VERSION "10.9.1"

NS_ :

BS_:

BU_: ADAS_Info AMP CPD DUMMY_DEBUG DUMMY_ECU EASC HUD MHU XGW_Info

BO_ 389 VCU_FS_C: 8 XGW_Info
 SG_ VCU_FS_C_1 : 0|1@0+ (1,0) [0|1] ""  MHU
 SG_ VCU_FS_C_2 : 1|1@0+ (1,0) [0|1] ""  MHU
 SG_ VCU_FS_C_3 : 2|1@0+ (1,0) [0|1] ""  MHU
 SG_ VCU_FS_C_4 : 3|1@0+ (1,0) [0|1] ""  MHU
 SG_ VCU_FS_C_5 : 4|1@0+ (1,0) [0|1] ""  MHU
 SG_ VCU_FS_C_6 : 5|1@0+ (1,0) [0|1] ""  MHU
 SG_ VCU_FS_C_7 : 6|1@0+ (1,0) [0|1] ""  MHU
 SG_ VCU_FS_C_8 : 7|1@0+ (1,0) [0|1] ""  MHU
 SG_ VCU_FS_C_9 : 8|1@0+ (1,0) [0|1] ""  MHU
 SG_ VCU_FS_C_10 : 9|1@0+ (1,0) [0|1] ""  MHU
 SG_ VCU_FS_C_11 : 10|1@0+ (1,0) [0|1] ""  MHU
 SG_ VCU_FS_C_12 : 11|1@0+ (1,0) [0|1] ""  MHU
 SG_ VCU_FS_C_13 : 12|1@0+ (1,0) [0|1] ""  MHU
 SG_ VCU_FS_C_14 : 13|1@0+ (1,0) [0|1] ""  MHU
 SG_ VCU_FS_C_15 : 14|1@0+ (1,0) [0|1] ""  MHU
 SG_ VCU_FS_C_16 : 15|1@0+ (1,0) [0|1] ""  MHU
 SG_ VCU_FS_C_17 : 16|1@0+ (1,0) [0|1] ""  MHU
 SG_ VCU_FS_C_18 : 17|1@0+ (1,0) [0|1] ""  MHU
 SG_ VCU_FS_C_19 : 18|1@0+ (1,0) [0|1] ""  MHU
 SG_ VCU_FS_C_20 : 19|1@0+ (1,0) [0|1] ""  MHU
 SG_ VCU_FS_C_21 : 20|1@0+ (1,0) [0|1] ""  MHU
 SG_ VCU_FS_C_22 : 21|1@0+ (1,0) [0|1] ""  MHU
 SG_ VCU_FS_C_23 : 22|1@0+ (1,0) [0|1] ""  MHU
 SG_ VCU_FS_C_24 : 23|1@0+ (1,0) [0|1] ""  MHU
 SG_ VCU_FS_C_25 : 24|1@0+ (1,0) [0|1] ""  MHU
 SG_ VCU_FS_C_26 : 25|1@0+ (1,0) [0|1] ""  MHU
 SG_ VCU_FS_C_27 : 26|1@0+ (1,0) [0|1] ""  MHU
 SG_ VCU_FS_C_28 : 27|1@0+ (1,0) [0|1] ""  MHU
 SG_ VCU_FS_C_29 : 28|1@0+ (1,0) [0|1] ""  MHU
 SG_ VCU_FS_C_30 : 29|1@0+ (1,0) [0|1] ""  MHU
 SG_ VCU_FS_C_31 : 30|1@0+ (1,0) [0|1] ""  MHU
 SG_ VCU_FS_C_32 : 31|1@0+ (1,0) [0|1] ""  MHU
 SG_ VCU_FS_C_33 : 32|1@0+ (1,0) [0|1] ""  MHU
 SG_ VCU_FS_C_34 : 33|1@0+ (1,0) [0|1] ""  MHU
 SG_ VCU_FS_C_35 : 34|1@0+ (1,0) [0|1] ""  MHU
 SG_ VCU_FS_C_36 : 35|1@0+ (1,0) [0|1] ""  MHU
 SG_ VCU_FS_C_37 : 36|1@0+ (1,0) [0|1] ""  MHU
 SG_ VCU_FS_C_38 : 37|1@0+ (1,0) [0|1] ""  MHU
 SG_ VCU_FS_C_39 : 38|1@0+ (1,0) [0|1] ""  MHU
 SG_ VCU_FS_C_40 : 39|1@0+ (1,0) [0|1] ""  MHU
 SG_ VCU_FS_C_41 : 40|1@0+ (1,0) [0|1] ""  MHU
 SG_ VCU_FS_C_42 : 41|1@0+ (1,0) [0|1] ""  MHU
 SG_ VCU_FS_C_43 : 42|1@0+ (1,0) [0|1] ""  MHU
 SG_ VCU_FS_C_44 : 43|1@0+ (1,0) [0|1] ""  MHU
 SG_ VCU_FS_C_45 : 44|1@0+ (1,0) [0|1] ""  MHU
 SG_ VCU_FS_C_46 : 45|1@0+ (1,0) [0|1] ""  MHU
 SG_ VCU_FS_C_47 : 46|1@0+ (1,0) [0|1] ""  MHU
 SG_ VCU_FS_C_48 : 47|1@0+ (1,0) [0|1] ""  MHU
 SG_ VCU_FS_C_49 : 48|1@0+ (1,0) [0|1] ""  MHU
 SG_ VCU_FS_C_50 : 49|1@0+ (1,0) [0|1] ""  MHU
 SG_ VCU_FS_C_51 : 50|1@0+ (1,0) [0|1] ""  MHU
 SG_ VCU_FS_C_52 : 51|1@0+ (1,0) [0|1] ""  MHU
 SG_ VCU_FS_C_53 : 52|1@0+ (1,0) [0|1] ""  MHU
 SG_ VCU_FS_C_54 : 53|1@0+ (1,0) [0|1] ""  MHU
 SG_ VCU_FS_C_55 : 54|1@0+ (1,0) [0|1] ""  MHU
 SG_ VCU_FS_C_56 : 55|1@0+ (1,0) [0|1] ""  MHU
 SG_ VCU_FS_C_57 : 56|1@0+ (1,0) [0|1] ""  MHU
 SG_ VCU_FS_C_58 : 57|1@0+ (1,0) [0|1] ""  MHU
 SG_ VCU_FS_C_59 : 58|1@0+ (1,0) [0|1] ""  MHU
 SG_ VCU_FS_C_60 : 59|1@0+ (1,0) [0|1] ""  MHU
 SG_ VCU_FS_C_61 : 60|1@0+ (1,0) [0|1] ""  MHU
 SG_ VCU_FS_C_62 : 61|1@0+ (1,0) [0|1] ""  MHU
 SG_ VCU_FS_C_63 : 62|1@0+ (1,0) [0|1] ""  MHU
 SG_ VCU_FS_C_64 : 63|1@0+ (1,0) [0|1] ""  MHU

BO_ 409 VCU_Sts1: 8 XGW_Info
  SG_ CHSKM_VCU_Sts1 : 7|8@0+ (1,0) [0|255] "" MHU
  SG_ ALV_VCU_Sts1 : 11|4@0+ (1,0) [0|14] "" MHU
  SG_ VCU_BMS_HVOnOff_REQ : 19|2@0+ (1,0) [0|1] "" MHU

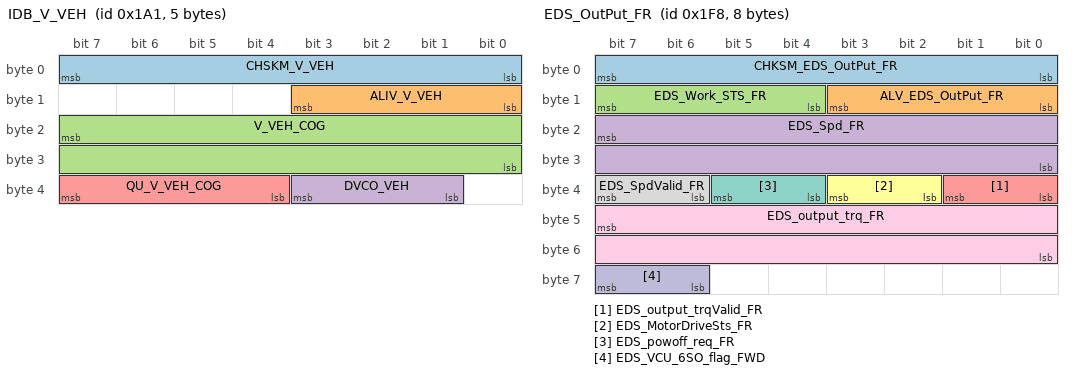
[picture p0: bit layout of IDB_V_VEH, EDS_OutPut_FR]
BO_ 417 IDB_V_VEH: 5 XGW_Info
  SG_ CHSKM_V_VEH : 7|8@0+ (1,0) [0|255] "" MHU
  SG_ ALIV_V_VEH : 11|4@0+ (1,0) [0|14] "" MHU
  SG_ V_VEH_COG : 23|16@0+ (0.015625,0) [0|350] "km/h" MHU
  SG_ DVCO_VEH : 35|3@0+ (1,0) [0|7] "" MHU
  SG_ QU_V_VEH_COG : 39|4@0+ (1,0) [0|15] "" MHU

BO_ 504 EDS_OutPut_FR: 8 XGW_Info
  SG_ CHKSM_EDS_OutPut_FR : 7|8@0+ (1,0) [0|255] "" ADAS_Info,AMP,CPD,EASC,HUD,MHU
  SG_ ALV_EDS_OutPut_FR : 11|4@0+ (1,0) [0|14] "" ADAS_Info,AMP,CPD,EASC,HUD,MHU
  SG_ EDS_Work_STS_FR : 15|4@0+ (1,0) [0|15] "-" ADAS_Info,AMP,CPD,EASC,HUD,MHU
  SG_ EDS_Spd_FR : 23|16@0+ (1,-20000) [-20000|20000] "rpm" ADAS_Info,AMP,CPD,EASC,HUD,MHU
  SG_ EDS_output_trqValid_FR : 33|2@0+ (1,0) [0|1] "" ADAS_Info,AMP,CPD,EASC,HUD,MHU
  SG_ EDS_MotorDriveSts_FR : 35|2@0+ (1,0) [0|3] "" ADAS_Info,AMP,CPD,EASC,HUD,MHU
  SG_ EDS_powoff_req_FR : 37|2@0+ (1,0) [0|1] "" ADAS_Info,AMP,CPD,EASC,HUD,MHU
  SG_ EDS_SpdValid_FR : 39|2@0+ (1,0) [0|1] "" ADAS_Info,AMP,CPD,EASC,HUD,MHU
  SG_ EDS_output_trq_FR : 47|16@0+ (1,-2000) [-2000|2000] "Nm" ADAS_Info,AMP,CPD,EASC,HUD,MHU
  SG_ EDS_VCU_6SO_flag_FWD : 63|2@0+ (1,0) [0|1] "" ADAS_Info,AMP,CPD,EASC,HUD,MHU

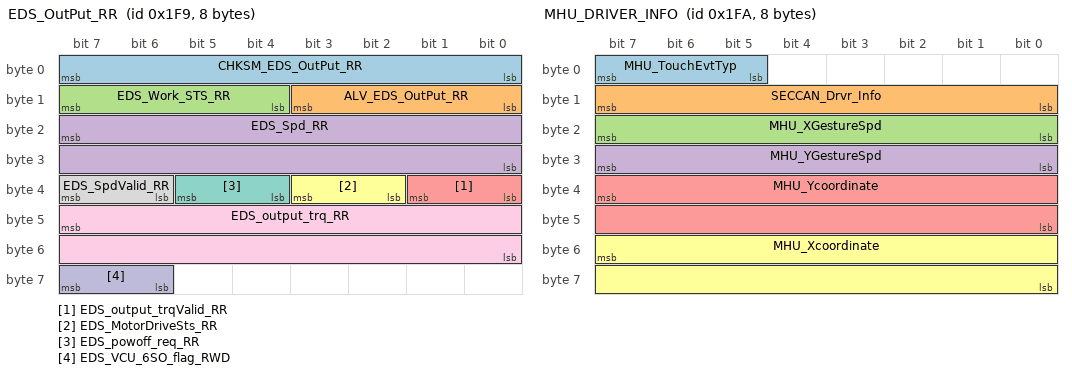
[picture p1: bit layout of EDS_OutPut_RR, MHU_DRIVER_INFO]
BO_ 505 EDS_OutPut_RR: 8 XGW_Info
  SG_ CHKSM_EDS_OutPut_RR : 7|8@0+ (1,0) [0|255] "" ADAS_Info,AMP,CPD,EASC,HUD,MHU
  SG_ ALV_EDS_OutPut_RR : 11|4@0+ (1,0) [0|14] "" ADAS_Info,AMP,CPD,EASC,HUD,MHU
  SG_ EDS_Work_STS_RR : 15|4@0+ (1,0) [0|15] "-" ADAS_Info,AMP,CPD,EASC,HUD,MHU
  SG_ EDS_Spd_RR : 23|16@0+ (1,-20000) [-20000|20000] "rpm" ADAS_Info,AMP,CPD,EASC,HUD,MHU
  SG_ EDS_output_trqValid_RR : 33|2@0+ (1,0) [0|1] "" ADAS_Info,AMP,CPD,EASC,HUD,MHU
  SG_ EDS_MotorDriveSts_RR : 35|2@0+ (1,0) [0|3] "" ADAS_Info,AMP,CPD,EASC,HUD,MHU
  SG_ EDS_powoff_req_RR : 37|2@0+ (1,0) [0|1] "" ADAS_Info,AMP,CPD,EASC,HUD,MHU
  SG_ EDS_SpdValid_RR : 39|2@0+ (1,0) [0|1] "" ADAS_Info,AMP,CPD,EASC,HUD,MHU
  SG_ EDS_output_trq_RR : 47|16@0+ (1,-2000) [-2000|2000] "Nm" ADAS_Info,AMP,CPD,EASC,HUD,MHU
  SG_ EDS_VCU_6SO_flag_RWD : 63|2@0+ (1,0) [0|1] "-" ADAS_Info,AMP,CPD,EASC,HUD,MHU

BO_ 506 MHU_DRIVER_INFO: 8 MHU
  SG_ MHU_TouchEvtTyp : 7|3@0+ (1,0) [0|7] "-" ADAS_Info
  SG_ SECCAN_Drvr_Info : 15|8@0+ (1,0) [0|255] "" ADAS_Info
  SG_ MHU_XGestureSpd : 23|8@0+ (1,0) [0|255] "-" ADAS_Info
  SG_ MHU_YGestureSpd : 31|8@0+ (1,0) [0|255] "-" ADAS_Info
  SG_ MHU_Ycoordinate : 39|16@0+ (1,0) [0|65535] "-" ADAS_Info
  SG_ MHU_Xcoordinate : 55|16@0+ (1,0) [0|65535] "-" ADAS_Info

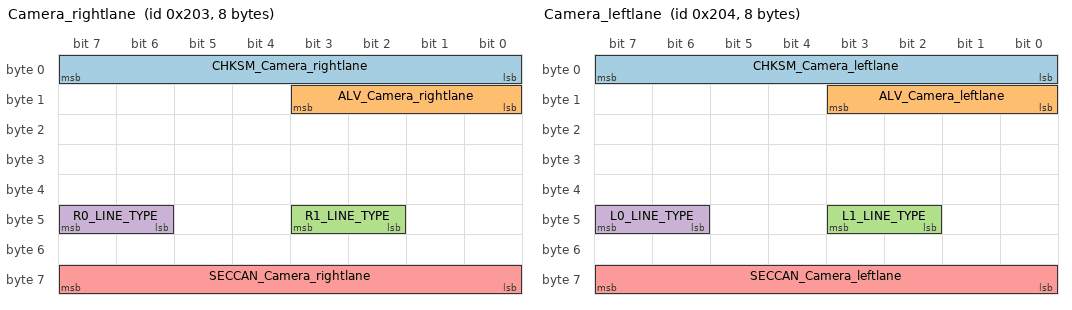
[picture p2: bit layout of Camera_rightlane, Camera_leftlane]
BO_ 515 Camera_rightlane: 8 ADAS_Info
  SG_ CHKSM_Camera_rightlane : 7|8@0+ (1,0) [0|255] "" MHU
  SG_ ALV_Camera_rightlane : 11|4@0+ (1,0) [0|14] "" MHU
  SG_ R1_LINE_TYPE : 43|2@0+ (1,0) [0|3] "-" MHU
  SG_ R0_LINE_TYPE : 47|2@0+ (1,0) [0|3] "-" MHU
  SG_ SECCAN_Camera_rightlane : 63|8@0+ (1,0) [0|255] "" MHU

BO_ 516 Camera_leftlane: 8 ADAS_Info
  SG_ CHKSM_Camera_leftlane : 7|8@0+ (1,0) [0|255] "" MHU
  SG_ ALV_Camera_leftlane : 11|4@0+ (1,0) [0|14] "" MHU
  SG_ L1_LINE_TYPE : 43|2@0+ (1,0) [0|3] "-" MHU
  SG_ L0_LINE_TYPE : 47|2@0+ (1,0) [0|3] "-" MHU
  SG_ SECCAN_Camera_leftlane : 63|8@0+ (1,0) [0|255] "" MHU

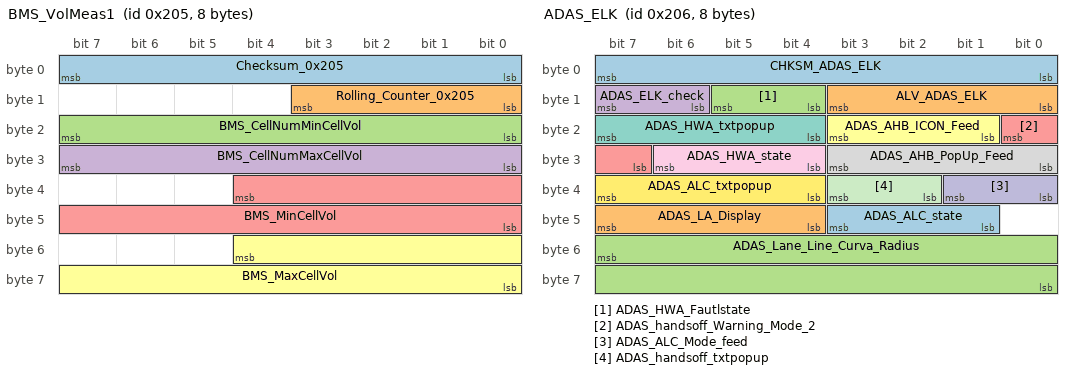
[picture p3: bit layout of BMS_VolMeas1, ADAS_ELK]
BO_ 517 BMS_VolMeas1: 8 XGW_Info
  SG_ Checksum_0x205 : 7|8@0+ (1,0) [0|255] "" MHU
  SG_ Rolling_Counter_0x205 : 11|4@0+ (1,0) [0|14] "" MHU
  SG_ BMS_CellNumMinCellVol : 23|8@0+ (1,0) [0|255] "" MHU
  SG_ BMS_CellNumMaxCellVol : 31|8@0+ (1,0) [0|255] "" MHU
  SG_ BMS_MinCellVol : 36|13@0+ (0.001,0) [0|6] "V" MHU
  SG_ BMS_MaxCellVol : 52|13@0+ (0.001,0) [0|6] "V" MHU

BO_ 518 ADAS_ELK: 8 ADAS_Info
  SG_ CHKSM_ADAS_ELK : 7|8@0+ (1,0) [0|255] "" HUD,MHU
  SG_ ALV_ADAS_ELK : 11|4@0+ (1,0) [0|14] "" HUD,MHU
  SG_ ADAS_HWA_Fautlstate : 13|2@0+ (1,0) [0|3] "-" HUD,MHU
  SG_ ADAS_ELK_check : 15|2@0+ (1,0) [0|3] "-" HUD,MHU
  SG_ ADAS_handsoff_Warning_Mode_2 : 16|2@0+ (1,0) [0|3] "-" HUD,MHU
  SG_ ADAS_AHB_ICON_Feed : 19|3@0+ (1,0) [0|7] "-" HUD,MHU
  SG_ ADAS_HWA_txtpopup : 23|4@0+ (1,0) [0|15] "-" HUD,MHU
  SG_ ADAS_AHB_PopUp_Feed : 27|4@0+ (1,0) [0|15] "-" HUD,MHU
  SG_ ADAS_HWA_state : 30|3@0+ (1,0) [0|7] "-" HUD,MHU
  SG_ ADAS_ALC_Mode_feed : 33|2@0+ (1,0) [0|3] "-" HUD,MHU
  SG_ ADAS_handsoff_txtpopup : 35|2@0+ (1,0) [0|3] "-" HUD,MHU
  SG_ ADAS_ALC_txtpopup : 39|4@0+ (1,0) [0|15] "-" HUD,MHU
  SG_ ADAS_ALC_state : 43|3@0+ (1,0) [0|7] "-" HUD,MHU
  SG_ ADAS_LA_Display : 47|4@0+ (1,0) [0|15] "-" HUD,MHU
  SG_ ADAS_Lane_Line_Curva_Radius : 55|16@0- (1,0) [-32768|32767] "m" HUD,MHU

BO_ 519 BCM_SunroofSts: 8 XGW_Info
  SG_ SR_Undervoltage_Fault_Sts : 0|1@0+ (1,0) [0|1] "" MHU
  SG_ SR_Overvoltage_Fault_Sts : 1|1@0+ (1,0) [0|1] "" MHU
  SG_ SR_SLEEP_RQ : 2|1@0+ (1,0) [0|1] "-" MHU
  SG_ SR_Position : 5|3@0+ (1,0) [0|7] "" CPD,MHU
  SG_ SR_Motor_Running_Sts : 7|2@0+ (1,0) [0|3] "" MHU
  SG_ SR_MotorReverse_Fault_Sts : 8|1@0+ (1,0) [0|1] "" MHU
  SG_ SR_Hall_Fault_Sts : 9|1@0+ (1,0) [0|1] "" MHU
  SG_ SR_Normalisation_Sts : 10|1@0+ (1,0) [0|1] "" MHU
  SG_ SR_Relay_Fault : 11|1@0+ (1,0) [0|1] "" MHU
  SG_ SR_Commu_Fault_Sts : 12|1@0+ (1,0) [0|1] "" MHU
  SG_ SR_Initialisation_Status : 13|1@0+ (1,0) [0|1] "" MHU
  SG_ SR_Ctrl_Result : 15|2@0+ (1,0) [0|3] "" MHU
  SG_ SR_ThermalProtection_Fault_Sts : 16|1@0+ (1,0) [0|1] "-" MHU
  SG_ SR_Posit_Percentage : 23|7@0+ (1,0) [0|100] "%" CPD,MHU
  SG_ SR_Operation_Stat : 27|4@0+ (1,0) [0|8] "-" MHU
  SG_ SR_Error_RSP : 28|1@0+ (1,0) [0|1] "" MHU
  SG_ BCM_AutoSunroof_Sts : 30|2@0+ (1,0) [0|3] ""  MHU

BO_ 520 BCM_SunshadeSts: 8 XGW_Info
  SG_ SS_MotorReverse_Fault_Status : 0|1@0+ (1,0) [0|1] "" MHU
  SG_ SS_Motor_Running_Status : 2|2@0+ (1,0) [0|3] "" MHU
  SG_ SS_Position : 5|3@0+ (1,0) [0|7] "" MHU
  SG_ SS_SLEEP_RQ : 6|1@0+ (1,0) [0|1] "-" MHU
  SG_ SS_Undervoltage_Fault_Status : 7|1@0+ (1,0) [0|1] "" MHU
  SG_ SS_Ctrl_Result : 9|2@0+ (1,0) [0|3] "" MHU
  SG_ SS_Overvoltage_Fault_Status : 10|1@0+ (1,0) [0|1] "" MHU
  SG_ SS_Relay_Fault : 11|1@0+ (1,0) [0|1] "" MHU
  SG_ SS_Normalisation_Status : 12|1@0+ (1,0) [0|1] "" MHU
  SG_ SS_Hall_Fault_Status : 13|1@0+ (1,0) [0|1] "" MHU
  SG_ SS_Commu_Fault_Status : 14|1@0+ (1,0) [0|1] "" MHU
  SG_ SS_Initialisation_Status : 15|1@0+ (1,0) [0|1] "" MHU
  SG_ SS_Posit_Percentage : 22|7@0+ (1,0) [0|100] "%" MHU
  SG_ SS_ThermalProtection_Flt_Sts : 23|1@0+ (1,0) [0|1] "" MHU
  SG_ SS_Operation_State : 31|3@0+ (1,0) [0|7] "" MHU
  SG_ SECCAN_SunshadeSts : 55|8@0+ (1,0) [0|255] "" MHU
  SG_ SS_Error_RSP : 63|1@0+ (1,0) [0|1] "" MHU

BO_ 522 ETG_STATUS: 8 XGW_Info
  SG_ ETG_Lift_Gate_Status : 2|3@0+ (1,0) [0|7] "-" MHU
  SG_ ETG_Power_Latch_Status : 5|3@0+ (1,0) [0|7] "-" MHU
  SG_ ETG_Latch_Segment : 7|2@0+ (1,0) [0|3] "" MHU
  SG_ ETG_Opening_Percentage : 15|8@0+ (1,0) [0|100] "%" MHU
  SG_ ETG_DSW_Status : 16|1@0+ (1,0) [0|1] "" MHU
  SG_ ETG_GSW_Status : 17|1@0+ (1,0) [0|1] "" MHU
  SG_ ETG_LTS_Status : 18|1@0+ (1,0) [0|1] "-" MHU
  SG_ ETG_RTS_Status : 19|1@0+ (1,0) [0|1] "-" MHU
  SG_ ETG_HAL_Status : 20|1@0+ (1,0) [0|1] "-" MHU
  SG_ ETG_FUL_Status : 21|1@0+ (1,0) [0|1] "-" MHU
  SG_ ETG_AJR_Status : 22|1@0+ (1,0) [0|1] "" MHU
  SG_ ETG_NTL_Status : 23|1@0+ (1,0) [0|1] "-" MHU
  SG_ ETG_ERR_Voltage : 25|2@0+ (1,0) [0|3] "-" MHU
  SG_ ETG_ERR_Left_Motor : 27|2@0+ (1,0) [0|3] "" MHU
  SG_ ETG_ERR_Right_Motor : 29|2@0+ (1,0) [0|3] "-" MHU
  SG_ ETG_ERR_Latch : 31|2@0+ (1,0) [0|3] "-" MHU
  SG_ ETG_ERR_Hall : 33|2@0+ (1,0) [0|3] "" MHU
  SG_ ETG_Lift_Motor_Stall : 34|1@0+ (1,0) [0|1] "" MHU
  SG_ ETG_Lift_Motor_AntiPinch : 35|1@0+ (1,0) [0|1] "-" MHU
  SG_ ETG_Lift_Motor_Thermal : 36|1@0+ (1,0) [0|1] "" MHU
  SG_ ETG_Power_Latch_Thermal : 37|1@0+ (1,0) [0|1] "-" MHU
  SG_ ETG_Abuse_Protection : 38|1@0+ (1,0) [0|1] "" MHU

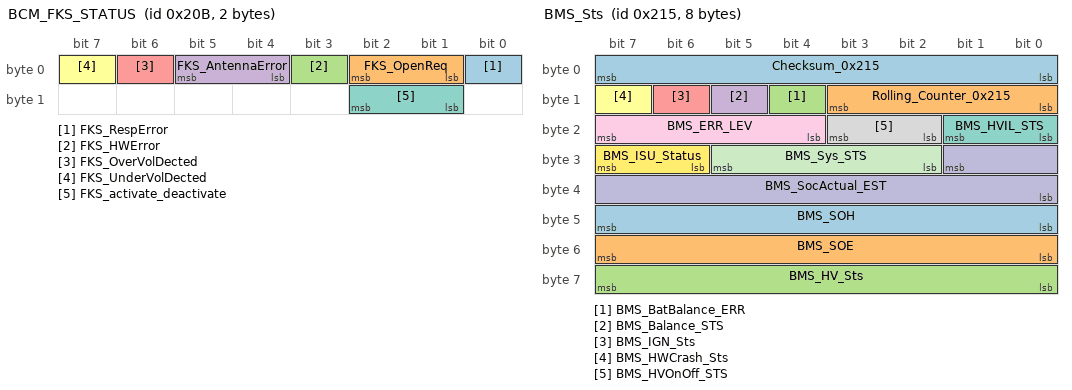
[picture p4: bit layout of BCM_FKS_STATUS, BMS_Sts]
BO_ 523 BCM_FKS_STATUS: 2 XGW_Info
  SG_ FKS_RespError : 0|1@0+ (1,0) [0|1] "-" MHU
  SG_ FKS_OpenReq : 2|2@0+ (1,0) [0|3] "" MHU
  SG_ FKS_HWError : 3|1@0+ (1,0) [0|1] "-" MHU
  SG_ FKS_AntennaError : 5|2@0+ (1,0) [0|3] "-" MHU
  SG_ FKS_OverVolDected : 6|1@0+ (1,0) [0|1] "-" MHU
  SG_ FKS_UnderVolDected : 7|1@0+ (1,0) [0|1] "-" MHU
  SG_ FKS_activate_deactivate : 10|2@0+ (1,0) [0|3] "-" MHU

BO_ 524 IC_ODO: 8 MHU
  SG_ CHKSM_IC_ODO : 7|8@0+ (1,0) [0|255] "" HUD,XGW_Info
  SG_ ALIV_IC_ODO : 11|4@0+ (1,0) [0|14] "" HUD,XGW_Info
  SG_ MHU_Odometer_IC : 23|20@0+ (1,0) [0|999999] "km" HUD,XGW_Info

BO_ 525 IDB_STATUS: 8 XGW_Info
  SG_ CHKSM_IDB_STATUS : 7|8@0+ (1,0) [0|255] "" ADAS_Info,AMP,CPD,EASC,HUD,MHU
  SG_ ALV_IDB_STATUS : 11|4@0+ (1,0) [0|14] "" ADAS_Info,AMP,CPD,EASC,HUD,MHU
  SG_ ESPTransRequestType : 13|2@0+ (1,0) [0|3] "" ADAS_Info,AMP,CPD,EASC,HUD,MHU
  SG_ ABSFault : 14|1@0+ (1,0) [0|1] "" ADAS_Info,AMP,CPD,EASC,HUD,MHU
  SG_ ABSActive : 15|1@0+ (1,0) [0|1] "" ADAS_Info,AMP,CPD,EASC,HUD,MHU
  SG_ VehicleSpd : 23|13@0+ (0.05625,0) [0|300] "km/h" ADAS_Info,AMP,CPD,EASC,HUD,MHU
  SG_ ESC_VehicleStandstill : 24|1@0+ (1,0) [0|1] "" ADAS_Info,AMP,CPD,EASC,HUD,MHU
  SG_ MCPressureSts : 25|1@0+ (1,0) [0|1] "" ADAS_Info,AMP,CPD,EASC,HUD,MHU
  SG_ VehicleSpdSts : 26|1@0+ (1,0) [0|1] "" ADAS_Info,AMP,CPD,EASC,HUD,MHU
  SG_ MCPressure : 39|8@0+ (2,-42.5) [-42.5|465.5] "bar" ADAS_Info,AMP,CPD,EASC,HUD,MHU
  SG_ ESC_Braking_effort : 40|1@0+ (1,0) [0|1] "" ADAS_Info,AMP,CPD,EASC,HUD,MHU
  SG_ BRAKE_LightonRequestEPBi : 42|2@0+ (1,0) [0|3] "" ADAS_Info,AMP,CPD,EASC,HUD,MHU
  SG_ VDCActive : 43|1@0+ (1,0) [0|1] "" ADAS_Info,AMP,CPD,EASC,HUD,MHU
  SG_ TCSActive : 44|1@0+ (1,0) [0|1] "" ADAS_Info,AMP,CPD,EASC,HUD,MHU
  SG_ TCSAvailable : 45|1@0+ (1,0) [0|1] "" ADAS_Info,AMP,CPD,EASC,HUD,MHU
  SG_ IDBActive : 46|1@0+ (1,0) [0|1] "" ADAS_Info,AMP,CPD,EASC,HUD,MHU
  SG_ IDBFault : 47|1@0+ (1,0) [0|1] "" ADAS_Info,AMP,CPD,EASC,HUD,MHU
  SG_ ESC_VehicleHoldStat : 51|2@0+ (1,0) [0|3] "" ADAS_Info,AMP,CPD,EASC,HUD,MHU
  SG_ IDB_Power_Stage : 55|4@0+ (1,0) [0|15] "" ADAS_Info,AMP,CPD,EASC,HUD,MHU
  SG_ ESC_BrakeReleasedFailsafe : 56|1@0+ (1,0) [0|1] "" ADAS_Info,AMP,CPD,EASC,HUD,MHU

BO_ 526 BMS_FaultInfo: 8 XGW_Info
 SG_ BMS_faultnumber : 7|64@0+ (1,0) [0|1.84467E+019] ""  MHU

BO_ 531 VCU_POD_reqDCDC: 8 XGW_Info
  SG_ CHSKM_VCU_POD_reqDCDC : 7|8@0+ (1,0) [0|255] "" MHU
  SG_ ALV_VCU_POD_reqDCDC : 11|4@0+ (1,0) [0|14] "" MHU
  SG_ VCU_enableDCDC : 13|2@0+ (1,0) [0|3] "" MHU
  SG_ VCU_vDCDCRequest : 23|16@0+ (0.0625,0) [9|16] "V" MHU
  SG_ VCU_iDCDCRequest_lim : 39|16@0+ (0.0625,0) [0|300] "A" MHU

BO_ 532 BMS_Sts_0x214: 8 XGW_Info
  SG_ Checksum_0x214 : 7|8@0+ (1,0) [0|255] "" MHU
  SG_ Rolling_Counter_0x214 : 11|4@0+ (1,0) [0|14] "" MHU
  SG_ BMS_Display_SOC : 21|10@0+ (0.1,0) [0|100] "%" MHU
  SG_ BMS_SOCE : 27|14@0+ (0.01,0) [0|100] "%" MHU

BO_ 533 BMS_Sts: 8 XGW_Info
  SG_ Checksum_0x215 : 7|8@0+ (1,0) [0|255] "" HUD,MHU
  SG_ Rolling_Counter_0x215 : 11|4@0+ (1,0) [0|14] "" HUD,MHU
  SG_ BMS_BatBalance_ERR : 12|1@0+ (1,0) [0|1] "" HUD,MHU
  SG_ BMS_Balance_STS : 13|1@0+ (1,0) [0|1] "" HUD,MHU
  SG_ BMS_IGN_Sts : 14|1@0+ (1,0) [0|1] "" HUD,MHU
  SG_ BMS_HWCrash_Sts : 15|1@0+ (1,0) [0|1] "" HUD,MHU
  SG_ BMS_HVIL_STS : 17|2@0+ (1,0) [0|3] "" HUD,MHU
  SG_ BMS_HVOnOff_STS : 19|2@0+ (1,0) [0|3] "" HUD,MHU
  SG_ BMS_ERR_LEV : 23|4@0+ (1,0) [0|7] "-" HUD,MHU
  SG_ BMS_SocActual_EST : 25|10@0+ (0.1,0) [0|100] "%" HUD,MHU
  SG_ BMS_Sys_STS : 29|4@0+ (1,0) [0|15] "" HUD,MHU
  SG_ BMS_ISU_Status : 31|2@0+ (1,0) [0|3] "" HUD,MHU
  SG_ BMS_SOH : 47|8@0+ (0.5,0) [0|100] "%" HUD,MHU
  SG_ BMS_SOE : 55|8@0+ (0.5,0) [0|100] "%" HUD,MHU
  SG_ BMS_HV_Sts : 63|8@0+ (1,0) [0|255] "" HUD,MHU

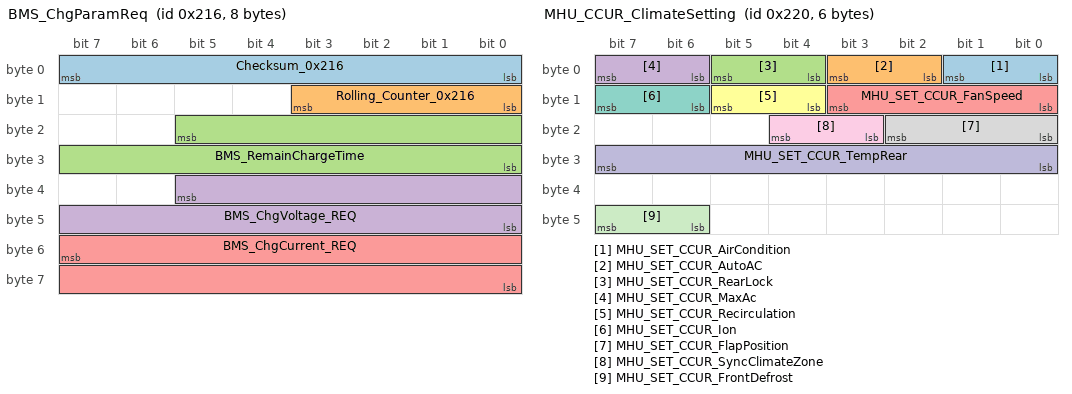
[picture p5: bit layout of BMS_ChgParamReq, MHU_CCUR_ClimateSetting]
BO_ 534 BMS_ChgParamReq: 8 XGW_Info
  SG_ Checksum_0x216 : 7|8@0+ (1,0) [0|255] "" MHU
  SG_ Rolling_Counter_0x216 : 11|4@0+ (1,0) [0|14] "" MHU
  SG_ BMS_RemainChargeTime : 21|14@0+ (1,0) [0|16383] "min" MHU
  SG_ BMS_ChgVoltage_REQ : 37|14@0+ (0.1,0) [0|800] "V" MHU
  SG_ BMS_ChgCurrent_REQ : 55|16@0+ (0.1,0) [0|1500] "A" MHU

BO_ 544 MHU_CCUR_ClimateSetting: 6 MHU
  SG_ MHU_SET_CCUR_AirCondition : 1|2@0+ (1,0) [0|3] "-" XGW_Info
  SG_ MHU_SET_CCUR_AutoAC : 3|2@0+ (1,0) [0|3] "-" XGW_Info
  SG_ MHU_SET_CCUR_RearLock : 5|2@0+ (1,0) [0|3] "-" XGW_Info
  SG_ MHU_SET_CCUR_MaxAc : 7|2@0+ (1,0) [0|3] "" XGW_Info
  SG_ MHU_SET_CCUR_FanSpeed : 11|4@0+ (1,0) [0|7] "-" XGW_Info
  SG_ MHU_SET_CCUR_Recirculation : 13|2@0+ (1,0) [0|3] "-" XGW_Info
  SG_ MHU_SET_CCUR_Ion : 15|2@0+ (1,0) [0|3] "" XGW_Info
  SG_ MHU_SET_CCUR_FlapPosition : 18|3@0+ (1,0) [0|7] "-" XGW_Info
  SG_ MHU_SET_CCUR_SyncClimateZone : 20|2@0+ (1,0) [0|3] "-" XGW_Info
  SG_ MHU_SET_CCUR_TempRear : 31|8@0+ (0.5,0) [16|32] "Degree C" XGW_Info
  SG_ MHU_SET_CCUR_FrontDefrost : 47|2@0+ (1,0) [0|3] "" XGW_Info

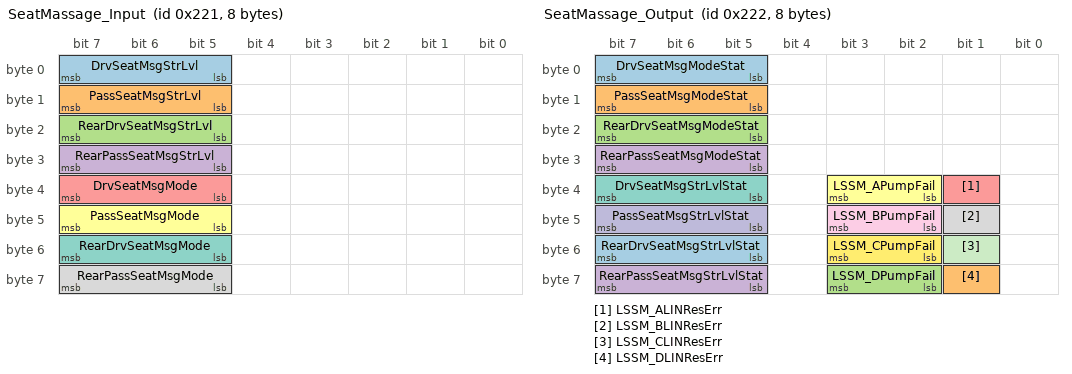
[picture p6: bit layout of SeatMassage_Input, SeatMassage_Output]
BO_ 545 SeatMassage_Input: 8 MHU
  SG_ DrvSeatMsgStrLvl : 7|3@0+ (1,0) [0|7] "" XGW_Info
  SG_ PassSeatMsgStrLvl : 15|3@0+ (1,0) [0|7] "" XGW_Info
  SG_ RearDrvSeatMsgStrLvl : 23|3@0+ (1,0) [0|7] "-" XGW_Info
  SG_ RearPassSeatMsgStrLvl : 31|3@0+ (1,0) [0|7] "" XGW_Info
  SG_ DrvSeatMsgMode : 39|3@0+ (1,0) [0|7] "" XGW_Info
  SG_ PassSeatMsgMode : 47|3@0+ (1,0) [0|7] "" XGW_Info
  SG_ RearDrvSeatMsgMode : 55|3@0+ (1,0) [0|7] "" XGW_Info
  SG_ RearPassSeatMsgMode : 63|3@0+ (1,0) [0|7] "-" XGW_Info

BO_ 546 SeatMassage_Output: 8 XGW_Info
  SG_ DrvSeatMsgModeStat : 7|3@0+ (1,0) [0|7] "" MHU
  SG_ PassSeatMsgModeStat : 15|3@0+ (1,0) [0|7] "" MHU
  SG_ RearDrvSeatMsgModeStat : 23|3@0+ (1,0) [0|7] "" MHU
  SG_ RearPassSeatMsgModeStat : 31|3@0+ (1,0) [0|7] "" MHU
  SG_ LSSM_ALINResErr : 33|1@0+ (1,0) [0|1] "" MHU
  SG_ LSSM_APumpFail : 35|2@0+ (1,0) [0|3] "" MHU
  SG_ DrvSeatMsgStrLvlStat : 39|3@0+ (1,0) [0|7] "" MHU
  SG_ LSSM_BLINResErr : 41|1@0+ (1,0) [0|1] "" MHU
  SG_ LSSM_BPumpFail : 43|2@0+ (1,0) [0|3] "" MHU
  SG_ PassSeatMsgStrLvlStat : 47|3@0+ (1,0) [0|7] "-" MHU
  SG_ LSSM_CLINResErr : 49|1@0+ (1,0) [0|1] "" MHU
  SG_ LSSM_CPumpFail : 51|2@0+ (1,0) [0|3] "-" MHU
  SG_ RearDrvSeatMsgStrLvlStat : 55|3@0+ (1,0) [0|7] "-" MHU
  SG_ LSSM_DLINResErr : 57|1@0+ (1,0) [0|1] "" MHU
  SG_ LSSM_DPumpFail : 59|2@0+ (1,0) [0|3] "-" MHU
  SG_ RearPassSeatMsgStrLvlStat : 63|3@0+ (1,0) [0|7] "" MHU

BO_ 549 BMS_FaultMgr_0x225: 8 XGW_Info
  SG_ Checksum_0x225 : 7|8@0+ (1,0) [0|255] "" MHU
  SG_ Rolling_Counter_0x225 : 11|4@0+ (1,0) [0|14] "" MHU
  SG_ CDM_bAcvCanComStblMon : 12|1@0+ (1,0) [0|1] "" MHU
  SG_ FRMo_bErrHvbatStReqExtMon : 13|1@0+ (1,0) [0|1] "" MHU
  SG_ FRMo_bErrChrgnAllwdExtMon : 14|1@0+ (1,0) [0|1] "" MHU
  SG_ FRMo_bErrVehCrashStExtMon : 15|1@0+ (1,0) [0|1] "" MHU
  SG_ CDM_bErrComctnLossCanMon : 16|1@0+ (1,0) [0|1] "" MHU
  SG_ CTCMon_bErrCtctrSopcMon : 17|1@0+ (1,0) [0|1] "" MHU
  SG_ CTCMon_bInvldCtctrHisdIFbMon : 18|1@0+ (1,0) [0|1] "" MHU
  SG_ CTCMon_bInvldCtctrLosdUFbMon : 19|1@0+ (1,0) [0|1] "" MHU
  SG_ CTM_bErrCellTDifMaxMon : 20|1@0+ (1,0) [0|1] "" MHU
  SG_ CTM_bErrCellTMaxMon : 21|1@0+ (1,0) [0|1] "" MHU
  SG_ CTM_bErrCellTMinMon : 22|1@0+ (1,0) [0|1] "" MHU
  SG_ CTM_bErrThrwyPredMon : 23|1@0+ (1,0) [0|1] "" MHU
  SG_ CUM_bErrCellUDifMaxMon : 24|1@0+ (1,0) [0|1] "" MHU
  SG_ CUM_bErrCellUMaxMon : 25|1@0+ (1,0) [0|1] "" MHU
  SG_ CUM_bErrCellUMinMon : 26|1@0+ (1,0) [0|1] "" MHU
  SG_ CUM_bErrCellUProtnMaxNvMon : 27|1@0+ (1,0) [0|1] "" MHU
  SG_ CUM_bErrCellUProtnMinNvMon : 28|1@0+ (1,0) [0|1] "" MHU
  SG_ CUM_bErrPackUImplyMon : 29|1@0+ (1,0) [0|1] "" MHU
  SG_ EHPMon_bRdyHvilMon : 30|1@0+ (1,0) [0|1] "" MHU
  SG_ EHPMon_bErrWlddNegNvMon : 31|1@0+ (1,0) [0|1] "" MHU
  SG_ EHPMon_bErrWlddPosNvMon : 32|1@0+ (1,0) [0|1] "" MHU
  SG_ EHPMon_bErrWlddPrechNvMon : 33|1@0+ (1,0) [0|1] "" MHU
  SG_ EHPMon_bErrHvilMon : 34|1@0+ (1,0) [0|1] "" MHU
  SG_ EHPMon_bErrHvilShoMon : 35|1@0+ (1,0) [0|1] "" MHU
  SG_ EHPMon_bErrPackIslnRNvMon : 36|1@0+ (1,0) [0|1] "" MHU
  SG_ EHPMon_bErrVehCrashNvMon : 37|1@0+ (1,0) [0|1] "" MHU
  SG_ EHPMon_bErrVehIslnRNvMon : 38|1@0+ (1,0) [0|1] "" MHU
  SG_ FRMo_bErrMemStorgNvMon : 39|1@0+ (1,0) [0|1] "" MHU
  SG_ L1IM_bErrClmp30MaxMonInp : 40|1@0+ (1,0) [0|1] "" MHU
  SG_ L1IM_bErrClmp30MinMonInp : 41|1@0+ (1,0) [0|1] "" MHU
  SG_ L1IM_bErrCtctrDtrtMonInp : 42|1@0+ (1,0) [0|1] "" MHU
  SG_ L1IM_bErrUActImplyMonInp : 43|1@0+ (1,0) [0|1] "" MHU
  SG_ MCCM_bAcvMdulCtlrStsMon : 44|1@0+ (1,0) [0|1] "" MHU
  SG_ MCCM_bErrLntecSngFltMon : 45|1@0+ (1,0) [0|1] "" MHU
  SG_ MCCM_bErrLntecLtntFltMon : 46|1@0+ (1,0) [0|1] "" MHU
  SG_ MCCM_bErrMdulCellSnsrCfgMon : 47|1@0+ (1,0) [0|1] "" MHU
  SG_ MCCM_bErrMdulCtlrComMon : 48|1@0+ (1,0) [0|1] "" MHU
  SG_ MCCM_bErrSnsrTEltlMon : 49|1@0+ (1,0) [0|1] "" MHU
  SG_ MCCM_bWarnSnsrTEltlMon : 50|1@0+ (1,0) [0|1] "" MHU
  SG_ PCM_bRdySnsrIMon : 51|1@0+ (1,0) [0|1] "" MHU
  SG_ PCM_bErrPackEFlowMaxLimMon : 52|1@0+ (1,0) [0|1] "" MHU
  SG_ PCM_bErrPackIChDchaMaxLimMon : 53|1@0+ (1,0) [0|1] "" MHU
  SG_ PCM_bErrSnsrIImplyMon : 54|1@0+ (1,0) [0|1] "" MHU
  SG_ FRMo_bErrSnsrI1ExtMon : 55|1@0+ (1,0) [0|1] "" MHU
  SG_ PCM_bInvldSnsrI1Mon : 56|1@0+ (1,0) [0|1] "" MHU
  SG_ PCM_bInvldSnsrI2Mon : 57|1@0+ (1,0) [0|1] "" MHU
  SG_ FRMo_bErrSopcLvl3Mon : 58|1@0+ (1,0) [0|1] "" MHU
  SG_ BMS_FRMo_Reserved_1 : 59|1@0+ (1,0) [0|1] "" MHU
  SG_ BMS_FRMo_Reserved_2 : 60|1@0+ (1,0) [0|1] "" MHU
  SG_ BMS_FRMo_Reserved_3 : 61|1@0+ (1,0) [0|1] "" MHU
  SG_ BMS_FRMo_Reserved_4 : 62|1@0+ (1,0) [0|1] "" MHU
  SG_ BMS_FRMo_Reserved_5 : 63|1@0+ (1,0) [0|1] "" MHU

BO_ 561 DoorFLStatus: 8 XGW_Info
  SG_ NDoorFLOutsideHandleFailure : 26|3@0+ (1,0) [0|7] "" MHU
  SG_ NDoorLatchFLFailure : 55|6@0+ (1,0) [0|63] "" MHU

BO_ 565 TRM_STATUS: 3 XGW_Info
  SG_ CHKSM_TRM_STATUS : 7|8@0+ (1,0) [0|255] "" HUD,MHU
  SG_ ALIVE_TRM_STATUS : 11|4@0+ (1,0) [0|14] "" HUD,MHU
  SG_ TowingDetected : 21|2@0+ (1,0) [0|3] "" HUD,MHU
  SG_ TrailerDetected : 23|2@0+ (1,0) [0|3] "" HUD,MHU

BO_ 569 DoorRRStatus: 8 XGW_Info
  SG_ NDoorRROutsideHandleFailure : 26|3@0+ (1,0) [0|7] "" MHU
  SG_ NDoorLatchRRFailure : 55|6@0+ (1,0) [0|63] "" MHU

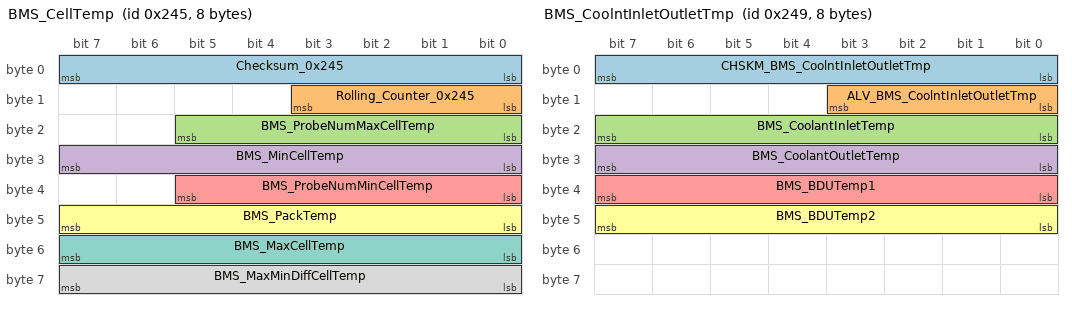
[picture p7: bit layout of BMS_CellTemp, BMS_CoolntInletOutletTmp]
BO_ 581 BMS_CellTemp: 8 XGW_Info
  SG_ Checksum_0x245 : 7|8@0+ (1,0) [0|255] "" MHU
  SG_ Rolling_Counter_0x245 : 11|4@0+ (1,0) [0|14] "" MHU
  SG_ BMS_ProbeNumMaxCellTemp : 21|6@0+ (1,0) [0|63] "" MHU
  SG_ BMS_MinCellTemp : 31|8@0+ (1,-40) [-40|215] "°C" MHU
  SG_ BMS_ProbeNumMinCellTemp : 37|6@0+ (1,0) [0|63] "" MHU
  SG_ BMS_PackTemp : 47|8@0+ (1,-40) [-40|215] "°C" MHU
  SG_ BMS_MaxCellTemp : 55|8@0+ (1,-40) [-40|215] "°C" MHU
  SG_ BMS_MaxMinDiffCellTemp : 63|8@0+ (1,-40) [-40|215] "°C" MHU

BO_ 584 DoorFRStatus: 8 XGW_Info
  SG_ NDoorFROutsideHandleFailure : 26|3@0+ (1,0) [0|7] "" MHU
  SG_ NDoorLatchFRFailure : 55|6@0+ (1,0) [0|63] "" MHU

BO_ 585 BMS_CoolntInletOutletTmp: 8 XGW_Info
  SG_ CHSKM_BMS_CoolntInletOutletTmp : 7|8@0+ (1,0) [0|255] "" MHU
  SG_ ALV_BMS_CoolntInletOutletTmp : 11|4@0+ (1,0) [0|14] "" MHU
  SG_ BMS_CoolantInletTemp : 23|8@0+ (1,-40) [-40|215] "°C" MHU
  SG_ BMS_CoolantOutletTemp : 31|8@0+ (1,-40) [-40|215] "°C" MHU
  SG_ BMS_BDUTemp1 : 39|8@0+ (1,-40) [-40|215] "°C" MHU
  SG_ BMS_BDUTemp2 : 47|8@0+ (1,-40) [-40|215] "°C" DUMMY_ECU

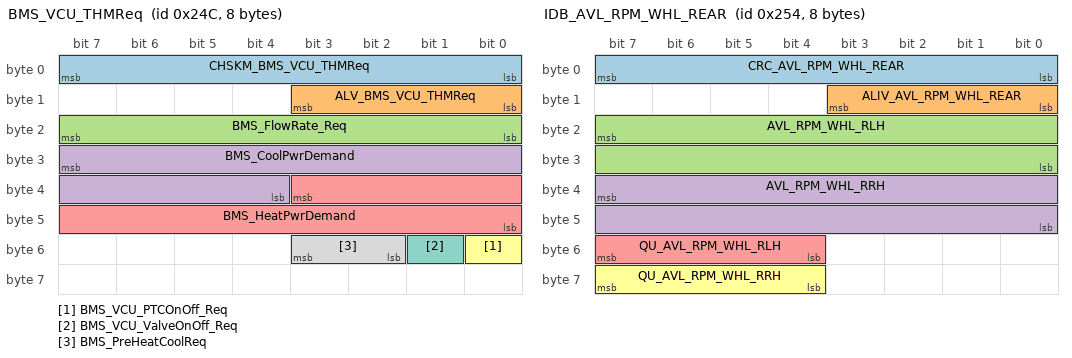
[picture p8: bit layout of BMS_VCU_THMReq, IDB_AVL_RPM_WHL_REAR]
BO_ 588 BMS_VCU_THMReq: 8 XGW_Info
  SG_ CHSKM_BMS_VCU_THMReq : 7|8@0+ (1,0) [0|255] "" MHU
  SG_ ALV_BMS_VCU_THMReq : 11|4@0+ (1,0) [0|14] "" MHU
  SG_ BMS_FlowRate_Req : 23|8@0+ (1,0) [0|50] "l/min" DUMMY_ECU
  SG_ BMS_CoolPwrDemand : 31|12@0+ (0.1,0) [0|10] "kW" MHU
  SG_ BMS_HeatPwrDemand : 35|12@0+ (0.1,0) [0|10] "kW" DUMMY_ECU
  SG_ BMS_VCU_PTCOnOff_Req : 48|1@0+ (1,0) [0|1] "" DUMMY_ECU
  SG_ BMS_VCU_ValveOnOff_Req : 49|1@0+ (1,0) [0|1] "" DUMMY_ECU
  SG_ BMS_PreHeatCoolReq : 51|2@0+ (1,0) [0|3] "" MHU

BO_ 596 IDB_AVL_RPM_WHL_REAR: 8 XGW_Info
  SG_ CRC_AVL_RPM_WHL_REAR : 7|8@0+ (1,0) [0|255] "" MHU
  SG_ ALIV_AVL_RPM_WHL_REAR : 11|4@0+ (1,0) [0|14] "" MHU
  SG_ AVL_RPM_WHL_RLH : 23|16@0+ (0.0156,-511.9844) [-400|400] "rad/s" MHU
  SG_ AVL_RPM_WHL_RRH : 39|16@0+ (0.0156,-511.9844) [-400|400] "rad/s" MHU
  SG_ QU_AVL_RPM_WHL_RLH : 55|4@0+ (1,0) [0|15] "Bit" MHU
  SG_ QU_AVL_RPM_WHL_RRH : 63|4@0+ (1,0) [0|15] "Bit" MHU

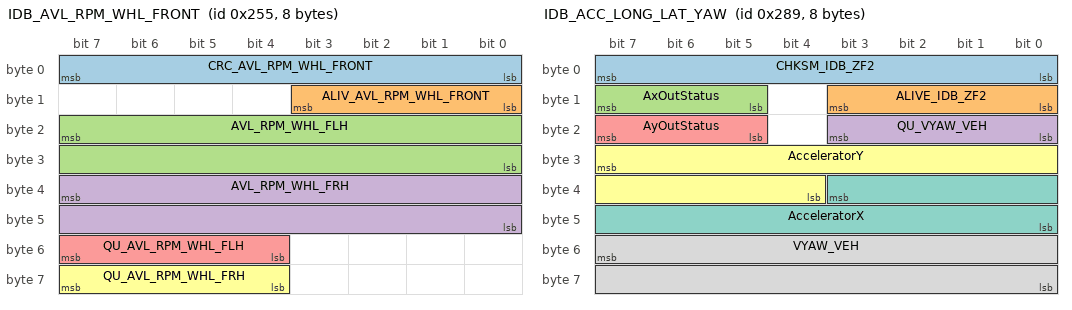
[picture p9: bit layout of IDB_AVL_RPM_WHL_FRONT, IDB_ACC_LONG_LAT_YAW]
BO_ 597 IDB_AVL_RPM_WHL_FRONT: 8 XGW_Info
  SG_ CRC_AVL_RPM_WHL_FRONT : 7|8@0+ (1,0) [0|255] "" MHU
  SG_ ALIV_AVL_RPM_WHL_FRONT : 11|4@0+ (1,0) [0|14] "" MHU
  SG_ AVL_RPM_WHL_FLH : 23|16@0+ (0.0156,-511.9844) [-400|400] "rad/s" MHU
  SG_ AVL_RPM_WHL_FRH : 39|16@0+ (0.0156,-511.9844) [-400|400] "rad/s" MHU
  SG_ QU_AVL_RPM_WHL_FLH : 55|4@0+ (1,0) [0|15] "Bit" MHU
  SG_ QU_AVL_RPM_WHL_FRH : 63|4@0+ (1,0) [0|15] "Bit" MHU

BO_ 641 DoorRLStatus: 8 XGW_Info
  SG_ NDoorRLOutsideHandleFailure : 26|3@0+ (1,0) [0|7] "" MHU
  SG_ NDoorLatchRLFailure : 55|6@0+ (1,0) [0|63] "" MHU

BO_ 649 IDB_ACC_LONG_LAT_YAW: 8 XGW_Info
  SG_ CHKSM_IDB_ZF2 : 7|8@0+ (1,0) [0|255] "" MHU
  SG_ ALIVE_IDB_ZF2 : 11|4@0+ (1,0) [0|14] "" MHU
  SG_ AxOutStatus : 15|3@0+ (1,0) [0|7] "" MHU
  SG_ QU_VYAW_VEH : 19|4@0+ (1,0) [0|15] "" MHU
  SG_ AyOutStatus : 23|3@0+ (1,0) [0|7] "" MHU
  SG_ AcceleratorY : 31|12@0+ (0.02713,-21.5928) [-21.593|21.5928] "m/s^2" MHU
  SG_ AcceleratorX : 35|12@0+ (0.02713,-21.5928) [-21.593|21.5928] "m/s^2" MHU
  SG_ VYAW_VEH : 55|16@0+ (0.005,-163.84) [-163.84|163.83] "°/s" MHU

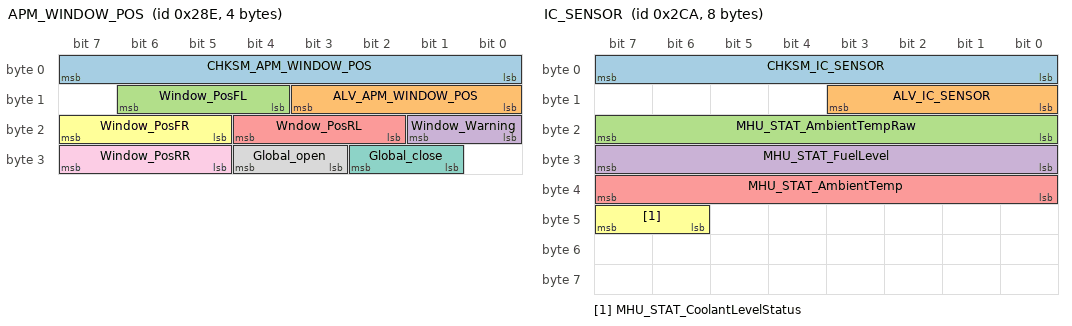
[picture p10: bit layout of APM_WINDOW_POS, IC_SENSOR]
BO_ 654 APM_WINDOW_POS: 4 XGW_Info
  SG_ CHKSM_APM_WINDOW_POS : 7|8@0+ (1,0) [0|255] "" CPD,MHU
  SG_ ALV_APM_WINDOW_POS : 11|4@0+ (1,0) [0|14] "" CPD,MHU
  SG_ Window_PosFL : 14|3@0+ (1,0) [0|7] "-" CPD,MHU
  SG_ Window_Warning : 17|2@0+ (1,0) [0|3] "" CPD,MHU
  SG_ Wndow_PosRL : 20|3@0+ (1,0) [0|7] "" CPD,MHU
  SG_ Window_PosFR : 23|3@0+ (1,0) [0|7] "" CPD,MHU
  SG_ Global_close : 26|2@0+ (1,0) [0|3] "" CPD,MHU
  SG_ Global_open : 28|2@0+ (1,0) [0|3] "" CPD,MHU
  SG_ Window_PosRR : 31|3@0+ (1,0) [0|7] "-" CPD,MHU

BO_ 676 SVC_EHC_EHC_2: 8 XGW_Info
  SG_ ID2 M : 0|8@1+ (1,0) [0|0] "" DUMMY_ECU,MHU
  SG_ ECU_ID_WUPREG m39 : 8|8@1+ (1,0) [0|127] "" DUMMY_ECU
  SG_ ID_FN_INQY m1 : 8|16@1+ (1,0) [0|0] "" DUMMY_ECU
  SG_ ID_FN_RQ_BUS m12 : 8|16@1+ (1,0) [0|0] "" DUMMY_ECU
  SG_ NO_CC_MESS_EXT m65 : 8|16@1+ (1,0) [0|65534] "" DUMMY_ECU
  SG_ NO_CC_MESS_STD m64 : 8|16@1+ (1,0) [0|65534] "" MHU,DUMMY_ECU
  SG_ WACA m39 : 16|8@1+ (1,0) [0|0] "" DUMMY_ECU
  SG_ ID_RQ_BUS m12 : 24|8@1+ (1,0) [0|0] "" DUMMY_ECU
  SG_ ST_CC_MESS_EXT m65 : 24|2@1+ (1,0) [0|0] "" DUMMY_ECU
  SG_ ST_CC_MESS_STD m64 : 24|2@1+ (1,0) [0|0] "" MHU
  SG_ TRANF_CC_MESS_EXT m65 : 26|4@1+ (1,0) [0|14] "" DUMMY_ECU
  SG_ TRANF_CC_MESS_STD m64 : 26|4@1+ (1,0) [0|14] "" MHU
  SG_ ST_IDC_CCLK_CC_MESS_EXT m65 : 30|2@1+ (1,0) [0|0] "" DUMMY_ECU
  SG_ ST_IDC_CCLK_CC_MESS_STD m64 : 30|2@1+ (1,0) [0|0] "" MHU
  SG_ NO_FRM_CC_MESS_EXT m65 : 32|4@1+ (1,0) [0|14] "" DUMMY_ECU
  SG_ ST_RQ_BUS m12 : 32|4@1+ (1,0) [0|0] "" DUMMY_ECU
  SG_ QUAN_FRM_CC_MESS_EXT m65 : 36|4@1+ (1,0) [0|14] "" DUMMY_ECU
  SG_ ST_LAW_RQ m12 : 36|4@1+ (1,0) [0|0] "" DUMMY_ECU
  SG_ DUR_FLLUPT m12 : 40|8@1+ (1,0) [0|254] "min" DUMMY_ECU
  SG_ UTDT_CC_MESS m65 : 40|24@1+ (1,0) [0|0] "" DUMMY_ECU

BO_ 714 IC_SENSOR: 8 MHU
  SG_ CHKSM_IC_SENSOR : 7|8@0+ (1,0) [0|255] "" ADAS_Info,AMP,CPD,EASC,HUD,XGW_Info
  SG_ ALV_IC_SENSOR : 11|4@0+ (1,0) [0|14] "" ADAS_Info,AMP,CPD,EASC,HUD,XGW_Info
  SG_ MHU_STAT_AmbientTempRaw : 23|8@0+ (0.5,-40) [-40|85] "°C" ADAS_Info,AMP,CPD,EASC,HUD,XGW_Info
  SG_ MHU_STAT_FuelLevel : 31|8@0+ (1,0) [0|100] "l" ADAS_Info,AMP,CPD,EASC,HUD,XGW_Info
  SG_ MHU_STAT_AmbientTemp : 39|8@0+ (0.5,-40) [-40|85] "Degree C" ADAS_Info,AMP,CPD,EASC,HUD,XGW_Info
  SG_ MHU_STAT_CoolantLevelStatus : 47|2@0+ (1,0) [0|3] "-" ADAS_Info,AMP,CPD,EASC,HUD,XGW_Info

BO_ 753 IC_STAT_AIRBAG: 1 MHU
  SG_ MHU_STAT_AirbagWarnLamp : 1|2@0+ (1,0) [0|3] "" XGW_Info

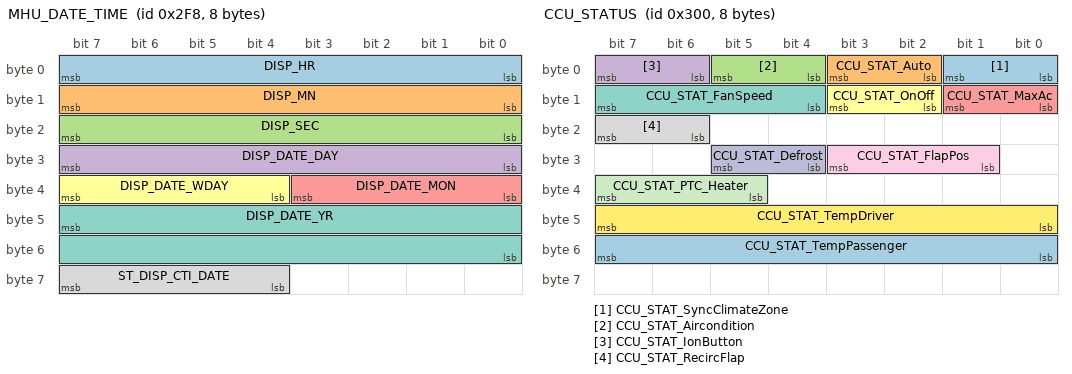
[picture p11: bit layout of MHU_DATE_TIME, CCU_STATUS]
BO_ 760 MHU_DATE_TIME: 8 MHU
  SG_ DISP_HR : 7|8@0+ (1,0) [0|23] "h" ADAS_Info,AMP,CPD,EASC,HUD,XGW_Info
  SG_ DISP_MN : 15|8@0+ (1,0) [0|59] "min" ADAS_Info,AMP,CPD,EASC,HUD,XGW_Info
  SG_ DISP_SEC : 23|8@0+ (1,0) [0|59] "s" ADAS_Info,AMP,CPD,EASC,HUD,XGW_Info
  SG_ DISP_DATE_DAY : 31|8@0+ (1,0) [1|31] "Day" ADAS_Info,AMP,CPD,EASC,HUD,XGW_Info
  SG_ DISP_DATE_MON : 35|4@0+ (1,0) [1|12] "Month" ADAS_Info,AMP,CPD,EASC,HUD,XGW_Info
  SG_ DISP_DATE_WDAY : 39|4@0+ (1,0) [0|15] "" ADAS_Info,AMP,CPD,EASC,HUD,XGW_Info
  SG_ DISP_DATE_YR : 47|16@0+ (1,0) [1|65534] "Year" ADAS_Info,AMP,CPD,EASC,HUD,XGW_Info
  SG_ ST_DISP_CTI_DATE : 63|4@0+ (1,0) [0|15] "" AMP,CPD,EASC,HUD,XGW_Info

BO_ 761 MHU_DATE_TIME_UTC: 8 MHU
  SG_ DISP_HR_UTC : 7|8@0+ (1,0) [0|23] "h" XGW_Info
  SG_ DISP_MN_UTC : 15|8@0+ (1,0) [0|59] "min" XGW_Info
  SG_ DISP_SEC_UTC : 23|8@0+ (1,0) [0|59] "s" XGW_Info
  SG_ DISP_DATE_DAY_UTC : 31|8@0+ (1,0) [1|31] "Day" XGW_Info
  SG_ DISP_DATE_MON_UTC : 35|4@0+ (1,0) [1|12] "Month" XGW_Info
  SG_ DISP_DATE_YR_UTC : 47|16@0+ (1,0) [1|65534] "Year" XGW_Info

BO_ 768 CCU_STATUS: 8 XGW_Info
  SG_ CCU_STAT_SyncClimateZone : 1|2@0+ (1,0) [0|3] "" MHU
  SG_ CCU_STAT_Auto : 3|2@0+ (1,0) [0|3] "-" MHU
  SG_ CCU_STAT_Aircondition : 5|2@0+ (1,0) [0|3] "" MHU
  SG_ CCU_STAT_IonButton : 7|2@0+ (1,0) [0|3] "" MHU
  SG_ CCU_STAT_MaxAc : 9|2@0+ (1,0) [0|3] "" MHU
  SG_ CCU_STAT_OnOff : 11|2@0+ (1,0) [0|3] "Bit" MHU
  SG_ CCU_STAT_FanSpeed : 15|4@0+ (1,0) [0|15] "" MHU
  SG_ CCU_STAT_RecircFlap : 23|2@0+ (1,0) [0|3] "" MHU
  SG_ CCU_STAT_FlapPos : 27|3@0+ (1,0) [0|7] "" MHU
  SG_ CCU_STAT_Defrost : 29|2@0+ (1,0) [0|3] "-" MHU
  SG_ CCU_STAT_PTC_Heater : 39|3@0+ (1,0) [0|7] "-" MHU
  SG_ CCU_STAT_TempDriver : 47|8@0+ (0.5,0) [16|32] "Degree C" MHU
  SG_ CCU_STAT_TempPassenger : 55|8@0+ (0.5,0) [16|32] "Degree C" MHU

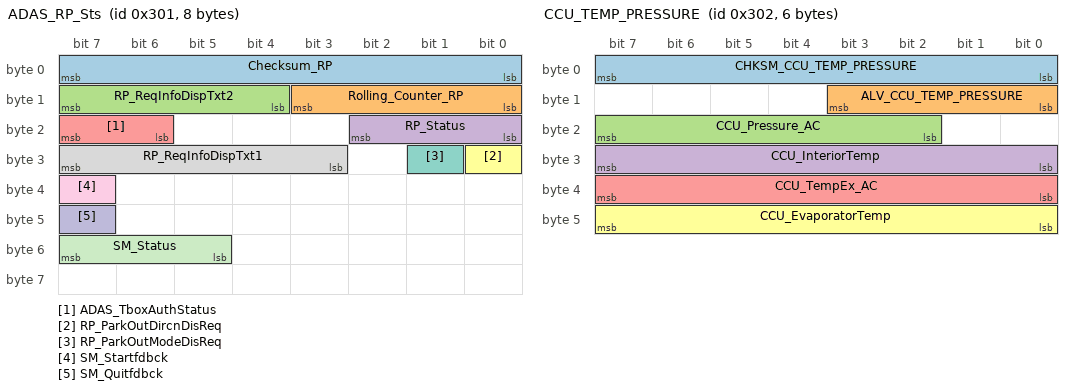
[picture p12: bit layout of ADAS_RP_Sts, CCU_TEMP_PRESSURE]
BO_ 769 ADAS_RP_Sts: 8 ADAS_Info
  SG_ Checksum_RP : 7|8@0+ (1,0) [0|255] "" MHU
  SG_ Rolling_Counter_RP : 11|4@0+ (1,0) [0|14] "" MHU
  SG_ RP_ReqInfoDispTxt2 : 15|4@0+ (1,0) [0|15] "-" MHU
  SG_ RP_Status : 18|3@0+ (1,0) [0|7] "-" MHU
  SG_ ADAS_TboxAuthStatus : 23|2@0+ (1,0) [0|3] "-" MHU
  SG_ RP_ParkOutDircnDisReq : 24|1@0+ (1,0) [0|1] "-" MHU
  SG_ RP_ParkOutModeDisReq : 25|1@0+ (1,0) [0|1] "-" MHU
  SG_ RP_ReqInfoDispTxt1 : 31|5@0+ (1,0) [0|31] "-" MHU
  SG_ SM_Startfdbck : 39|1@0+ (1,0) [0|1] "" MHU
  SG_ SM_Quitfdbck : 47|1@0+ (1,0) [0|1] "" MHU
  SG_ SM_Status : 55|3@0+ (1,0) [0|7] "" MHU

BO_ 770 CCU_TEMP_PRESSURE: 6 XGW_Info
  SG_ CHKSM_CCU_TEMP_PRESSURE : 7|8@0+ (1,0) [0|255] "" ADAS_Info,AMP,CPD,EASC,HUD,MHU
  SG_ ALV_CCU_TEMP_PRESSURE : 11|4@0+ (1,0) [0|14] "" ADAS_Info,AMP,CPD,EASC,HUD,MHU
  SG_ CCU_Pressure_AC : 23|6@0+ (1,0) [0|62] "bar" ADAS_Info,AMP,CPD,EASC,HUD,MHU
  SG_ CCU_InteriorTemp : 31|8@0+ (0.5,-40) [-40|85] "Degree C" ADAS_Info,AMP,CPD,EASC,HUD,MHU
  SG_ CCU_TempEx_AC : 39|8@0+ (0.5,-40) [-40|85] "Degree C" ADAS_Info,AMP,CPD,EASC,HUD,MHU
  SG_ CCU_EvaporatorTemp : 47|8@0+ (0.5,-40) [-40|85] "Degree C" ADAS_Info,AMP,CPD,EASC,HUD,MHU

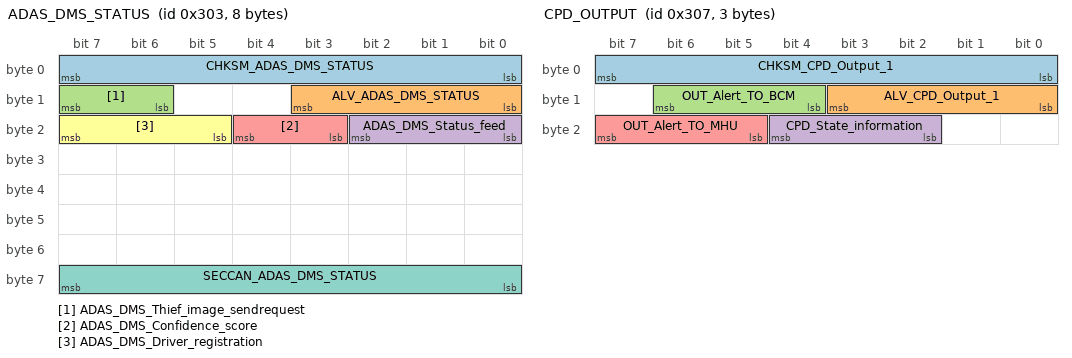
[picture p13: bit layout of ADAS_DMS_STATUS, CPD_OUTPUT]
BO_ 771 ADAS_DMS_STATUS: 8 ADAS_Info
  SG_ CHKSM_ADAS_DMS_STATUS : 7|8@0+ (1,0) [0|255] "" MHU
  SG_ ALV_ADAS_DMS_STATUS : 11|4@0+ (1,0) [0|14] "" MHU
  SG_ ADAS_DMS_Thief_image_sendrequest : 15|2@0+ (1,0) [0|3] "-" MHU
  SG_ ADAS_DMS_Status_feed : 18|3@0+ (1,0) [0|7] "-" MHU
  SG_ ADAS_DMS_Confidence_score : 20|2@0+ (1,0) [0|3] "-" MHU
  SG_ ADAS_DMS_Driver_registration : 23|3@0+ (1,0) [0|7] "-" MHU
  SG_ SECCAN_ADAS_DMS_STATUS : 63|8@0+ (1,0) [0|255] "" MHU

BO_ 773 BMS_Insulation: 8 XGW_Info
  SG_ CHSKM_BMS_Insulation : 7|8@0+ (1,0) [0|255] "" MHU
  SG_ ALV_BMS_Insulation : 11|4@0+ (1,0) [0|14] "" MHU
  SG_ BMS_VCU_Insulation_Mon_Sts : 15|1@0+ (1,0) [0|1] "" DUMMY_ECU
  SG_ BMS_PackInsuRes : 23|16@0+ (1,0) [0|60000] "kOhm" MHU

BO_ 775 CPD_OUTPUT: 3 CPD
  SG_ CHKSM_CPD_Output_1 : 7|8@0+ (1,0) [0|255] "" MHU,XGW_Info
  SG_ ALV_CPD_Output_1 : 11|4@0+ (1,0) [0|14] "" MHU,XGW_Info
  SG_ OUT_Alert_TO_BCM : 14|3@0+ (1,0) [0|7] "-" XGW_Info,MHU
  SG_ CPD_State_information : 20|3@0+ (1,0) [0|7] "-" MHU,XGW_Info
  SG_ OUT_Alert_TO_MHU : 23|3@0+ (1,0) [0|7] "-" MHU,XGW_Info

BO_ 776 MHU_CPD_Confirm: 8 MHU
  SG_ MHU_CPD_Setting : 4|3@0+ (1,0) [0|7] "-" CPD
  SG_ MHU_CPD_Confirmation_On_HMI : 7|3@0+ (1,0) [0|7] "-" CPD

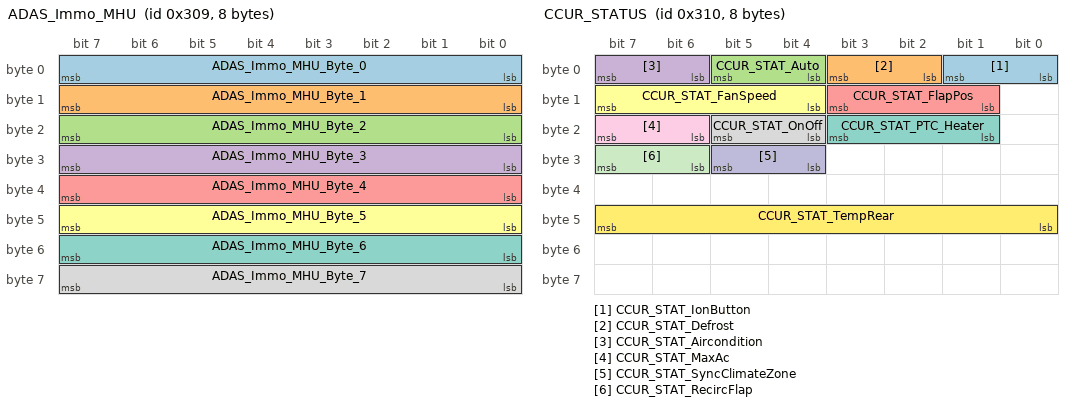
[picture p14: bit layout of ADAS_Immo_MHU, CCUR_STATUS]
BO_ 777 ADAS_Immo_MHU: 8 ADAS_Info
  SG_ ADAS_Immo_MHU_Byte_0 : 7|8@0+ (1,0) [0|255] "-" MHU
  SG_ ADAS_Immo_MHU_Byte_1 : 15|8@0+ (1,0) [0|255] "-" MHU
  SG_ ADAS_Immo_MHU_Byte_2 : 23|8@0+ (1,0) [0|255] "-" MHU
  SG_ ADAS_Immo_MHU_Byte_3 : 31|8@0+ (1,0) [0|255] "-" MHU
  SG_ ADAS_Immo_MHU_Byte_4 : 39|8@0+ (1,0) [0|255] "-" MHU
  SG_ ADAS_Immo_MHU_Byte_5 : 47|8@0+ (1,0) [0|255] "-" MHU
  SG_ ADAS_Immo_MHU_Byte_6 : 55|8@0+ (1,0) [0|255] "-" MHU
  SG_ ADAS_Immo_MHU_Byte_7 : 63|8@0+ (1,0) [0|255] "-" MHU

BO_ 784 CCUR_STATUS: 8 XGW_Info
  SG_ CCUR_STAT_IonButton : 1|2@0+ (1,0) [0|3] "-" MHU
  SG_ CCUR_STAT_Defrost : 3|2@0+ (1,0) [0|3] "" MHU
  SG_ CCUR_STAT_Auto : 5|2@0+ (1,0) [0|3] "" MHU
  SG_ CCUR_STAT_Aircondition : 7|2@0+ (1,0) [0|3] "-" MHU
  SG_ CCUR_STAT_FlapPos : 11|3@0+ (1,0) [0|7] "-" MHU
  SG_ CCUR_STAT_FanSpeed : 15|4@0+ (1,0) [0|15] "-" MHU
  SG_ CCUR_STAT_PTC_Heater : 19|3@0+ (1,0) [0|7] "" MHU
  SG_ CCUR_STAT_OnOff : 21|2@0+ (1,0) [0|3] "Bit" MHU
  SG_ CCUR_STAT_MaxAc : 23|2@0+ (1,0) [0|3] "" MHU
  SG_ CCUR_STAT_SyncClimateZone : 29|2@0+ (1,0) [0|3] "-" MHU
  SG_ CCUR_STAT_RecircFlap : 31|2@0+ (1,0) [0|3] "-" MHU
  SG_ CCUR_STAT_TempRear : 47|8@0+ (0.5,0) [16|32] "Degree C" MHU

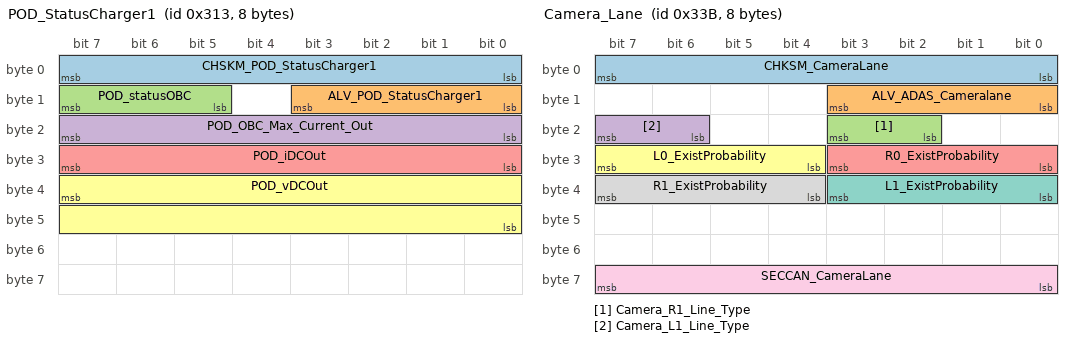
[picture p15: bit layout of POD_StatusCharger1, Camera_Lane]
BO_ 787 POD_StatusCharger1: 8 XGW_Info
  SG_ CHSKM_POD_StatusCharger1 : 7|8@0+ (1,0) [0|255] "" MHU
  SG_ ALV_POD_StatusCharger1 : 11|4@0+ (1,0) [0|14] "" MHU
  SG_ POD_statusOBC : 15|3@0+ (1,0) [0|7] "" MHU
  SG_ POD_OBC_Max_Current_Out : 23|8@0+ (1,0) [0|64] "A" MHU
  SG_ POD_iDCOut : 31|8@0+ (1,0) [0|64] "A" MHU
  SG_ POD_vDCOut : 39|16@0+ (0.0625,0) [0|512] "V" MHU

BO_ 803 POD_StatusCharger2: 8 XGW_Info
  SG_ CHSKM_POD_StatusCharger2 : 7|8@0+ (1,0) [0|255] "" MHU
  SG_ ALV_POD_StatusCharger2 : 11|4@0+ (1,0) [0|14] "" MHU
  SG_ POD_phaseACInput : 15|2@0+ (1,0) [0|3] "" MHU
  SG_ POD_iACInput : 23|16@0+ (0.0625,0) [0|60] "A" MHU
  SG_ POD_vACInput : 39|16@0+ (0.0625,0) [0|512] "V" MHU

BO_ 804 HOD_Heating: 2 MHU
  SG_ Steering_HeatingControl : 7|2@0+ (1,0) [0|3] "" XGW_Info

BO_ 805 STWH_Feedback: 2 XGW_Info
  SG_ Steering_HeatingControlFdbk : 7|2@0+ (1,0) [0|3] "-" MHU

BO_ 806 POD_StatusDCDC1: 8 XGW_Info
  SG_ CHSKM_POD_StatusDCDC1 : 7|8@0+ (1,0) [0|255] "" MHU
  SG_ ALV_POD_StatusDCDC1 : 11|4@0+ (1,0) [0|14] "" MHU
  SG_ POD_statusDCDC : 14|3@0+ (1,0) [0|7] "" MHU
  SG_ POD_DCDC_Max_Current_Out : 23|8@0+ (1,0) [0|250] "A" MHU

BO_ 807 POD_StatusFC: 8 XGW_Info
  SG_ CHKSM_POD_StatusFC : 7|8@0+ (1,0) [0|255] "" MHU
  SG_ ALV_POD_StatusFC : 11|4@0+ (1,0) [0|14] "" MHU
  SG_ POD_vFC : 23|16@0+ (0.0625,0) [0|512] "V" MHU
  SG_ POD_statusFCContactors : 47|3@0+ (1,0) [0|7] "" MHU

BO_ 808 IC_RELATIVIME: 6 MHU
  SG_ T_SEC_COU_REL : 7|32@0+ (1,0) [0|4294967294] "s" XGW_Info
  SG_ T_DAY_COU_ABSL : 39|16@0+ (1,0) [0|65534] "Day" XGW_Info

BO_ 809 BCM_ODO: 8 XGW_Info
  SG_ CRC_BCM_ODO : 7|8@0+ (1,0) [0|255] "" MHU
  SG_ ALIV_BCM_ODO : 11|4@0+ (1,0) [0|14] "" MHU
  SG_ Odometer_BCM : 23|20@0+ (1,0) [0|999999] "km" MHU
  SG_ SECCAN_BCM_ODO : 63|8@0+ (1,0) [0|255] "" MHU

BO_ 816 IC_MILEAGE: 8 XGW_Info
  SG_ MILE_KM : 7|24@0+ (1,0) [0|999999] "km" ADAS_Info,AMP,CPD,EASC,HUD,MHU
  SG_ FLLV_FUTA : 31|8@0+ (1,0) [0|254] "l" ADAS_Info,AMP,CPD,EASC,HUD,MHU
  SG_ RNG : 51|12@0+ (1,0) [0|4094] "km" ADAS_Info,AMP,CPD,EASC,HUD,MHU
  SG_ ST_FLLV_FUTA_SPAR : 55|2@0+ (1,0) [0|3] "" ADAS_Info,AMP,CPD,EASC,HUD,MHU

BO_ 818 BMS_PackInfo: 8 XGW_Info
 SG_ Checksum_0x332 : 7|8@0+ (1,0) [0|255] "" MHU
 SG_ Rolling_Counter_0x332 : 11|4@0+ (1,0) [0|14] "" MHU
 SG_ BMS_PackCNom : 23|16@0+ (0.1,0) [0|6553.5] "kWh" MHU
 SG_ BMS_PackTemp_0x332 : 39|8@0+ (1,-40) [-40|215] "Degree C" MHU

BO_ 827 Camera_Lane: 8 ADAS_Info
  SG_ CHKSM_CameraLane : 7|8@0+ (1,0) [0|255] "" MHU
  SG_ ALV_ADAS_Cameralane : 11|4@0+ (1,0) [0|14] "" MHU
  SG_ Camera_R1_Line_Type : 19|2@0+ (1,0) [0|3] "-" MHU
  SG_ Camera_L1_Line_Type : 23|2@0+ (1,0) [0|3] "-" MHU
  SG_ R0_ExistProbability : 27|4@0+ (0.1,0) [0|1] "-" MHU
  SG_ L0_ExistProbability : 31|4@0+ (0.1,0) [0|1] "-" MHU
  SG_ L1_ExistProbability : 35|4@0+ (0.1,0) [0|1] "-" MHU
  SG_ R1_ExistProbability : 39|4@0+ (0.1,0) [0|1] "-" MHU
  SG_ SECCAN_CameraLane : 63|8@0+ (1,0) [0|255] "" MHU

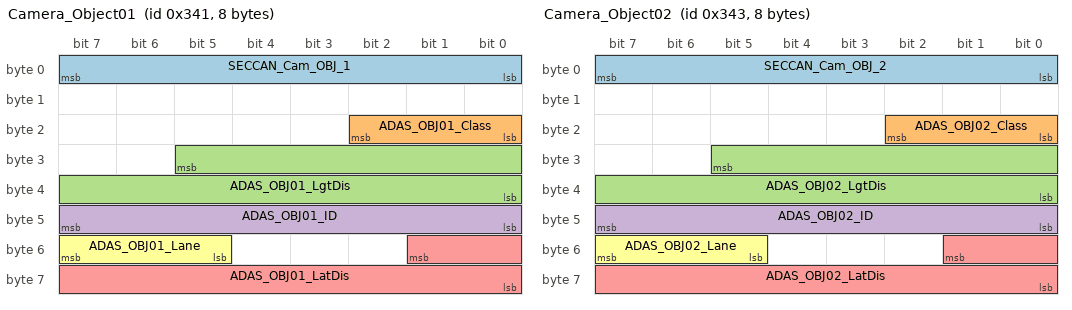
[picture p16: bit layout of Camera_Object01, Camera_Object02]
BO_ 833 Camera_Object01: 8 ADAS_Info
  SG_ SECCAN_Cam_OBJ_1 : 7|8@0+ (1,0) [0|255] "" MHU
  SG_ ADAS_OBJ01_Class : 18|3@0+ (1,0) [0|7] "-" MHU
  SG_ ADAS_OBJ01_LgtDis : 29|14@0+ (0.025,-10) [-10|399.575] "-" MHU
  SG_ ADAS_OBJ01_ID : 47|8@0+ (1,0) [0|255] "-" MHU
  SG_ ADAS_OBJ01_LatDis : 49|10@0+ (0.0293,-15.0146) [-15.0146|14.9593] "-" MHU
  SG_ ADAS_OBJ01_Lane : 55|3@0+ (1,0) [0|7] "-" MHU

BO_ 835 Camera_Object02: 8 ADAS_Info
  SG_ SECCAN_Cam_OBJ_2 : 7|8@0+ (1,0) [0|255] "" MHU
  SG_ ADAS_OBJ02_Class : 18|3@0+ (1,0) [0|7] "-" MHU
  SG_ ADAS_OBJ02_LgtDis : 29|14@0+ (0.025,-10) [-10|399.575] "-" MHU
  SG_ ADAS_OBJ02_ID : 47|8@0+ (1,0) [0|255] "-" MHU
  SG_ ADAS_OBJ02_LatDis : 49|10@0+ (0.0293,-15.0146) [-15.0146|14.985] "-" MHU
  SG_ ADAS_OBJ02_Lane : 55|3@0+ (1,0) [0|7] "-" MHU

BO_ 838 POD_StatusDCDC2: 8 XGW_Info
  SG_ CHSKM_POD_StatusDCDC2 : 7|8@0+ (1,0) [0|255] "" MHU
  SG_ ALV_POD_StatusDCDC2 : 11|4@0+ (1,0) [0|14] "" MHU
  SG_ POD_vDCInput : 23|16@0+ (0.0625,0) [0|512] "V" MHU
  SG_ POD_iDCDCOutput : 39|16@0+ (0.0625,0) [0|300] "A" MHU
  SG_ POD_vDCDCOutput : 55|16@0+ (0.0625,0) [0|18] "V" MHU

BO_ 840 EDS_Sts_FR: 8 XGW_Info
  SG_ EDS_HVIL_STS_FWD : 25|2@0+ (1,0) [0|3] "" MHU

BO_ 841 EDS_R_Sts_RR: 8 XGW_Info
  SG_ EDS_HVIL_STS_RWD : 25|2@0+ (1,0) [0|3] "" MHU

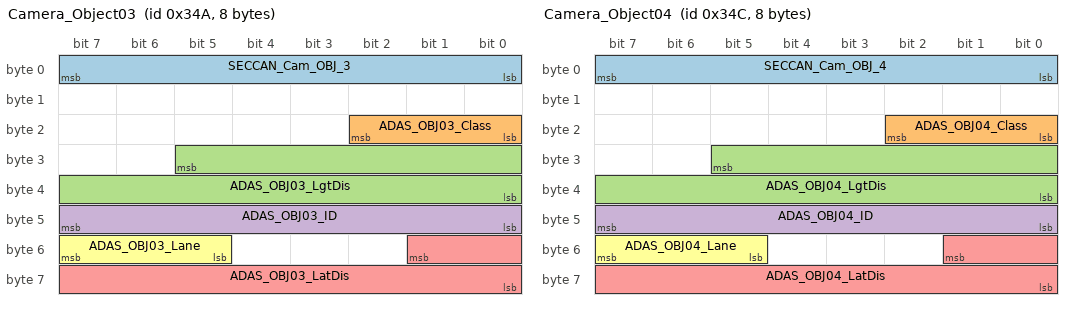
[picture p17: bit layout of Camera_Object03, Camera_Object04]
BO_ 842 Camera_Object03: 8 ADAS_Info
  SG_ SECCAN_Cam_OBJ_3 : 7|8@0+ (1,0) [0|255] "" MHU
  SG_ ADAS_OBJ03_Class : 18|3@0+ (1,0) [0|7] "-" MHU
  SG_ ADAS_OBJ03_LgtDis : 29|14@0+ (0.025,-10) [-10|399.575] "-" MHU
  SG_ ADAS_OBJ03_ID : 47|8@0+ (1,0) [0|255] "-" MHU
  SG_ ADAS_OBJ03_LatDis : 49|10@0+ (0.0293,-15.0146) [-15.0146|14.985] "-" MHU
  SG_ ADAS_OBJ03_Lane : 55|3@0+ (1,0) [0|7] "-" MHU

BO_ 844 Camera_Object04: 8 ADAS_Info
  SG_ SECCAN_Cam_OBJ_4 : 7|8@0+ (1,0) [0|255] "" MHU
  SG_ ADAS_OBJ04_Class : 18|3@0+ (1,0) [0|7] "-" MHU
  SG_ ADAS_OBJ04_LgtDis : 29|14@0+ (0.025,-10) [-10|399.575] "-" MHU
  SG_ ADAS_OBJ04_ID : 47|8@0+ (1,0) [0|255] "-" MHU
  SG_ ADAS_OBJ04_LatDis : 49|10@0+ (0.0293,-15.0146) [-15.0146|14.985] "-" MHU
  SG_ ADAS_OBJ04_Lane : 55|3@0+ (1,0) [0|7] "-" MHU

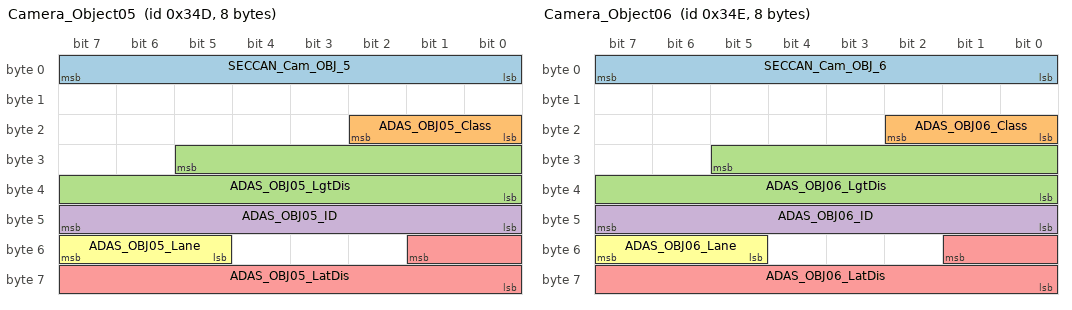
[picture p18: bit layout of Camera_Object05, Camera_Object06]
BO_ 845 Camera_Object05: 8 ADAS_Info
  SG_ SECCAN_Cam_OBJ_5 : 7|8@0+ (1,0) [0|255] "" MHU
  SG_ ADAS_OBJ05_Class : 18|3@0+ (1,0) [0|7] "-" MHU
  SG_ ADAS_OBJ05_LgtDis : 29|14@0+ (0.025,-10) [-10|399.575] "-" MHU
  SG_ ADAS_OBJ05_ID : 47|8@0+ (1,0) [0|255] "-" MHU
  SG_ ADAS_OBJ05_LatDis : 49|10@0+ (0.0293,-15.0146) [-15.0146|14.985] "-" MHU
  SG_ ADAS_OBJ05_Lane : 55|3@0+ (1,0) [0|7] "-" MHU

BO_ 846 Camera_Object06: 8 ADAS_Info
  SG_ SECCAN_Cam_OBJ_6 : 7|8@0+ (1,0) [0|255] "" MHU
  SG_ ADAS_OBJ06_Class : 18|3@0+ (1,0) [0|7] "-" MHU
  SG_ ADAS_OBJ06_LgtDis : 29|14@0+ (0.025,-10) [-10|399.575] "-" MHU
  SG_ ADAS_OBJ06_ID : 47|8@0+ (1,0) [0|255] "-" MHU
  SG_ ADAS_OBJ06_LatDis : 49|10@0+ (0.0293,-15.0146) [-15.0146|14.985] "-" MHU
  SG_ ADAS_OBJ06_Lane : 55|3@0+ (1,0) [0|7] "-" MHU

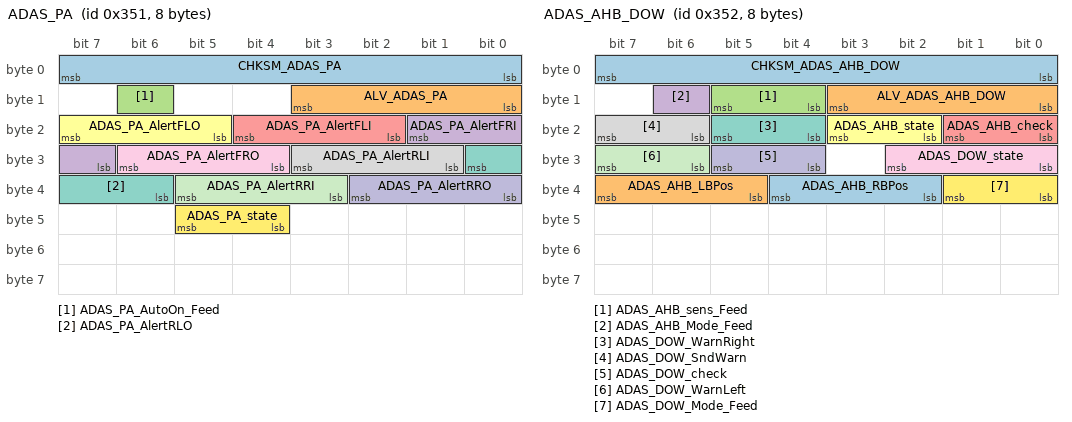
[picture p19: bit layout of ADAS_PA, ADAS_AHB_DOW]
BO_ 849 ADAS_PA: 8 ADAS_Info
  SG_ CHKSM_ADAS_PA : 7|8@0+ (1,0) [0|255] "" HUD,MHU
  SG_ ALV_ADAS_PA : 11|4@0+ (1,0) [0|14] "" HUD,MHU
  SG_ ADAS_PA_AutoOn_Feed : 14|1@0+ (1,0) [0|1] "-" HUD,MHU
  SG_ ADAS_PA_AlertFRI : 17|3@0+ (1,0) [0|7] "-" HUD,MHU
  SG_ ADAS_PA_AlertFLI : 20|3@0+ (1,0) [0|7] "-" HUD,MHU
  SG_ ADAS_PA_AlertFLO : 23|3@0+ (1,0) [0|7] "-" HUD,MHU
  SG_ ADAS_PA_AlertRLO : 24|3@0+ (1,0) [0|7] "-" HUD,MHU
  SG_ ADAS_PA_AlertRLI : 27|3@0+ (1,0) [0|7] "-" HUD,MHU
  SG_ ADAS_PA_AlertFRO : 30|3@0+ (1,0) [0|7] "-" HUD,MHU
  SG_ ADAS_PA_AlertRRO : 34|3@0+ (1,0) [0|7] "-" HUD,MHU
  SG_ ADAS_PA_AlertRRI : 37|3@0+ (1,0) [0|7] "-" HUD,MHU
  SG_ ADAS_PA_state : 45|2@0+ (1,0) [0|3] "-" HUD,MHU

BO_ 850 ADAS_AHB_DOW: 8 ADAS_Info
  SG_ CHKSM_ADAS_AHB_DOW : 7|8@0+ (1,0) [0|255] "" HUD,MHU
  SG_ ALV_ADAS_AHB_DOW : 11|4@0+ (1,0) [0|14] "" HUD,MHU
  SG_ ADAS_AHB_sens_Feed : 13|2@0+ (1,0) [0|3] "-" MHU
  SG_ ADAS_AHB_Mode_Feed : 14|1@0+ (1,0) [0|1] "-" MHU
  SG_ ADAS_AHB_check : 17|2@0+ (1,0) [0|3] "-" MHU
  SG_ ADAS_AHB_state : 19|2@0+ (1,0) [0|3] "-" MHU
  SG_ ADAS_DOW_WarnRight : 21|2@0+ (1,0) [0|3] "-" MHU
  SG_ ADAS_DOW_SndWarn : 23|2@0+ (1,0) [0|3] "-" MHU
  SG_ ADAS_DOW_state : 26|3@0+ (1,0) [0|7] "-" MHU
  SG_ ADAS_DOW_check : 29|2@0+ (1,0) [0|3] "-" MHU
  SG_ ADAS_DOW_WarnLeft : 31|2@0+ (1,0) [0|3] "-" MHU
  SG_ ADAS_DOW_Mode_Feed : 33|2@0+ (1,0) [0|3] "-" MHU
  SG_ ADAS_AHB_RBPos : 36|3@0+ (1,0) [0|7] "" MHU
  SG_ ADAS_AHB_LBPos : 39|3@0+ (1,0) [0|7] "-" MHU

BO_ 851 ADAS_CMP_ACC: 8 ADAS_Info
  SG_ CHKSM_ADAS_ACC : 7|8@0+ (1,0) [0|255] "" HUD,MHU
  SG_ ALV_ADAS_ACC : 11|4@0+ (1,0) [0|14] "" HUD,MHU
  SG_ ADAS_ACC_ObjDetec : 12|1@0+ (1,0) [0|1] "-" HUD,MHU
  SG_ ADAS_ISA_check : 14|2@0+ (1,0) [0|3] "-" HUD,MHU
  SG_ ADAS_ISA_Mode_SW_Feed : 15|1@0+ (1,0) [0|1] "-" HUD,MHU
  SG_ ADAS_TagSpeed_ICON_Feed : 18|3@0+ (1,0) [0|7] "-" HUD,MHU
  SG_ ADAS_ISA_PopUp_Feed : 23|4@0+ (1,0) [0|15] "-" HUD,MHU
  SG_ ADAS_ISA_Btn_Feed : 24|1@0+ (1,0) [0|1] "-" HUD,MHU
  SG_ ADAS_ACC_DistSet_upper_Feed : 25|1@0+ (1,0) [0|1] "-" HUD,MHU
  SG_ ADAS_ACC_TimeGapSet : 28|3@0+ (1,0) [0|7] "-" HUD,MHU
  SG_ ADAS_ACC_State : 31|3@0+ (1,0) [0|7] "-" HUD,MHU
  SG_ ADAS_ACC_TagSpeed : 39|8@0+ (1,0) [0|255] "km/h" HUD,MHU
  SG_ ADAS_ACC_PopUp_Feed : 43|4@0+ (1,0) [0|15] "-" HUD,MHU
  SG_ ADAS_ACC_check : 47|2@0+ (1,0) [0|3] "-" HUD,MHU
  SG_ ADAS_ISA_ICON_Feed : 50|3@0+ (1,0) [0|7] "-" HUD,MHU
  SG_ ADAS_ACC_DistSet_lower_Feed : 51|1@0+ (1,0) [0|1] "-" HUD,MHU
  SG_ ADAS_ACC_SpdSet_upper_Feed : 52|1@0+ (1,0) [0|1] "-" HUD,MHU
  SG_ ADAS_ACC_SpdSet_lower_Feed : 53|1@0+ (1,0) [0|1] "-" HUD,MHU
  SG_ ADAS_ACC_On_Feed : 54|1@0+ (1,0) [0|1] "-" HUD,MHU
  SG_ ADAS_ACC_Set_Feed : 55|1@0+ (1,0) [0|1] "-" HUD,MHU
  SG_ ADAS_ACC_CnlBtn_Feed : 56|1@0+ (1,0) [0|1] "-" HUD,MHU
  SG_ ADAS_ACC_Res_Feed : 57|1@0+ (1,0) [0|1] "-" HUD,MHU
  SG_ ADAS_ACC_ICON_Feed : 60|3@0+ (1,0) [0|7] "-" HUD,MHU
  SG_ ADAS_ISA_Status : 63|3@0+ (1,0) [0|7] "-" HUD,MHU

BA_DEF_ BO_  "GenMsgSendType" ENUM "Cyclic","NotUsed","NotUsed","NotUsed","NotUsed","NotUsed","NotUsed","IfActive","NoMsgSendType","NotUsed";
BA_DEF_ BO_  "GenMsgILSupport" ENUM "No","Yes";
BA_DEF_ BO_  "DiagResponse" ENUM "No","Yes";
BA_DEF_ BO_  "DiagRequest" ENUM "No","Yes";
BA_DEF_ BO_  "NmAsrMessage" ENUM "No","Yes";
BA_DEF_ BO_  "DiagState" ENUM "No","Yes";
BA_DEF_ BO_  "DiagUudtResponse" ENUM "False","True";
BA_DEF_ BO_  "GenMsgStartDelayTime" INT 0 65535;
BA_DEF_ BO_  "GenMsgDelayTime" INT 0 0;
BA_DEF_ BO_  "GenMsgNrOfRepetition" INT 0 0;
BA_DEF_ BO_  "GenMsgCycleTimeFast" INT 0 0;
BA_DEF_ BO_  "GenMsgCycleTime" INT 0 0;
BA_DEF_ SG_  "GenSigSendType" ENUM "Cyclic","OnWrite","OnWriteWithRepetition","OnChange","OnChangeWithRepetition","IfActive","IfActiveWithRepetition","NoSigSendType","NotUsed","NotUsed","NotUsed","NotUsed","NotUsed";
BA_DEF_ SG_  "InvalidValue" STRING;
BA_DEF_ SG_  "GenSigStartValue" INT 0 0;
BA_DEF_ SG_  "GenSigTimeoutTime_ALL" INT 0 65535;
BA_DEF_DEF_  "DiagRequest" "No";
BA_DEF_DEF_  "DiagResponse" "No";
BA_DEF_DEF_  "DiagState" "No";
BA_DEF_DEF_  "DiagUudtResponse" "False";
BA_DEF_DEF_  "GenMsgCycleTime" 0;
BA_DEF_DEF_  "GenMsgCycleTimeFast" 0;
BA_DEF_DEF_  "GenMsgDelayTime" 0;
BA_DEF_DEF_  "GenMsgILSupport" "Yes";
BA_DEF_DEF_  "GenMsgNrOfRepetition" 0;
BA_DEF_DEF_  "GenMsgSendType" "NoMsgSendType";
BA_DEF_DEF_  "GenMsgStartDelayTime" 0;
BA_DEF_DEF_  "GenSigSendType" "Cyclic";
BA_DEF_DEF_  "GenSigStartValue" 0;
BA_DEF_DEF_  "GenSigTimeoutTime_ALL" 0;
BA_DEF_DEF_  "NmAsrMessage" "No";
BA_ "GenMsgCycleTime" BO_ 389 100;
BA_ "GenMsgSendType" BO_ 389 0;
BA_ "GenMsgCycleTime" BO_ 409 1000;
BA_ "GenMsgILSupport" BO_ 409 0;
BA_ "GenMsgSendType" BO_ 409 0;
BA_ "GenMsgCycleTime" BO_ 417 20;
BA_ "GenMsgSendType" BO_ 417 0;
BA_ "GenMsgCycleTime" BO_ 504 40;
BA_ "GenMsgSendType" BO_ 504 0;
BA_ "GenMsgCycleTime" BO_ 505 40;
BA_ "GenMsgSendType" BO_ 505 0;
BA_ "GenMsgCycleTime" BO_ 515 100;
BA_ "GenMsgSendType" BO_ 515 0;
BA_ "GenMsgCycleTime" BO_ 516 100;
BA_ "GenMsgSendType" BO_ 516 0;
BA_ "GenMsgCycleTime" BO_ 517 20;
BA_ "GenMsgILSupport" BO_ 517 0;
BA_ "GenMsgSendType" BO_ 517 0;
BA_ "GenMsgCycleTime" BO_ 518 50;
BA_ "GenMsgSendType" BO_ 518 0;
BA_ "GenMsgCycleTime" BO_ 519 100;
BA_ "GenMsgSendType" BO_ 519 0;
BA_ "GenMsgCycleTime" BO_ 520 100;
BA_ "GenMsgSendType" BO_ 520 0;
BA_ "GenMsgCycleTime" BO_ 522 100;
BA_ "GenMsgSendType" BO_ 522 0;
BA_ "GenMsgCycleTime" BO_ 523 100;
BA_ "GenMsgSendType" BO_ 523 0;
BA_ "GenMsgCycleTime" BO_ 524 100;
BA_ "GenMsgSendType" BO_ 524 0;
BA_ "GenMsgCycleTime" BO_ 525 40;
BA_ "GenMsgSendType" BO_ 525 0;
BA_ "GenMsgSendType" BO_ 526 0;
BA_ "GenMsgCycleTime" BO_ 526 10000;
BA_ "GenMsgCycleTime" BO_ 531 100;
BA_ "GenMsgSendType" BO_ 531 0;
BA_ "GenMsgCycleTime" BO_ 532 50;
BA_ "GenMsgSendType" BO_ 532 0;
BA_ "GenMsgCycleTime" BO_ 533 50;
BA_ "GenMsgSendType" BO_ 533 0;
BA_ "GenMsgCycleTime" BO_ 534 50;
BA_ "GenMsgSendType" BO_ 534 0;
BA_ "GenMsgCycleTimeFast" BO_ 544 50;
BA_ "GenMsgNrOfRepetition" BO_ 544 3;
BA_ "GenMsgCycleTime" BO_ 545 80;
BA_ "GenMsgSendType" BO_ 545 0;
BA_ "GenMsgCycleTime" BO_ 546 80;
BA_ "GenMsgSendType" BO_ 546 0;
BA_ "GenMsgCycleTime" BO_ 549 100;
BA_ "GenMsgILSupport" BO_ 549 0;
BA_ "GenMsgSendType" BO_ 549 0;
BA_ "GenMsgCycleTime" BO_ 561 20;
BA_ "GenMsgSendType" BO_ 561 0;
BA_ "GenMsgCycleTime" BO_ 565 100;
BA_ "GenMsgSendType" BO_ 565 0;
BA_ "GenMsgCycleTime" BO_ 569 20;
BA_ "GenMsgSendType" BO_ 569 0;
BA_ "GenMsgCycleTime" BO_ 581 150;
BA_ "GenMsgSendType" BO_ 581 0;
BA_ "GenMsgCycleTime" BO_ 584 20;
BA_ "GenMsgSendType" BO_ 584 0;
BA_ "GenMsgCycleTime" BO_ 585 10000;
BA_ "GenMsgILSupport" BO_ 585 0;
BA_ "GenMsgSendType" BO_ 585 0;
BA_ "GenMsgCycleTime" BO_ 588 10000;
BA_ "GenMsgILSupport" BO_ 588 0;
BA_ "GenMsgSendType" BO_ 588 0;
BA_ "GenMsgCycleTime" BO_ 596 20;
BA_ "GenMsgSendType" BO_ 596 0;
BA_ "GenMsgCycleTime" BO_ 597 20;
BA_ "GenMsgSendType" BO_ 597 0;
BA_ "GenMsgCycleTime" BO_ 641 20;
BA_ "GenMsgSendType" BO_ 641 0;
BA_ "GenMsgCycleTime" BO_ 649 20;
BA_ "GenMsgSendType" BO_ 649 0;
BA_ "GenMsgCycleTime" BO_ 654 100;
BA_ "GenMsgSendType" BO_ 654 0;
BA_ "GenMsgCycleTime" BO_ 676 1000;
BA_ "GenMsgCycleTime" BO_ 714 100;
BA_ "GenMsgSendType" BO_ 714 0;
BA_ "GenMsgCycleTime" BO_ 753 100;
BA_ "GenMsgSendType" BO_ 753 0;
BA_ "GenMsgCycleTime" BO_ 760 1000;
BA_ "GenMsgSendType" BO_ 760 0;
BA_ "GenMsgCycleTime" BO_ 761 1000;
BA_ "GenMsgSendType" BO_ 761 0;
BA_ "GenMsgSendType" BO_ 768 0;
BA_ "GenMsgCycleTime" BO_ 768 1000;
BA_ "GenMsgCycleTimeFast" BO_ 768 20;
BA_ "GenMsgNrOfRepetition" BO_ 768 2;
BA_ "GenMsgCycleTime" BO_ 769 50;
BA_ "GenMsgSendType" BO_ 769 0;
BA_ "GenMsgCycleTime" BO_ 770 1000;
BA_ "GenMsgSendType" BO_ 770 0;
BA_ "GenMsgCycleTime" BO_ 771 500;
BA_ "GenMsgSendType" BO_ 771 0;
BA_ "GenMsgCycleTime" BO_ 773 10000;
BA_ "GenMsgILSupport" BO_ 773 0;
BA_ "GenMsgSendType" BO_ 773 0;
BA_ "GenMsgCycleTime" BO_ 775 1000;
BA_ "GenMsgSendType" BO_ 775 0;
BA_ "GenMsgCycleTimeFast" BO_ 776 100;
BA_ "GenMsgNrOfRepetition" BO_ 776 3;
BA_ "GenMsgSendType" BO_ 784 0;
BA_ "GenMsgCycleTime" BO_ 784 1000;
BA_ "GenMsgCycleTimeFast" BO_ 784 20;
BA_ "GenMsgNrOfRepetition" BO_ 784 2;
BA_ "GenMsgCycleTime" BO_ 787 100;
BA_ "GenMsgSendType" BO_ 787 0;
BA_ "GenMsgCycleTime" BO_ 803 100;
BA_ "GenMsgSendType" BO_ 803 0;
BA_ "GenMsgCycleTime" BO_ 804 100;
BA_ "GenMsgSendType" BO_ 804 0;
BA_ "GenMsgCycleTime" BO_ 805 100;
BA_ "GenMsgSendType" BO_ 805 0;
BA_ "GenMsgCycleTime" BO_ 806 100;
BA_ "GenMsgSendType" BO_ 806 0;
BA_ "GenMsgCycleTime" BO_ 807 1000;
BA_ "GenMsgSendType" BO_ 807 0;
BA_ "GenMsgCycleTime" BO_ 808 1000;
BA_ "GenMsgSendType" BO_ 808 0;
BA_ "GenMsgCycleTime" BO_ 809 1000;
BA_ "GenMsgSendType" BO_ 809 0;
BA_ "GenMsgCycleTime" BO_ 816 100;
BA_ "GenMsgSendType" BO_ 816 0;
BA_ "GenMsgSendType" BO_ 818 0;
BA_ "GenMsgCycleTime" BO_ 818 100;
BA_ "GenMsgCycleTime" BO_ 827 100;
BA_ "GenMsgSendType" BO_ 827 0;
BA_ "GenMsgCycleTime" BO_ 833 100;
BA_ "GenMsgSendType" BO_ 833 0;
BA_ "GenMsgCycleTime" BO_ 835 100;
BA_ "GenMsgSendType" BO_ 835 0;
BA_ "GenMsgCycleTime" BO_ 838 100;
BA_ "GenMsgSendType" BO_ 838 0;
BA_ "GenMsgCycleTime" BO_ 840 1000;
BA_ "GenMsgSendType" BO_ 840 0;
BA_ "GenMsgCycleTime" BO_ 841 1000;
BA_ "GenMsgSendType" BO_ 841 0;
BA_ "GenMsgCycleTime" BO_ 842 100;
BA_ "GenMsgSendType" BO_ 842 0;
BA_ "GenMsgCycleTime" BO_ 844 100;
BA_ "GenMsgSendType" BO_ 844 0;
BA_ "GenMsgCycleTime" BO_ 845 100;
BA_ "GenMsgSendType" BO_ 845 0;
BA_ "GenMsgCycleTime" BO_ 846 100;
BA_ "GenMsgSendType" BO_ 846 0;
BA_ "GenMsgCycleTime" BO_ 849 50;
BA_ "GenMsgSendType" BO_ 849 0;
BA_ "GenMsgCycleTime" BO_ 850 50;
BA_ "GenMsgSendType" BO_ 850 0;
BA_ "GenMsgCycleTime" BO_ 851 50;
BA_ "GenMsgSendType" BO_ 851 0;
BA_ "GenSigTimeoutTime_ALL" SG_ 389 VCU_FS_C_1 1000;
BA_ "GenSigTimeoutTime_ALL" SG_ 389 VCU_FS_C_2 1000;
BA_ "GenSigTimeoutTime_ALL" SG_ 389 VCU_FS_C_3 1000;
BA_ "GenSigTimeoutTime_ALL" SG_ 389 VCU_FS_C_4 1000;
BA_ "GenSigTimeoutTime_ALL" SG_ 389 VCU_FS_C_5 1000;
BA_ "GenSigTimeoutTime_ALL" SG_ 389 VCU_FS_C_6 1000;
BA_ "GenSigTimeoutTime_ALL" SG_ 389 VCU_FS_C_7 1000;
BA_ "GenSigTimeoutTime_ALL" SG_ 389 VCU_FS_C_8 1000;
BA_ "GenSigTimeoutTime_ALL" SG_ 389 VCU_FS_C_9 1000;
BA_ "GenSigTimeoutTime_ALL" SG_ 389 VCU_FS_C_10 1000;
BA_ "GenSigTimeoutTime_ALL" SG_ 389 VCU_FS_C_11 1000;
BA_ "GenSigTimeoutTime_ALL" SG_ 389 VCU_FS_C_12 1000;
BA_ "GenSigTimeoutTime_ALL" SG_ 389 VCU_FS_C_13 1000;
BA_ "GenSigTimeoutTime_ALL" SG_ 389 VCU_FS_C_14 1000;
BA_ "GenSigTimeoutTime_ALL" SG_ 389 VCU_FS_C_15 1000;
BA_ "GenSigTimeoutTime_ALL" SG_ 389 VCU_FS_C_16 1000;
BA_ "GenSigTimeoutTime_ALL" SG_ 389 VCU_FS_C_17 1000;
BA_ "GenSigTimeoutTime_ALL" SG_ 389 VCU_FS_C_18 1000;
BA_ "GenSigTimeoutTime_ALL" SG_ 389 VCU_FS_C_19 1000;
BA_ "GenSigTimeoutTime_ALL" SG_ 389 VCU_FS_C_20 1000;
BA_ "GenSigTimeoutTime_ALL" SG_ 389 VCU_FS_C_21 1000;
BA_ "GenSigTimeoutTime_ALL" SG_ 389 VCU_FS_C_22 1000;
BA_ "GenSigTimeoutTime_ALL" SG_ 389 VCU_FS_C_23 1000;
BA_ "GenSigTimeoutTime_ALL" SG_ 389 VCU_FS_C_24 1000;
BA_ "GenSigTimeoutTime_ALL" SG_ 389 VCU_FS_C_25 1000;
BA_ "GenSigTimeoutTime_ALL" SG_ 389 VCU_FS_C_26 1000;
BA_ "GenSigTimeoutTime_ALL" SG_ 389 VCU_FS_C_27 1000;
BA_ "GenSigTimeoutTime_ALL" SG_ 389 VCU_FS_C_28 1000;
BA_ "GenSigTimeoutTime_ALL" SG_ 389 VCU_FS_C_29 1000;
BA_ "GenSigTimeoutTime_ALL" SG_ 389 VCU_FS_C_30 1000;
BA_ "GenSigTimeoutTime_ALL" SG_ 389 VCU_FS_C_31 1000;
BA_ "GenSigTimeoutTime_ALL" SG_ 389 VCU_FS_C_32 1000;
BA_ "GenSigTimeoutTime_ALL" SG_ 389 VCU_FS_C_33 1000;
BA_ "GenSigTimeoutTime_ALL" SG_ 389 VCU_FS_C_34 1000;
BA_ "GenSigTimeoutTime_ALL" SG_ 389 VCU_FS_C_34 1000;
BA_ "GenSigTimeoutTime_ALL" SG_ 389 VCU_FS_C_35 1000;
BA_ "GenSigTimeoutTime_ALL" SG_ 389 VCU_FS_C_36 1000;
BA_ "GenSigTimeoutTime_ALL" SG_ 389 VCU_FS_C_37 1000;
BA_ "GenSigTimeoutTime_ALL" SG_ 389 VCU_FS_C_38 1000;
BA_ "GenSigTimeoutTime_ALL" SG_ 389 VCU_FS_C_39 1000;
BA_ "GenSigTimeoutTime_ALL" SG_ 389 VCU_FS_C_40 1000;
BA_ "GenSigTimeoutTime_ALL" SG_ 389 VCU_FS_C_41 1000;
BA_ "GenSigTimeoutTime_ALL" SG_ 389 VCU_FS_C_42 1000;
BA_ "GenSigTimeoutTime_ALL" SG_ 389 VCU_FS_C_43 1000;
BA_ "GenSigTimeoutTime_ALL" SG_ 389 VCU_FS_C_44 1000;
BA_ "GenSigTimeoutTime_ALL" SG_ 389 VCU_FS_C_45 1000;
BA_ "GenSigTimeoutTime_ALL" SG_ 389 VCU_FS_C_46 1000;
BA_ "GenSigTimeoutTime_ALL" SG_ 389 VCU_FS_C_47 1000;
BA_ "GenSigTimeoutTime_ALL" SG_ 389 VCU_FS_C_48 1000;
BA_ "GenSigTimeoutTime_ALL" SG_ 389 VCU_FS_C_49 1000;
BA_ "GenSigTimeoutTime_ALL" SG_ 389 VCU_FS_C_50 1000;
BA_ "GenSigTimeoutTime_ALL" SG_ 389 VCU_FS_C_51 1000;
BA_ "GenSigTimeoutTime_ALL" SG_ 389 VCU_FS_C_52 1000;
BA_ "GenSigTimeoutTime_ALL" SG_ 389 VCU_FS_C_53 1000;
BA_ "GenSigTimeoutTime_ALL" SG_ 389 VCU_FS_C_54 1000;
BA_ "GenSigTimeoutTime_ALL" SG_ 389 VCU_FS_C_55 1000;
BA_ "GenSigTimeoutTime_ALL" SG_ 389 VCU_FS_C_56 1000;
BA_ "GenSigTimeoutTime_ALL" SG_ 389 VCU_FS_C_57 1000;
BA_ "GenSigTimeoutTime_ALL" SG_ 389 VCU_FS_C_58 1000;
BA_ "GenSigTimeoutTime_ALL" SG_ 389 VCU_FS_C_59 1000;
BA_ "GenSigTimeoutTime_ALL" SG_ 389 VCU_FS_C_60 1000;
BA_ "GenSigTimeoutTime_ALL" SG_ 389 VCU_FS_C_61 1000;
BA_ "GenSigTimeoutTime_ALL" SG_ 389 VCU_FS_C_62 1000;
BA_ "GenSigTimeoutTime_ALL" SG_ 389 VCU_FS_C_63 1000;
BA_ "GenSigTimeoutTime_ALL" SG_ 389 VCU_FS_C_64 1000;
BA_ "GenSigTimeoutTime_ALL" SG_ 409 CHSKM_VCU_Sts1 5000;
BA_ "InvalidValue" SG_ 409 CHSKM_VCU_Sts1 "null";
BA_ "GenSigTimeoutTime_ALL" SG_ 409 ALV_VCU_Sts1 5000;
BA_ "InvalidValue" SG_ 409 ALV_VCU_Sts1 "Fh";
BA_ "GenSigTimeoutTime_ALL" SG_ 409 VCU_BMS_HVOnOff_REQ 5000;
BA_ "InvalidValue" SG_ 409 VCU_BMS_HVOnOff_REQ "null";
BA_ "GenSigTimeoutTime_ALL" SG_ 417 CHSKM_V_VEH 200;
BA_ "InvalidValue" SG_ 417 CHSKM_V_VEH "null";
BA_ "GenSigTimeoutTime_ALL" SG_ 417 ALIV_V_VEH 200;
BA_ "InvalidValue" SG_ 417 ALIV_V_VEH "Fh";
BA_ "GenSigTimeoutTime_ALL" SG_ 417 V_VEH_COG 200;
BA_ "InvalidValue" SG_ 417 V_VEH_COG "FFFFh";
BA_ "GenSigTimeoutTime_ALL" SG_ 417 DVCO_VEH 200;
BA_ "InvalidValue" SG_ 417 DVCO_VEH "7h";
BA_ "GenSigStartValue" SG_ 417 QU_V_VEH_COG 8;
BA_ "GenSigTimeoutTime_ALL" SG_ 417 QU_V_VEH_COG 200;
BA_ "InvalidValue" SG_ 417 QU_V_VEH_COG "Fh";
BA_ "GenSigTimeoutTime_ALL" SG_ 504 CHKSM_EDS_OutPut_FR 200;
BA_ "GenSigTimeoutTime_ALL" SG_ 504 CHKSM_EDS_OutPut_FR 400;
BA_ "InvalidValue" SG_ 504 CHKSM_EDS_OutPut_FR "null";
BA_ "GenSigTimeoutTime_ALL" SG_ 504 ALV_EDS_OutPut_FR 400;
BA_ "GenSigTimeoutTime_ALL" SG_ 504 ALV_EDS_OutPut_FR 200;
BA_ "InvalidValue" SG_ 504 ALV_EDS_OutPut_FR "Fh";
BA_ "GenSigTimeoutTime_ALL" SG_ 504 EDS_Work_STS_FR 200;
BA_ "GenSigTimeoutTime_ALL" SG_ 504 EDS_Work_STS_FR 400;
BA_ "InvalidValue" SG_ 504 EDS_Work_STS_FR "Fh";
BA_ "GenSigStartValue" SG_ 504 EDS_Spd_FR 20000;
BA_ "GenSigTimeoutTime_ALL" SG_ 504 EDS_Spd_FR 400;
BA_ "GenSigTimeoutTime_ALL" SG_ 504 EDS_Spd_FR 200;
BA_ "InvalidValue" SG_ 504 EDS_Spd_FR "FFFFh";
BA_ "GenSigTimeoutTime_ALL" SG_ 504 EDS_output_trqValid_FR 400;
BA_ "GenSigTimeoutTime_ALL" SG_ 504 EDS_output_trqValid_FR 200;
BA_ "InvalidValue" SG_ 504 EDS_output_trqValid_FR "null";
BA_ "GenSigTimeoutTime_ALL" SG_ 504 EDS_MotorDriveSts_FR 400;
BA_ "GenSigTimeoutTime_ALL" SG_ 504 EDS_MotorDriveSts_FR 200;
BA_ "InvalidValue" SG_ 504 EDS_MotorDriveSts_FR "3h";
BA_ "GenSigTimeoutTime_ALL" SG_ 504 EDS_powoff_req_FR 200;
BA_ "GenSigTimeoutTime_ALL" SG_ 504 EDS_powoff_req_FR 400;
BA_ "InvalidValue" SG_ 504 EDS_powoff_req_FR "null";
BA_ "GenSigTimeoutTime_ALL" SG_ 504 EDS_SpdValid_FR 400;
BA_ "GenSigTimeoutTime_ALL" SG_ 504 EDS_SpdValid_FR 200;
BA_ "InvalidValue" SG_ 504 EDS_SpdValid_FR "null";
BA_ "GenSigStartValue" SG_ 504 EDS_output_trq_FR 2000;
BA_ "GenSigTimeoutTime_ALL" SG_ 504 EDS_output_trq_FR 200;
BA_ "GenSigTimeoutTime_ALL" SG_ 504 EDS_output_trq_FR 400;
BA_ "InvalidValue" SG_ 504 EDS_output_trq_FR "FFFFh";
BA_ "GenSigTimeoutTime_ALL" SG_ 504 EDS_VCU_6SO_flag_FWD 400;
BA_ "GenSigTimeoutTime_ALL" SG_ 504 EDS_VCU_6SO_flag_FWD 200;
BA_ "InvalidValue" SG_ 504 EDS_VCU_6SO_flag_FWD "null";
BA_ "GenSigTimeoutTime_ALL" SG_ 505 CHKSM_EDS_OutPut_RR 200;
BA_ "GenSigTimeoutTime_ALL" SG_ 505 CHKSM_EDS_OutPut_RR 400;
BA_ "InvalidValue" SG_ 505 CHKSM_EDS_OutPut_RR "null";
BA_ "GenSigTimeoutTime_ALL" SG_ 505 ALV_EDS_OutPut_RR 400;
BA_ "GenSigTimeoutTime_ALL" SG_ 505 ALV_EDS_OutPut_RR 200;
BA_ "InvalidValue" SG_ 505 ALV_EDS_OutPut_RR "Fh";
BA_ "GenSigTimeoutTime_ALL" SG_ 505 EDS_Work_STS_RR 200;
BA_ "GenSigTimeoutTime_ALL" SG_ 505 EDS_Work_STS_RR 400;
BA_ "InvalidValue" SG_ 505 EDS_Work_STS_RR "Fh";
BA_ "GenSigStartValue" SG_ 505 EDS_Spd_RR 20000;
BA_ "GenSigTimeoutTime_ALL" SG_ 505 EDS_Spd_RR 400;
BA_ "GenSigTimeoutTime_ALL" SG_ 505 EDS_Spd_RR 200;
BA_ "InvalidValue" SG_ 505 EDS_Spd_RR "FFFFh";
BA_ "GenSigTimeoutTime_ALL" SG_ 505 EDS_output_trqValid_RR 200;
BA_ "GenSigTimeoutTime_ALL" SG_ 505 EDS_output_trqValid_RR 400;
BA_ "InvalidValue" SG_ 505 EDS_output_trqValid_RR "null";
BA_ "GenSigTimeoutTime_ALL" SG_ 505 EDS_MotorDriveSts_RR 400;
BA_ "GenSigTimeoutTime_ALL" SG_ 505 EDS_MotorDriveSts_RR 200;
BA_ "InvalidValue" SG_ 505 EDS_MotorDriveSts_RR "3h";
BA_ "GenSigTimeoutTime_ALL" SG_ 505 EDS_powoff_req_RR 200;
BA_ "GenSigTimeoutTime_ALL" SG_ 505 EDS_powoff_req_RR 400;
BA_ "InvalidValue" SG_ 505 EDS_powoff_req_RR "null";
BA_ "GenSigTimeoutTime_ALL" SG_ 505 EDS_SpdValid_RR 200;
BA_ "GenSigTimeoutTime_ALL" SG_ 505 EDS_SpdValid_RR 400;
BA_ "InvalidValue" SG_ 505 EDS_SpdValid_RR "null";
BA_ "GenSigStartValue" SG_ 505 EDS_output_trq_RR 2000;
BA_ "GenSigTimeoutTime_ALL" SG_ 505 EDS_output_trq_RR 400;
BA_ "GenSigTimeoutTime_ALL" SG_ 505 EDS_output_trq_RR 200;
BA_ "InvalidValue" SG_ 505 EDS_output_trq_RR "FFFFh";
BA_ "GenSigTimeoutTime_ALL" SG_ 505 EDS_VCU_6SO_flag_RWD 200;
BA_ "GenSigTimeoutTime_ALL" SG_ 505 EDS_VCU_6SO_flag_RWD 400;
BA_ "InvalidValue" SG_ 505 EDS_VCU_6SO_flag_RWD "null";
BA_ "GenSigSendType" SG_ 506 MHU_TouchEvtTyp 1;
BA_ "InvalidValue" SG_ 506 MHU_TouchEvtTyp "7h";
BA_ "GenSigSendType" SG_ 506 MHU_XGestureSpd 1;
BA_ "InvalidValue" SG_ 506 MHU_XGestureSpd "FFh";
BA_ "GenSigSendType" SG_ 506 MHU_YGestureSpd 1;
BA_ "InvalidValue" SG_ 506 MHU_YGestureSpd "FFh";
BA_ "GenSigSendType" SG_ 506 MHU_Ycoordinate 1;
BA_ "InvalidValue" SG_ 506 MHU_Ycoordinate "FFFFh";
BA_ "GenSigSendType" SG_ 506 MHU_Xcoordinate 1;
BA_ "InvalidValue" SG_ 506 MHU_Xcoordinate "FFFFh";
BA_ "GenSigTimeoutTime_ALL" SG_ 515 CHKSM_Camera_rightlane 500;
BA_ "GenSigTimeoutTime_ALL" SG_ 515 ALV_Camera_rightlane 500;
BA_ "InvalidValue" SG_ 515 ALV_Camera_rightlane "Fh";
BA_ "GenSigTimeoutTime_ALL" SG_ 515 R1_LINE_TYPE 500;
BA_ "GenSigTimeoutTime_ALL" SG_ 515 R0_LINE_TYPE 500;
BA_ "GenSigTimeoutTime_ALL" SG_ 515 SECCAN_Camera_rightlane 500;
BA_ "GenSigTimeoutTime_ALL" SG_ 516 CHKSM_Camera_leftlane 500;
BA_ "GenSigTimeoutTime_ALL" SG_ 516 ALV_Camera_leftlane 500;
BA_ "InvalidValue" SG_ 516 ALV_Camera_leftlane "Fh";
BA_ "GenSigTimeoutTime_ALL" SG_ 516 L1_LINE_TYPE 500;
BA_ "InvalidValue" SG_ 516 L1_LINE_TYPE "3h";
BA_ "GenSigTimeoutTime_ALL" SG_ 516 L0_LINE_TYPE 500;
BA_ "GenSigTimeoutTime_ALL" SG_ 516 SECCAN_Camera_leftlane 500;
BA_ "GenSigTimeoutTime_ALL" SG_ 517 Checksum_0x205 200;
BA_ "InvalidValue" SG_ 517 Checksum_0x205 "null";
BA_ "GenSigTimeoutTime_ALL" SG_ 517 Rolling_Counter_0x205 200;
BA_ "InvalidValue" SG_ 517 Rolling_Counter_0x205 "Fh";
BA_ "GenSigTimeoutTime_ALL" SG_ 517 BMS_CellNumMinCellVol 200;
BA_ "InvalidValue" SG_ 517 BMS_CellNumMinCellVol "null";
BA_ "GenSigTimeoutTime_ALL" SG_ 517 BMS_CellNumMaxCellVol 200;
BA_ "InvalidValue" SG_ 517 BMS_CellNumMaxCellVol "null";
BA_ "GenSigTimeoutTime_ALL" SG_ 517 BMS_MinCellVol 200;
BA_ "InvalidValue" SG_ 517 BMS_MinCellVol "1FFFh";
BA_ "GenSigTimeoutTime_ALL" SG_ 517 BMS_MaxCellVol 200;
BA_ "InvalidValue" SG_ 517 BMS_MaxCellVol "1FFFh";
BA_ "GenSigTimeoutTime_ALL" SG_ 518 CHKSM_ADAS_ELK 500;
BA_ "InvalidValue" SG_ 518 CHKSM_ADAS_ELK "0";
BA_ "GenSigTimeoutTime_ALL" SG_ 518 ALV_ADAS_ELK 500;
BA_ "InvalidValue" SG_ 518 ALV_ADAS_ELK "Fh";
BA_ "GenSigTimeoutTime_ALL" SG_ 518 ADAS_HWA_Fautlstate 500;
BA_ "InvalidValue" SG_ 518 ADAS_HWA_Fautlstate "3h";
BA_ "GenSigTimeoutTime_ALL" SG_ 518 ADAS_ELK_check 500;
BA_ "InvalidValue" SG_ 518 ADAS_ELK_check "0";
BA_ "GenSigTimeoutTime_ALL" SG_ 518 ADAS_handsoff_Warning_Mode_2 500;
BA_ "InvalidValue" SG_ 518 ADAS_handsoff_Warning_Mode_2 "3h";
BA_ "GenSigTimeoutTime_ALL" SG_ 518 ADAS_AHB_ICON_Feed 500;
BA_ "InvalidValue" SG_ 518 ADAS_AHB_ICON_Feed "7h";
BA_ "GenSigTimeoutTime_ALL" SG_ 518 ADAS_HWA_txtpopup 500;
BA_ "InvalidValue" SG_ 518 ADAS_HWA_txtpopup "Fh";
BA_ "GenSigTimeoutTime_ALL" SG_ 518 ADAS_AHB_PopUp_Feed 500;
BA_ "InvalidValue" SG_ 518 ADAS_AHB_PopUp_Feed "Fh";
BA_ "GenSigTimeoutTime_ALL" SG_ 518 ADAS_HWA_state 500;
BA_ "InvalidValue" SG_ 518 ADAS_HWA_state "7h";
BA_ "GenSigStartValue" SG_ 518 ADAS_ALC_Mode_feed 1;
BA_ "GenSigTimeoutTime_ALL" SG_ 518 ADAS_ALC_Mode_feed 500;
BA_ "InvalidValue" SG_ 518 ADAS_ALC_Mode_feed "3h";
BA_ "GenSigTimeoutTime_ALL" SG_ 518 ADAS_handsoff_txtpopup 500;
BA_ "InvalidValue" SG_ 518 ADAS_handsoff_txtpopup "3h";
BA_ "GenSigTimeoutTime_ALL" SG_ 518 ADAS_ALC_txtpopup 500;
BA_ "InvalidValue" SG_ 518 ADAS_ALC_txtpopup "Fh";
BA_ "GenSigTimeoutTime_ALL" SG_ 518 ADAS_ALC_state 500;
BA_ "InvalidValue" SG_ 518 ADAS_ALC_state "7h";
BA_ "GenSigTimeoutTime_ALL" SG_ 518 ADAS_LA_Display 500;
BA_ "InvalidValue" SG_ 518 ADAS_LA_Display "0";
BA_ "GenSigTimeoutTime_ALL" SG_ 518 ADAS_Lane_Line_Curva_Radius 500;
BA_ "InvalidValue" SG_ 518 ADAS_Lane_Line_Curva_Radius "0";
BA_ "GenSigTimeoutTime_ALL" SG_ 519 SR_Undervoltage_Fault_Sts 500;
BA_ "InvalidValue" SG_ 519 SR_Undervoltage_Fault_Sts "null";
BA_ "GenSigTimeoutTime_ALL" SG_ 519 SR_Overvoltage_Fault_Sts 500;
BA_ "InvalidValue" SG_ 519 SR_Overvoltage_Fault_Sts "null";
BA_ "GenSigTimeoutTime_ALL" SG_ 519 SR_SLEEP_RQ 500;
BA_ "InvalidValue" SG_ 519 SR_SLEEP_RQ "null";
BA_ "GenSigTimeoutTime_ALL" SG_ 519 SR_Position 500;
BA_ "InvalidValue" SG_ 519 SR_Position "null";
BA_ "GenSigTimeoutTime_ALL" SG_ 519 SR_Motor_Running_Sts 500;
BA_ "InvalidValue" SG_ 519 SR_Motor_Running_Sts "null";
BA_ "GenSigTimeoutTime_ALL" SG_ 519 SR_MotorReverse_Fault_Sts 500;
BA_ "InvalidValue" SG_ 519 SR_MotorReverse_Fault_Sts "null";
BA_ "GenSigTimeoutTime_ALL" SG_ 519 SR_Hall_Fault_Sts 500;
BA_ "InvalidValue" SG_ 519 SR_Hall_Fault_Sts "null";
BA_ "GenSigTimeoutTime_ALL" SG_ 519 SR_Normalisation_Sts 500;
BA_ "InvalidValue" SG_ 519 SR_Normalisation_Sts "null";
BA_ "GenSigTimeoutTime_ALL" SG_ 519 SR_Relay_Fault 500;
BA_ "InvalidValue" SG_ 519 SR_Relay_Fault "null";
BA_ "GenSigTimeoutTime_ALL" SG_ 519 SR_Commu_Fault_Sts 500;
BA_ "InvalidValue" SG_ 519 SR_Commu_Fault_Sts "null";
BA_ "GenSigTimeoutTime_ALL" SG_ 519 SR_Initialisation_Status 500;
BA_ "InvalidValue" SG_ 519 SR_Initialisation_Status "null";
BA_ "GenSigTimeoutTime_ALL" SG_ 519 SR_Ctrl_Result 500;
BA_ "InvalidValue" SG_ 519 SR_Ctrl_Result "null";
BA_ "GenSigTimeoutTime_ALL" SG_ 519 SR_ThermalProtection_Fault_Sts 500;
BA_ "InvalidValue" SG_ 519 SR_ThermalProtection_Fault_Sts "null";
BA_ "GenSigTimeoutTime_ALL" SG_ 519 SR_Posit_Percentage 500;
BA_ "InvalidValue" SG_ 519 SR_Posit_Percentage "7Fh";
BA_ "GenSigTimeoutTime_ALL" SG_ 519 SR_Operation_Stat 500;
BA_ "InvalidValue" SG_ 519 SR_Operation_Stat "null";
BA_ "GenSigTimeoutTime_ALL" SG_ 519 SR_Error_RSP 500;
BA_ "InvalidValue" SG_ 519 SR_Error_RSP "null";
BA_ "GenSigTimeoutTime_ALL" SG_ 519 BCM_AutoSunroof_Sts 500;
BA_ "GenSigStartValue" SG_ 519 BCM_AutoSunroof_Sts 2;
BA_ "InvalidValue" SG_ 519 BCM_AutoSunroof_Sts "3h";
BA_ "GenSigTimeoutTime_ALL" SG_ 520 SS_MotorReverse_Fault_Status 500;
BA_ "InvalidValue" SG_ 520 SS_MotorReverse_Fault_Status "null";
BA_ "GenSigTimeoutTime_ALL" SG_ 520 SS_Motor_Running_Status 500;
BA_ "InvalidValue" SG_ 520 SS_Motor_Running_Status "null";
BA_ "GenSigTimeoutTime_ALL" SG_ 520 SS_Position 500;
BA_ "InvalidValue" SG_ 520 SS_Position "null";
BA_ "GenSigTimeoutTime_ALL" SG_ 520 SS_SLEEP_RQ 500;
BA_ "InvalidValue" SG_ 520 SS_SLEEP_RQ "null";
BA_ "GenSigTimeoutTime_ALL" SG_ 520 SS_Undervoltage_Fault_Status 500;
BA_ "InvalidValue" SG_ 520 SS_Undervoltage_Fault_Status "null";
BA_ "GenSigTimeoutTime_ALL" SG_ 520 SS_Ctrl_Result 500;
BA_ "InvalidValue" SG_ 520 SS_Ctrl_Result "null";
BA_ "GenSigTimeoutTime_ALL" SG_ 520 SS_Overvoltage_Fault_Status 500;
BA_ "InvalidValue" SG_ 520 SS_Overvoltage_Fault_Status "null";
BA_ "GenSigTimeoutTime_ALL" SG_ 520 SS_Relay_Fault 500;
BA_ "InvalidValue" SG_ 520 SS_Relay_Fault "null";
BA_ "GenSigTimeoutTime_ALL" SG_ 520 SS_Normalisation_Status 500;
BA_ "InvalidValue" SG_ 520 SS_Normalisation_Status "null";
BA_ "GenSigTimeoutTime_ALL" SG_ 520 SS_Hall_Fault_Status 500;
BA_ "InvalidValue" SG_ 520 SS_Hall_Fault_Status "null";
BA_ "GenSigTimeoutTime_ALL" SG_ 520 SS_Commu_Fault_Status 500;
BA_ "InvalidValue" SG_ 520 SS_Commu_Fault_Status "null";
BA_ "GenSigTimeoutTime_ALL" SG_ 520 SS_Initialisation_Status 500;
BA_ "InvalidValue" SG_ 520 SS_Initialisation_Status "null";
BA_ "GenSigTimeoutTime_ALL" SG_ 520 SS_Posit_Percentage 500;
BA_ "InvalidValue" SG_ 520 SS_Posit_Percentage "7Fh";
BA_ "GenSigTimeoutTime_ALL" SG_ 520 SS_ThermalProtection_Flt_Sts 500;
BA_ "InvalidValue" SG_ 520 SS_ThermalProtection_Flt_Sts "null";
BA_ "GenSigTimeoutTime_ALL" SG_ 520 SS_Operation_State 500;
BA_ "InvalidValue" SG_ 520 SS_Operation_State "null";
BA_ "GenSigTimeoutTime_ALL" SG_ 520 SECCAN_SunshadeSts 500;
BA_ "GenSigTimeoutTime_ALL" SG_ 520 SECCAN_SunshadeSts 500;
BA_ "InvalidValue" SG_ 520 SECCAN_SunshadeSts "null";
BA_ "GenSigTimeoutTime_ALL" SG_ 520 SS_Error_RSP 500;
BA_ "InvalidValue" SG_ 520 SS_Error_RSP "null";
BA_ "GenSigStartValue" SG_ 522 ETG_Lift_Gate_Status 7;
BA_ "GenSigTimeoutTime_ALL" SG_ 522 ETG_Lift_Gate_Status 500;
BA_ "InvalidValue" SG_ 522 ETG_Lift_Gate_Status "7h";
BA_ "GenSigStartValue" SG_ 522 ETG_Power_Latch_Status 7;
BA_ "GenSigTimeoutTime_ALL" SG_ 522 ETG_Power_Latch_Status 500;
BA_ "InvalidValue" SG_ 522 ETG_Power_Latch_Status "7h";
BA_ "GenSigStartValue" SG_ 522 ETG_Latch_Segment 3;
BA_ "GenSigTimeoutTime_ALL" SG_ 522 ETG_Latch_Segment 500;
BA_ "InvalidValue" SG_ 522 ETG_Latch_Segment "3h";
BA_ "GenSigTimeoutTime_ALL" SG_ 522 ETG_Opening_Percentage 500;
BA_ "InvalidValue" SG_ 522 ETG_Opening_Percentage "FFh";
BA_ "GenSigTimeoutTime_ALL" SG_ 522 ETG_DSW_Status 500;
BA_ "InvalidValue" SG_ 522 ETG_DSW_Status "null";
BA_ "GenSigTimeoutTime_ALL" SG_ 522 ETG_GSW_Status 500;
BA_ "InvalidValue" SG_ 522 ETG_GSW_Status "null";
BA_ "GenSigTimeoutTime_ALL" SG_ 522 ETG_LTS_Status 500;
BA_ "InvalidValue" SG_ 522 ETG_LTS_Status "null";
BA_ "GenSigTimeoutTime_ALL" SG_ 522 ETG_RTS_Status 500;
BA_ "InvalidValue" SG_ 522 ETG_RTS_Status "null";
BA_ "GenSigTimeoutTime_ALL" SG_ 522 ETG_HAL_Status 500;
BA_ "InvalidValue" SG_ 522 ETG_HAL_Status "null";
BA_ "GenSigTimeoutTime_ALL" SG_ 522 ETG_FUL_Status 500;
BA_ "InvalidValue" SG_ 522 ETG_FUL_Status "null";
BA_ "GenSigTimeoutTime_ALL" SG_ 522 ETG_AJR_Status 500;
BA_ "InvalidValue" SG_ 522 ETG_AJR_Status "null";
BA_ "GenSigTimeoutTime_ALL" SG_ 522 ETG_NTL_Status 500;
BA_ "InvalidValue" SG_ 522 ETG_NTL_Status "null";
BA_ "GenSigTimeoutTime_ALL" SG_ 522 ETG_ERR_Voltage 500;
BA_ "InvalidValue" SG_ 522 ETG_ERR_Voltage "null";
BA_ "GenSigTimeoutTime_ALL" SG_ 522 ETG_ERR_Left_Motor 500;
BA_ "InvalidValue" SG_ 522 ETG_ERR_Left_Motor "null";
BA_ "GenSigTimeoutTime_ALL" SG_ 522 ETG_ERR_Right_Motor 500;
BA_ "InvalidValue" SG_ 522 ETG_ERR_Right_Motor "null";
BA_ "GenSigTimeoutTime_ALL" SG_ 522 ETG_ERR_Latch 500;
BA_ "InvalidValue" SG_ 522 ETG_ERR_Latch "null";
BA_ "GenSigTimeoutTime_ALL" SG_ 522 ETG_ERR_Hall 500;
BA_ "InvalidValue" SG_ 522 ETG_ERR_Hall "null";
BA_ "GenSigTimeoutTime_ALL" SG_ 522 ETG_Lift_Motor_Stall 500;
BA_ "InvalidValue" SG_ 522 ETG_Lift_Motor_Stall "null";
BA_ "GenSigTimeoutTime_ALL" SG_ 522 ETG_Lift_Motor_AntiPinch 500;
BA_ "InvalidValue" SG_ 522 ETG_Lift_Motor_AntiPinch "null";
BA_ "GenSigTimeoutTime_ALL" SG_ 522 ETG_Lift_Motor_Thermal 500;
BA_ "InvalidValue" SG_ 522 ETG_Lift_Motor_Thermal "null";
BA_ "GenSigTimeoutTime_ALL" SG_ 522 ETG_Power_Latch_Thermal 500;
BA_ "InvalidValue" SG_ 522 ETG_Power_Latch_Thermal "null";
BA_ "GenSigTimeoutTime_ALL" SG_ 522 ETG_Abuse_Protection 500;
BA_ "InvalidValue" SG_ 522 ETG_Abuse_Protection "null";
BA_ "GenSigTimeoutTime_ALL" SG_ 523 FKS_RespError 500;
BA_ "InvalidValue" SG_ 523 FKS_RespError "null";
BA_ "GenSigTimeoutTime_ALL" SG_ 523 FKS_OpenReq 500;
BA_ "InvalidValue" SG_ 523 FKS_OpenReq "null";
BA_ "GenSigTimeoutTime_ALL" SG_ 523 FKS_HWError 500;
BA_ "InvalidValue" SG_ 523 FKS_HWError "null";
BA_ "GenSigTimeoutTime_ALL" SG_ 523 FKS_AntennaError 500;
BA_ "InvalidValue" SG_ 523 FKS_AntennaError "null";
BA_ "GenSigTimeoutTime_ALL" SG_ 523 FKS_OverVolDected 500;
BA_ "InvalidValue" SG_ 523 FKS_OverVolDected "null";
BA_ "GenSigTimeoutTime_ALL" SG_ 523 FKS_UnderVolDected 500;
BA_ "InvalidValue" SG_ 523 FKS_UnderVolDected "null";
BA_ "GenSigTimeoutTime_ALL" SG_ 523 FKS_activate_deactivate 500;
BA_ "InvalidValue" SG_ 523 FKS_activate_deactivate "null";
BA_ "GenSigTimeoutTime_ALL" SG_ 524 CHKSM_IC_ODO 500;
BA_ "InvalidValue" SG_ 524 CHKSM_IC_ODO "null";
BA_ "GenSigTimeoutTime_ALL" SG_ 524 ALIV_IC_ODO 500;
BA_ "InvalidValue" SG_ 524 ALIV_IC_ODO "Fh";
BA_ "GenSigTimeoutTime_ALL" SG_ 524 MHU_Odometer_IC 500;
BA_ "InvalidValue" SG_ 524 MHU_Odometer_IC "FFFFFh";
BA_ "GenSigTimeoutTime_ALL" SG_ 525 CHKSM_IDB_STATUS 200;
BA_ "InvalidValue" SG_ 525 CHKSM_IDB_STATUS "null";
BA_ "GenSigTimeoutTime_ALL" SG_ 525 ALV_IDB_STATUS 200;
BA_ "InvalidValue" SG_ 525 ALV_IDB_STATUS "Fh";
BA_ "GenSigTimeoutTime_ALL" SG_ 525 ESPTransRequestType 200;
BA_ "InvalidValue" SG_ 525 ESPTransRequestType "null";
BA_ "GenSigTimeoutTime_ALL" SG_ 525 ABSFault 200;
BA_ "InvalidValue" SG_ 525 ABSFault "null";
BA_ "GenSigTimeoutTime_ALL" SG_ 525 ABSActive 200;
BA_ "InvalidValue" SG_ 525 ABSActive "null";
BA_ "GenSigTimeoutTime_ALL" SG_ 525 VehicleSpd 200;
BA_ "InvalidValue" SG_ 525 VehicleSpd "null";
BA_ "GenSigTimeoutTime_ALL" SG_ 525 ESC_VehicleStandstill 200;
BA_ "InvalidValue" SG_ 525 ESC_VehicleStandstill "null";
BA_ "GenSigTimeoutTime_ALL" SG_ 525 MCPressureSts 200;
BA_ "InvalidValue" SG_ 525 MCPressureSts "null";
BA_ "GenSigTimeoutTime_ALL" SG_ 525 VehicleSpdSts 200;
BA_ "InvalidValue" SG_ 525 VehicleSpdSts "null";
BA_ "GenSigStartValue" SG_ 525 MCPressure 21;
BA_ "GenSigTimeoutTime_ALL" SG_ 525 MCPressure 200;
BA_ "InvalidValue" SG_ 525 MCPressure "FFh";
BA_ "GenSigTimeoutTime_ALL" SG_ 525 ESC_Braking_effort 200;
BA_ "InvalidValue" SG_ 525 ESC_Braking_effort "1";
BA_ "GenSigTimeoutTime_ALL" SG_ 525 BRAKE_LightonRequestEPBi 200;
BA_ "InvalidValue" SG_ 525 BRAKE_LightonRequestEPBi "null";
BA_ "GenSigTimeoutTime_ALL" SG_ 525 VDCActive 200;
BA_ "InvalidValue" SG_ 525 VDCActive "null";
BA_ "GenSigTimeoutTime_ALL" SG_ 525 TCSActive 200;
BA_ "InvalidValue" SG_ 525 TCSActive "null";
BA_ "GenSigTimeoutTime_ALL" SG_ 525 TCSAvailable 200;
BA_ "InvalidValue" SG_ 525 TCSAvailable "null";
BA_ "GenSigTimeoutTime_ALL" SG_ 525 IDBActive 200;
BA_ "InvalidValue" SG_ 525 IDBActive "null";
BA_ "GenSigTimeoutTime_ALL" SG_ 525 IDBFault 200;
BA_ "InvalidValue" SG_ 525 IDBFault "null";
BA_ "GenSigTimeoutTime_ALL" SG_ 525 ESC_VehicleHoldStat 200;
BA_ "InvalidValue" SG_ 525 ESC_VehicleHoldStat "null";
BA_ "GenSigTimeoutTime_ALL" SG_ 525 IDB_Power_Stage 200;
BA_ "InvalidValue" SG_ 525 IDB_Power_Stage "null";
BA_ "GenSigTimeoutTime_ALL" SG_ 525 ESC_BrakeReleasedFailsafe 200;
BA_ "InvalidValue" SG_ 525 ESC_BrakeReleasedFailsafe "null";
BA_ "GenSigTimeoutTime_ALL" SG_ 526 BMS_faultnumber 50000;
BA_ "GenSigTimeoutTime_ALL" SG_ 531 CHSKM_VCU_POD_reqDCDC 500;
BA_ "InvalidValue" SG_ 531 CHSKM_VCU_POD_reqDCDC "";
BA_ "GenSigTimeoutTime_ALL" SG_ 531 ALV_VCU_POD_reqDCDC 500;
BA_ "InvalidValue" SG_ 531 ALV_VCU_POD_reqDCDC "Fh";
BA_ "GenSigTimeoutTime_ALL" SG_ 531 VCU_enableDCDC 500;
BA_ "InvalidValue" SG_ 531 VCU_enableDCDC "3h";
BA_ "GenSigStartValue" SG_ 531 VCU_vDCDCRequest 224;
BA_ "GenSigTimeoutTime_ALL" SG_ 531 VCU_vDCDCRequest 500;
BA_ "InvalidValue" SG_ 531 VCU_vDCDCRequest "FFFFh";
BA_ "GenSigTimeoutTime_ALL" SG_ 531 VCU_iDCDCRequest_lim 500;
BA_ "InvalidValue" SG_ 531 VCU_iDCDCRequest_lim "FFFFh";
BA_ "GenSigTimeoutTime_ALL" SG_ 532 Checksum_0x214 500;
BA_ "GenSigTimeoutTime_ALL" SG_ 532 Rolling_Counter_0x214 500;
BA_ "InvalidValue" SG_ 532 Rolling_Counter_0x214 "Fh";
BA_ "GenSigTimeoutTime_ALL" SG_ 532 BMS_Display_SOC 500;
BA_ "InvalidValue" SG_ 532 BMS_Display_SOC "3FFh";
BA_ "InvalidValue" SG_ 532 BMS_SOCE "3FFFh";
BA_ "GenSigTimeoutTime_ALL" SG_ 532 BMS_SOCE 500;
BA_ "GenSigTimeoutTime_ALL" SG_ 533 Checksum_0x215 500;
BA_ "InvalidValue" SG_ 533 Checksum_0x215 "null";
BA_ "GenSigTimeoutTime_ALL" SG_ 533 Rolling_Counter_0x215 500;
BA_ "InvalidValue" SG_ 533 Rolling_Counter_0x215 "Fh";
BA_ "GenSigTimeoutTime_ALL" SG_ 533 BMS_BatBalance_ERR 500;
BA_ "InvalidValue" SG_ 533 BMS_BatBalance_ERR "null";
BA_ "GenSigTimeoutTime_ALL" SG_ 533 BMS_Balance_STS 500;
BA_ "InvalidValue" SG_ 533 BMS_Balance_STS "null";
BA_ "GenSigTimeoutTime_ALL" SG_ 533 BMS_IGN_Sts 500;
BA_ "InvalidValue" SG_ 533 BMS_IGN_Sts "null";
BA_ "GenSigTimeoutTime_ALL" SG_ 533 BMS_HWCrash_Sts 500;
BA_ "InvalidValue" SG_ 533 BMS_HWCrash_Sts "null";
BA_ "GenSigTimeoutTime_ALL" SG_ 533 BMS_HVIL_STS 500;
BA_ "InvalidValue" SG_ 533 BMS_HVIL_STS "3h";
BA_ "GenSigTimeoutTime_ALL" SG_ 533 BMS_HVOnOff_STS 500;
BA_ "InvalidValue" SG_ 533 BMS_HVOnOff_STS "null";
BA_ "GenSigTimeoutTime_ALL" SG_ 533 BMS_ERR_LEV 500;
BA_ "InvalidValue" SG_ 533 BMS_ERR_LEV "null";
BA_ "GenSigTimeoutTime_ALL" SG_ 533 BMS_SocActual_EST 500;
BA_ "InvalidValue" SG_ 533 BMS_SocActual_EST "3FFh";
BA_ "GenSigTimeoutTime_ALL" SG_ 533 BMS_Sys_STS 500;
BA_ "InvalidValue" SG_ 533 BMS_Sys_STS "8h";
BA_ "GenSigTimeoutTime_ALL" SG_ 533 BMS_ISU_Status 500;
BA_ "InvalidValue" SG_ 533 BMS_ISU_Status "null";
BA_ "GenSigStartValue" SG_ 533 BMS_SOH 54;
BA_ "GenSigTimeoutTime_ALL" SG_ 533 BMS_SOH 500;
BA_ "InvalidValue" SG_ 533 BMS_SOH "FFh";
BA_ "GenSigStartValue" SG_ 533 BMS_SOE 54;
BA_ "GenSigTimeoutTime_ALL" SG_ 533 BMS_SOE 500;
BA_ "InvalidValue" SG_ 533 BMS_SOE "FFh";
BA_ "GenSigTimeoutTime_ALL" SG_ 533 BMS_HV_Sts 500;
BA_ "GenSigTimeoutTime_ALL" SG_ 534 Checksum_0x216 500;
BA_ "InvalidValue" SG_ 534 Checksum_0x216 "null";
BA_ "GenSigTimeoutTime_ALL" SG_ 534 Rolling_Counter_0x216 500;
BA_ "InvalidValue" SG_ 534 Rolling_Counter_0x216 "Fh";
BA_ "GenSigTimeoutTime_ALL" SG_ 534 BMS_RemainChargeTime 500;
BA_ "InvalidValue" SG_ 534 BMS_RemainChargeTime "3FFFh";
BA_ "GenSigTimeoutTime_ALL" SG_ 534 BMS_ChgVoltage_REQ 500;
BA_ "InvalidValue" SG_ 534 BMS_ChgVoltage_REQ "3FFFh";
BA_ "GenSigTimeoutTime_ALL" SG_ 534 BMS_ChgCurrent_REQ 500;
BA_ "InvalidValue" SG_ 534 BMS_ChgCurrent_REQ "FFFh";
BA_ "GenSigSendType" SG_ 544 MHU_SET_CCUR_AirCondition 2;
BA_ "InvalidValue" SG_ 544 MHU_SET_CCUR_AirCondition "3h";
BA_ "GenSigSendType" SG_ 544 MHU_SET_CCUR_AutoAC 2;
BA_ "InvalidValue" SG_ 544 MHU_SET_CCUR_AutoAC "3h";
BA_ "GenSigSendType" SG_ 544 MHU_SET_CCUR_RearLock 2;
BA_ "InvalidValue" SG_ 544 MHU_SET_CCUR_RearLock "3h";
BA_ "GenSigSendType" SG_ 544 MHU_SET_CCUR_MaxAc 2;
BA_ "InvalidValue" SG_ 544 MHU_SET_CCUR_MaxAc "3h";
BA_ "GenSigSendType" SG_ 544 MHU_SET_CCUR_FanSpeed 2;
BA_ "GenSigStartValue" SG_ 544 MHU_SET_CCUR_FanSpeed 3;
BA_ "InvalidValue" SG_ 544 MHU_SET_CCUR_FanSpeed "7h";
BA_ "GenSigSendType" SG_ 544 MHU_SET_CCUR_Recirculation 2;
BA_ "GenSigStartValue" SG_ 544 MHU_SET_CCUR_Recirculation 1;
BA_ "InvalidValue" SG_ 544 MHU_SET_CCUR_Recirculation "3h";
BA_ "GenSigSendType" SG_ 544 MHU_SET_CCUR_Ion 2;
BA_ "InvalidValue" SG_ 544 MHU_SET_CCUR_Ion "3h";
BA_ "GenSigSendType" SG_ 544 MHU_SET_CCUR_FlapPosition 2;
BA_ "InvalidValue" SG_ 544 MHU_SET_CCUR_FlapPosition "4h";
BA_ "GenSigSendType" SG_ 544 MHU_SET_CCUR_SyncClimateZone 2;
BA_ "InvalidValue" SG_ 544 MHU_SET_CCUR_SyncClimateZone "3h";
BA_ "GenSigSendType" SG_ 544 MHU_SET_CCUR_TempRear 2;
BA_ "GenSigStartValue" SG_ 544 MHU_SET_CCUR_TempRear 40;
BA_ "InvalidValue" SG_ 544 MHU_SET_CCUR_TempRear "FFh";
BA_ "GenSigSendType" SG_ 544 MHU_SET_CCUR_FrontDefrost 2;
BA_ "InvalidValue" SG_ 544 MHU_SET_CCUR_FrontDefrost "3h";
BA_ "GenSigStartValue" SG_ 545 DrvSeatMsgStrLvl 1;
BA_ "GenSigTimeoutTime_ALL" SG_ 545 DrvSeatMsgStrLvl 800;
BA_ "InvalidValue" SG_ 545 DrvSeatMsgStrLvl "7h";
BA_ "GenSigStartValue" SG_ 545 PassSeatMsgStrLvl 1;
BA_ "GenSigTimeoutTime_ALL" SG_ 545 PassSeatMsgStrLvl 800;
BA_ "InvalidValue" SG_ 545 PassSeatMsgStrLvl "7h";
BA_ "GenSigStartValue" SG_ 545 RearDrvSeatMsgStrLvl 1;
BA_ "GenSigTimeoutTime_ALL" SG_ 545 RearDrvSeatMsgStrLvl 800;
BA_ "InvalidValue" SG_ 545 RearDrvSeatMsgStrLvl "7h";
BA_ "GenSigStartValue" SG_ 545 RearPassSeatMsgStrLvl 1;
BA_ "GenSigTimeoutTime_ALL" SG_ 545 RearPassSeatMsgStrLvl 800;
BA_ "InvalidValue" SG_ 545 RearPassSeatMsgStrLvl "7h";
BA_ "GenSigTimeoutTime_ALL" SG_ 545 DrvSeatMsgMode 800;
BA_ "InvalidValue" SG_ 545 DrvSeatMsgMode "7h";
BA_ "GenSigTimeoutTime_ALL" SG_ 545 PassSeatMsgMode 800;
BA_ "InvalidValue" SG_ 545 PassSeatMsgMode "7h";
BA_ "GenSigTimeoutTime_ALL" SG_ 545 RearDrvSeatMsgMode 800;
BA_ "InvalidValue" SG_ 545 RearDrvSeatMsgMode "7h";
BA_ "GenSigTimeoutTime_ALL" SG_ 545 RearPassSeatMsgMode 800;
BA_ "InvalidValue" SG_ 545 RearPassSeatMsgMode "7h";
BA_ "GenSigTimeoutTime_ALL" SG_ 546 DrvSeatMsgModeStat 800;
BA_ "InvalidValue" SG_ 546 DrvSeatMsgModeStat "7h";
BA_ "GenSigTimeoutTime_ALL" SG_ 546 PassSeatMsgModeStat 800;
BA_ "InvalidValue" SG_ 546 PassSeatMsgModeStat "7h";
BA_ "GenSigTimeoutTime_ALL" SG_ 546 RearDrvSeatMsgModeStat 800;
BA_ "InvalidValue" SG_ 546 RearDrvSeatMsgModeStat "7h";
BA_ "GenSigTimeoutTime_ALL" SG_ 546 RearPassSeatMsgModeStat 800;
BA_ "InvalidValue" SG_ 546 RearPassSeatMsgModeStat "7h";
BA_ "GenSigTimeoutTime_ALL" SG_ 546 LSSM_ALINResErr 800;
BA_ "InvalidValue" SG_ 546 LSSM_ALINResErr "null";
BA_ "GenSigTimeoutTime_ALL" SG_ 546 LSSM_APumpFail 800;
BA_ "InvalidValue" SG_ 546 LSSM_APumpFail "null";
BA_ "GenSigStartValue" SG_ 546 DrvSeatMsgStrLvlStat 1;
BA_ "GenSigTimeoutTime_ALL" SG_ 546 DrvSeatMsgStrLvlStat 800;
BA_ "InvalidValue" SG_ 546 DrvSeatMsgStrLvlStat "7h";
BA_ "GenSigTimeoutTime_ALL" SG_ 546 LSSM_BLINResErr 800;
BA_ "InvalidValue" SG_ 546 LSSM_BLINResErr "null";
BA_ "GenSigTimeoutTime_ALL" SG_ 546 LSSM_BPumpFail 800;
BA_ "InvalidValue" SG_ 546 LSSM_BPumpFail "null";
BA_ "GenSigStartValue" SG_ 546 PassSeatMsgStrLvlStat 1;
BA_ "GenSigTimeoutTime_ALL" SG_ 546 PassSeatMsgStrLvlStat 800;
BA_ "InvalidValue" SG_ 546 PassSeatMsgStrLvlStat "7h";
BA_ "GenSigTimeoutTime_ALL" SG_ 546 LSSM_CLINResErr 800;
BA_ "InvalidValue" SG_ 546 LSSM_CLINResErr "null";
BA_ "GenSigTimeoutTime_ALL" SG_ 546 LSSM_CPumpFail 800;
BA_ "InvalidValue" SG_ 546 LSSM_CPumpFail "null";
BA_ "GenSigStartValue" SG_ 546 RearDrvSeatMsgStrLvlStat 1;
BA_ "GenSigTimeoutTime_ALL" SG_ 546 RearDrvSeatMsgStrLvlStat 800;
BA_ "InvalidValue" SG_ 546 RearDrvSeatMsgStrLvlStat "7h";
BA_ "GenSigTimeoutTime_ALL" SG_ 546 LSSM_DLINResErr 800;
BA_ "InvalidValue" SG_ 546 LSSM_DLINResErr "null";
BA_ "GenSigTimeoutTime_ALL" SG_ 546 LSSM_DPumpFail 800;
BA_ "InvalidValue" SG_ 546 LSSM_DPumpFail "null";
BA_ "GenSigStartValue" SG_ 546 RearPassSeatMsgStrLvlStat 1;
BA_ "GenSigTimeoutTime_ALL" SG_ 546 RearPassSeatMsgStrLvlStat 800;
BA_ "InvalidValue" SG_ 546 RearPassSeatMsgStrLvlStat "7h";
BA_ "GenSigTimeoutTime_ALL" SG_ 549 Checksum_0x225 200;
BA_ "InvalidValue" SG_ 549 Checksum_0x225 "null";
BA_ "GenSigTimeoutTime_ALL" SG_ 549 Rolling_Counter_0x225 200;
BA_ "InvalidValue" SG_ 549 Rolling_Counter_0x225 "Fh";
BA_ "GenSigTimeoutTime_ALL" SG_ 549 CDM_bAcvCanComStblMon 200;
BA_ "InvalidValue" SG_ 549 CDM_bAcvCanComStblMon "null";
BA_ "GenSigTimeoutTime_ALL" SG_ 549 FRMo_bErrHvbatStReqExtMon 200;
BA_ "InvalidValue" SG_ 549 FRMo_bErrHvbatStReqExtMon "null";
BA_ "GenSigTimeoutTime_ALL" SG_ 549 FRMo_bErrChrgnAllwdExtMon 200;
BA_ "InvalidValue" SG_ 549 FRMo_bErrChrgnAllwdExtMon "null";
BA_ "GenSigTimeoutTime_ALL" SG_ 549 FRMo_bErrVehCrashStExtMon 200;
BA_ "InvalidValue" SG_ 549 FRMo_bErrVehCrashStExtMon "null";
BA_ "GenSigTimeoutTime_ALL" SG_ 549 CDM_bErrComctnLossCanMon 200;
BA_ "InvalidValue" SG_ 549 CDM_bErrComctnLossCanMon "null";
BA_ "GenSigTimeoutTime_ALL" SG_ 549 CTCMon_bErrCtctrSopcMon 200;
BA_ "InvalidValue" SG_ 549 CTCMon_bErrCtctrSopcMon "null";
BA_ "GenSigTimeoutTime_ALL" SG_ 549 CTCMon_bInvldCtctrHisdIFbMon 200;
BA_ "InvalidValue" SG_ 549 CTCMon_bInvldCtctrHisdIFbMon "null";
BA_ "GenSigTimeoutTime_ALL" SG_ 549 CTCMon_bInvldCtctrLosdUFbMon 200;
BA_ "InvalidValue" SG_ 549 CTCMon_bInvldCtctrLosdUFbMon "null";
BA_ "GenSigTimeoutTime_ALL" SG_ 549 CTM_bErrCellTDifMaxMon 200;
BA_ "InvalidValue" SG_ 549 CTM_bErrCellTDifMaxMon "null";
BA_ "GenSigTimeoutTime_ALL" SG_ 549 CTM_bErrCellTMaxMon 200;
BA_ "InvalidValue" SG_ 549 CTM_bErrCellTMaxMon "null";
BA_ "GenSigTimeoutTime_ALL" SG_ 549 CTM_bErrCellTMinMon 200;
BA_ "InvalidValue" SG_ 549 CTM_bErrCellTMinMon "null";
BA_ "GenSigTimeoutTime_ALL" SG_ 549 CTM_bErrThrwyPredMon 200;
BA_ "InvalidValue" SG_ 549 CTM_bErrThrwyPredMon "null";
BA_ "GenSigTimeoutTime_ALL" SG_ 549 CUM_bErrCellUDifMaxMon 200;
BA_ "InvalidValue" SG_ 549 CUM_bErrCellUDifMaxMon "null";
BA_ "GenSigTimeoutTime_ALL" SG_ 549 CUM_bErrCellUMaxMon 200;
BA_ "InvalidValue" SG_ 549 CUM_bErrCellUMaxMon "null";
BA_ "GenSigTimeoutTime_ALL" SG_ 549 CUM_bErrCellUMinMon 200;
BA_ "InvalidValue" SG_ 549 CUM_bErrCellUMinMon "null";
BA_ "GenSigTimeoutTime_ALL" SG_ 549 CUM_bErrCellUProtnMaxNvMon 200;
BA_ "InvalidValue" SG_ 549 CUM_bErrCellUProtnMaxNvMon "null";
BA_ "GenSigTimeoutTime_ALL" SG_ 549 CUM_bErrCellUProtnMinNvMon 200;
BA_ "InvalidValue" SG_ 549 CUM_bErrCellUProtnMinNvMon "null";
BA_ "GenSigTimeoutTime_ALL" SG_ 549 CUM_bErrPackUImplyMon 200;
BA_ "InvalidValue" SG_ 549 CUM_bErrPackUImplyMon "null";
BA_ "GenSigTimeoutTime_ALL" SG_ 549 EHPMon_bRdyHvilMon 200;
BA_ "InvalidValue" SG_ 549 EHPMon_bRdyHvilMon "null";
BA_ "GenSigTimeoutTime_ALL" SG_ 549 EHPMon_bErrWlddNegNvMon 200;
BA_ "InvalidValue" SG_ 549 EHPMon_bErrWlddNegNvMon "null";
BA_ "GenSigTimeoutTime_ALL" SG_ 549 EHPMon_bErrWlddPosNvMon 200;
BA_ "InvalidValue" SG_ 549 EHPMon_bErrWlddPosNvMon "null";
BA_ "GenSigTimeoutTime_ALL" SG_ 549 EHPMon_bErrWlddPrechNvMon 200;
BA_ "InvalidValue" SG_ 549 EHPMon_bErrWlddPrechNvMon "null";
BA_ "GenSigTimeoutTime_ALL" SG_ 549 EHPMon_bErrHvilMon 200;
BA_ "InvalidValue" SG_ 549 EHPMon_bErrHvilMon "null";
BA_ "GenSigTimeoutTime_ALL" SG_ 549 EHPMon_bErrHvilShoMon 200;
BA_ "InvalidValue" SG_ 549 EHPMon_bErrHvilShoMon "null";
BA_ "GenSigTimeoutTime_ALL" SG_ 549 EHPMon_bErrPackIslnRNvMon 200;
BA_ "InvalidValue" SG_ 549 EHPMon_bErrPackIslnRNvMon "null";
BA_ "GenSigTimeoutTime_ALL" SG_ 549 EHPMon_bErrVehCrashNvMon 200;
BA_ "InvalidValue" SG_ 549 EHPMon_bErrVehCrashNvMon "null";
BA_ "GenSigTimeoutTime_ALL" SG_ 549 EHPMon_bErrVehIslnRNvMon 200;
BA_ "InvalidValue" SG_ 549 EHPMon_bErrVehIslnRNvMon "null";
BA_ "GenSigTimeoutTime_ALL" SG_ 549 FRMo_bErrMemStorgNvMon 200;
BA_ "InvalidValue" SG_ 549 FRMo_bErrMemStorgNvMon "null";
BA_ "GenSigTimeoutTime_ALL" SG_ 549 L1IM_bErrClmp30MaxMonInp 200;
BA_ "InvalidValue" SG_ 549 L1IM_bErrClmp30MaxMonInp "null";
BA_ "GenSigTimeoutTime_ALL" SG_ 549 L1IM_bErrClmp30MinMonInp 200;
BA_ "InvalidValue" SG_ 549 L1IM_bErrClmp30MinMonInp "null";
BA_ "GenSigTimeoutTime_ALL" SG_ 549 L1IM_bErrCtctrDtrtMonInp 200;
BA_ "InvalidValue" SG_ 549 L1IM_bErrCtctrDtrtMonInp "null";
BA_ "GenSigTimeoutTime_ALL" SG_ 549 L1IM_bErrUActImplyMonInp 200;
BA_ "InvalidValue" SG_ 549 L1IM_bErrUActImplyMonInp "null";
BA_ "GenSigTimeoutTime_ALL" SG_ 549 MCCM_bAcvMdulCtlrStsMon 200;
BA_ "InvalidValue" SG_ 549 MCCM_bAcvMdulCtlrStsMon "null";
BA_ "GenSigTimeoutTime_ALL" SG_ 549 MCCM_bErrLntecSngFltMon 200;
BA_ "InvalidValue" SG_ 549 MCCM_bErrLntecSngFltMon "null";
BA_ "GenSigTimeoutTime_ALL" SG_ 549 MCCM_bErrLntecLtntFltMon 200;
BA_ "InvalidValue" SG_ 549 MCCM_bErrLntecLtntFltMon "null";
BA_ "GenSigTimeoutTime_ALL" SG_ 549 MCCM_bErrMdulCellSnsrCfgMon 200;
BA_ "InvalidValue" SG_ 549 MCCM_bErrMdulCellSnsrCfgMon "null";
BA_ "GenSigTimeoutTime_ALL" SG_ 549 MCCM_bErrMdulCtlrComMon 200;
BA_ "InvalidValue" SG_ 549 MCCM_bErrMdulCtlrComMon "null";
BA_ "GenSigTimeoutTime_ALL" SG_ 549 MCCM_bErrSnsrTEltlMon 200;
BA_ "InvalidValue" SG_ 549 MCCM_bErrSnsrTEltlMon "null";
BA_ "GenSigTimeoutTime_ALL" SG_ 549 MCCM_bWarnSnsrTEltlMon 200;
BA_ "InvalidValue" SG_ 549 MCCM_bWarnSnsrTEltlMon "null";
BA_ "GenSigTimeoutTime_ALL" SG_ 549 PCM_bRdySnsrIMon 200;
BA_ "InvalidValue" SG_ 549 PCM_bRdySnsrIMon "null";
BA_ "GenSigTimeoutTime_ALL" SG_ 549 PCM_bErrPackEFlowMaxLimMon 200;
BA_ "InvalidValue" SG_ 549 PCM_bErrPackEFlowMaxLimMon "null";
BA_ "GenSigTimeoutTime_ALL" SG_ 549 PCM_bErrPackIChDchaMaxLimMon 200;
BA_ "InvalidValue" SG_ 549 PCM_bErrPackIChDchaMaxLimMon "null";
BA_ "GenSigTimeoutTime_ALL" SG_ 549 PCM_bErrSnsrIImplyMon 200;
BA_ "InvalidValue" SG_ 549 PCM_bErrSnsrIImplyMon "null";
BA_ "GenSigTimeoutTime_ALL" SG_ 549 FRMo_bErrSnsrI1ExtMon 200;
BA_ "InvalidValue" SG_ 549 FRMo_bErrSnsrI1ExtMon "null";
BA_ "GenSigTimeoutTime_ALL" SG_ 549 PCM_bInvldSnsrI1Mon 200;
BA_ "InvalidValue" SG_ 549 PCM_bInvldSnsrI1Mon "null";
BA_ "GenSigTimeoutTime_ALL" SG_ 549 PCM_bInvldSnsrI2Mon 200;
BA_ "InvalidValue" SG_ 549 PCM_bInvldSnsrI2Mon "null";
BA_ "GenSigTimeoutTime_ALL" SG_ 549 FRMo_bErrSopcLvl3Mon 200;
BA_ "InvalidValue" SG_ 549 FRMo_bErrSopcLvl3Mon "null";
BA_ "GenSigTimeoutTime_ALL" SG_ 549 BMS_FRMo_Reserved_1 200;
BA_ "InvalidValue" SG_ 549 BMS_FRMo_Reserved_1 "null";
BA_ "GenSigTimeoutTime_ALL" SG_ 549 BMS_FRMo_Reserved_2 200;
BA_ "InvalidValue" SG_ 549 BMS_FRMo_Reserved_2 "null";
BA_ "GenSigTimeoutTime_ALL" SG_ 549 BMS_FRMo_Reserved_3 200;
BA_ "InvalidValue" SG_ 549 BMS_FRMo_Reserved_3 "null";
BA_ "GenSigTimeoutTime_ALL" SG_ 549 BMS_FRMo_Reserved_4 200;
BA_ "InvalidValue" SG_ 549 BMS_FRMo_Reserved_4 "null";
BA_ "GenSigTimeoutTime_ALL" SG_ 549 BMS_FRMo_Reserved_5 200;
BA_ "InvalidValue" SG_ 549 BMS_FRMo_Reserved_5 "null";
BA_ "GenSigTimeoutTime_ALL" SG_ 561 NDoorFLOutsideHandleFailure 200;
BA_ "InvalidValue" SG_ 561 NDoorFLOutsideHandleFailure "null";
BA_ "GenSigTimeoutTime_ALL" SG_ 561 NDoorLatchFLFailure 200;
BA_ "InvalidValue" SG_ 561 NDoorLatchFLFailure "null";
BA_ "GenSigTimeoutTime_ALL" SG_ 565 CHKSM_TRM_STATUS 500;
BA_ "InvalidValue" SG_ 565 CHKSM_TRM_STATUS "null";
BA_ "GenSigTimeoutTime_ALL" SG_ 565 ALIVE_TRM_STATUS 500;
BA_ "InvalidValue" SG_ 565 ALIVE_TRM_STATUS "Fh";
BA_ "GenSigTimeoutTime_ALL" SG_ 565 TowingDetected 500;
BA_ "InvalidValue" SG_ 565 TowingDetected "3h";
BA_ "GenSigTimeoutTime_ALL" SG_ 565 TrailerDetected 500;
BA_ "InvalidValue" SG_ 565 TrailerDetected "3h";
BA_ "GenSigStartValue" SG_ 569 NDoorRROutsideHandleFailure 1;
BA_ "GenSigTimeoutTime_ALL" SG_ 569 NDoorRROutsideHandleFailure 200;
BA_ "InvalidValue" SG_ 569 NDoorRROutsideHandleFailure "null";
BA_ "GenSigTimeoutTime_ALL" SG_ 569 NDoorLatchRRFailure 200;
BA_ "InvalidValue" SG_ 569 NDoorLatchRRFailure "null";
BA_ "GenSigTimeoutTime_ALL" SG_ 581 Checksum_0x245 200;
BA_ "GenSigTimeoutTime_ALL" SG_ 581 Checksum_0x245 200;
BA_ "GenSigTimeoutTime_ALL" SG_ 581 Checksum_0x245 200;
BA_ "InvalidValue" SG_ 581 Checksum_0x245 "null";
BA_ "GenSigTimeoutTime_ALL" SG_ 581 Rolling_Counter_0x245 200;
BA_ "GenSigTimeoutTime_ALL" SG_ 581 Rolling_Counter_0x245 200;
BA_ "GenSigTimeoutTime_ALL" SG_ 581 Rolling_Counter_0x245 200;
BA_ "InvalidValue" SG_ 581 Rolling_Counter_0x245 "Fh";
BA_ "GenSigStartValue" SG_ 581 BMS_ProbeNumMaxCellTemp 1;
BA_ "GenSigTimeoutTime_ALL" SG_ 581 BMS_ProbeNumMaxCellTemp 200;
BA_ "GenSigTimeoutTime_ALL" SG_ 581 BMS_ProbeNumMaxCellTemp 200;
BA_ "GenSigTimeoutTime_ALL" SG_ 581 BMS_ProbeNumMaxCellTemp 200;
BA_ "InvalidValue" SG_ 581 BMS_ProbeNumMaxCellTemp "null";
BA_ "GenSigStartValue" SG_ 581 BMS_MinCellTemp 80;
BA_ "GenSigTimeoutTime_ALL" SG_ 581 BMS_MinCellTemp 200;
BA_ "GenSigTimeoutTime_ALL" SG_ 581 BMS_MinCellTemp 200;
BA_ "GenSigTimeoutTime_ALL" SG_ 581 BMS_MinCellTemp 200;
BA_ "InvalidValue" SG_ 581 BMS_MinCellTemp "FFh";
BA_ "GenSigTimeoutTime_ALL" SG_ 581 BMS_ProbeNumMinCellTemp 200;
BA_ "GenSigTimeoutTime_ALL" SG_ 581 BMS_ProbeNumMinCellTemp 200;
BA_ "GenSigTimeoutTime_ALL" SG_ 581 BMS_ProbeNumMinCellTemp 200;
BA_ "InvalidValue" SG_ 581 BMS_ProbeNumMinCellTemp "null";
BA_ "GenSigStartValue" SG_ 581 BMS_PackTemp 80;
BA_ "GenSigTimeoutTime_ALL" SG_ 581 BMS_PackTemp 200;
BA_ "GenSigTimeoutTime_ALL" SG_ 581 BMS_PackTemp 200;
BA_ "GenSigTimeoutTime_ALL" SG_ 581 BMS_PackTemp 200;
BA_ "InvalidValue" SG_ 581 BMS_PackTemp "FFh";
BA_ "GenSigStartValue" SG_ 581 BMS_MaxCellTemp 80;
BA_ "GenSigTimeoutTime_ALL" SG_ 581 BMS_MaxCellTemp 200;
BA_ "GenSigTimeoutTime_ALL" SG_ 581 BMS_MaxCellTemp 200;
BA_ "GenSigTimeoutTime_ALL" SG_ 581 BMS_MaxCellTemp 200;
BA_ "InvalidValue" SG_ 581 BMS_MaxCellTemp "FFh";
BA_ "GenSigStartValue" SG_ 581 BMS_MaxMinDiffCellTemp 80;
BA_ "GenSigTimeoutTime_ALL" SG_ 581 BMS_MaxMinDiffCellTemp 200;
BA_ "GenSigTimeoutTime_ALL" SG_ 581 BMS_MaxMinDiffCellTemp 200;
BA_ "GenSigTimeoutTime_ALL" SG_ 581 BMS_MaxMinDiffCellTemp 200;
BA_ "InvalidValue" SG_ 581 BMS_MaxMinDiffCellTemp "FFh";
BA_ "GenSigTimeoutTime_ALL" SG_ 584 NDoorFROutsideHandleFailure 200;
BA_ "InvalidValue" SG_ 584 NDoorFROutsideHandleFailure "null";
BA_ "GenSigTimeoutTime_ALL" SG_ 584 NDoorLatchFRFailure 200;
BA_ "InvalidValue" SG_ 584 NDoorLatchFRFailure "null";
BA_ "GenSigTimeoutTime_ALL" SG_ 585 CHSKM_BMS_CoolntInletOutletTmp 50000;
BA_ "InvalidValue" SG_ 585 CHSKM_BMS_CoolntInletOutletTmp "null";
BA_ "GenSigTimeoutTime_ALL" SG_ 585 ALV_BMS_CoolntInletOutletTmp 50000;
BA_ "InvalidValue" SG_ 585 ALV_BMS_CoolntInletOutletTmp "Fh";
BA_ "GenSigStartValue" SG_ 585 BMS_CoolantInletTemp 80;
BA_ "GenSigTimeoutTime_ALL" SG_ 585 BMS_CoolantInletTemp 50000;
BA_ "InvalidValue" SG_ 585 BMS_CoolantInletTemp "null";
BA_ "GenSigStartValue" SG_ 585 BMS_CoolantOutletTemp 80;
BA_ "GenSigTimeoutTime_ALL" SG_ 585 BMS_CoolantOutletTemp 50000;
BA_ "InvalidValue" SG_ 585 BMS_CoolantOutletTemp "null";
BA_ "GenSigStartValue" SG_ 585 BMS_BDUTemp1 80;
BA_ "GenSigTimeoutTime_ALL" SG_ 585 BMS_BDUTemp1 50000;
BA_ "GenSigStartValue" SG_ 585 BMS_BDUTemp2 80;
BA_ "GenSigTimeoutTime_ALL" SG_ 585 BMS_BDUTemp2 50000;
BA_ "GenSigTimeoutTime_ALL" SG_ 588 CHSKM_BMS_VCU_THMReq 50000;
BA_ "InvalidValue" SG_ 588 CHSKM_BMS_VCU_THMReq "null";
BA_ "GenSigTimeoutTime_ALL" SG_ 588 ALV_BMS_VCU_THMReq 50000;
BA_ "InvalidValue" SG_ 588 ALV_BMS_VCU_THMReq "Fh";
BA_ "GenSigTimeoutTime_ALL" SG_ 588 BMS_FlowRate_Req 50000;
BA_ "InvalidValue" SG_ 588 BMS_FlowRate_Req "FFh";
BA_ "GenSigTimeoutTime_ALL" SG_ 588 BMS_CoolPwrDemand 50000;
BA_ "InvalidValue" SG_ 588 BMS_CoolPwrDemand "FFFh";
BA_ "GenSigTimeoutTime_ALL" SG_ 588 BMS_HeatPwrDemand 50000;
BA_ "InvalidValue" SG_ 588 BMS_HeatPwrDemand "FFFh";
BA_ "GenSigTimeoutTime_ALL" SG_ 588 BMS_VCU_PTCOnOff_Req 50000;
BA_ "InvalidValue" SG_ 588 BMS_VCU_PTCOnOff_Req "null";
BA_ "GenSigTimeoutTime_ALL" SG_ 588 BMS_VCU_ValveOnOff_Req 50000;
BA_ "InvalidValue" SG_ 588 BMS_VCU_ValveOnOff_Req "null";
BA_ "GenSigTimeoutTime_ALL" SG_ 588 BMS_PreHeatCoolReq 50000;
BA_ "InvalidValue" SG_ 588 BMS_PreHeatCoolReq "3h";
BA_ "GenSigTimeoutTime_ALL" SG_ 596 CRC_AVL_RPM_WHL_REAR 200;
BA_ "GenSigTimeoutTime_ALL" SG_ 596 CRC_AVL_RPM_WHL_REAR 200;
BA_ "InvalidValue" SG_ 596 CRC_AVL_RPM_WHL_REAR "null";
BA_ "GenSigTimeoutTime_ALL" SG_ 596 ALIV_AVL_RPM_WHL_REAR 200;
BA_ "GenSigTimeoutTime_ALL" SG_ 596 ALIV_AVL_RPM_WHL_REAR 200;
BA_ "InvalidValue" SG_ 596 ALIV_AVL_RPM_WHL_REAR "Fh";
BA_ "GenSigStartValue" SG_ 596 AVL_RPM_WHL_RLH 32819;
BA_ "GenSigTimeoutTime_ALL" SG_ 596 AVL_RPM_WHL_RLH 200;
BA_ "GenSigTimeoutTime_ALL" SG_ 596 AVL_RPM_WHL_RLH 200;
BA_ "InvalidValue" SG_ 596 AVL_RPM_WHL_RLH "null";
BA_ "InvalidValue" SG_ 596 AVL_RPM_WHL_RLH "null";
BA_ "InvalidValue" SG_ 596 AVL_RPM_WHL_RLH "0";
BA_ "GenSigStartValue" SG_ 596 AVL_RPM_WHL_RRH 32819;
BA_ "GenSigTimeoutTime_ALL" SG_ 596 AVL_RPM_WHL_RRH 200;
BA_ "GenSigTimeoutTime_ALL" SG_ 596 AVL_RPM_WHL_RRH 200;
BA_ "InvalidValue" SG_ 596 AVL_RPM_WHL_RRH "0";
BA_ "InvalidValue" SG_ 596 AVL_RPM_WHL_RRH "null";
BA_ "InvalidValue" SG_ 596 AVL_RPM_WHL_RRH "null";
BA_ "GenSigTimeoutTime_ALL" SG_ 596 QU_AVL_RPM_WHL_RLH 200;
BA_ "GenSigTimeoutTime_ALL" SG_ 596 QU_AVL_RPM_WHL_RLH 200;
BA_ "InvalidValue" SG_ 596 QU_AVL_RPM_WHL_RLH "FFh";
BA_ "InvalidValue" SG_ 596 QU_AVL_RPM_WHL_RLH "Fh";
BA_ "GenSigTimeoutTime_ALL" SG_ 596 QU_AVL_RPM_WHL_RRH 200;
BA_ "GenSigTimeoutTime_ALL" SG_ 596 QU_AVL_RPM_WHL_RRH 200;
BA_ "InvalidValue" SG_ 596 QU_AVL_RPM_WHL_RRH "FFh";
BA_ "InvalidValue" SG_ 596 QU_AVL_RPM_WHL_RRH "Fh";
BA_ "GenSigTimeoutTime_ALL" SG_ 597 CRC_AVL_RPM_WHL_FRONT 200;
BA_ "GenSigTimeoutTime_ALL" SG_ 597 CRC_AVL_RPM_WHL_FRONT 200;
BA_ "InvalidValue" SG_ 597 CRC_AVL_RPM_WHL_FRONT "null";
BA_ "GenSigTimeoutTime_ALL" SG_ 597 ALIV_AVL_RPM_WHL_FRONT 200;
BA_ "GenSigTimeoutTime_ALL" SG_ 597 ALIV_AVL_RPM_WHL_FRONT 200;
BA_ "InvalidValue" SG_ 597 ALIV_AVL_RPM_WHL_FRONT "Fh";
BA_ "GenSigStartValue" SG_ 597 AVL_RPM_WHL_FLH 32819;
BA_ "GenSigTimeoutTime_ALL" SG_ 597 AVL_RPM_WHL_FLH 200;
BA_ "GenSigTimeoutTime_ALL" SG_ 597 AVL_RPM_WHL_FLH 200;
BA_ "InvalidValue" SG_ 597 AVL_RPM_WHL_FLH "null";
BA_ "InvalidValue" SG_ 597 AVL_RPM_WHL_FLH "null";
BA_ "InvalidValue" SG_ 597 AVL_RPM_WHL_FLH "0";
BA_ "GenSigStartValue" SG_ 597 AVL_RPM_WHL_FRH 32819;
BA_ "GenSigTimeoutTime_ALL" SG_ 597 AVL_RPM_WHL_FRH 200;
BA_ "GenSigTimeoutTime_ALL" SG_ 597 AVL_RPM_WHL_FRH 200;
BA_ "InvalidValue" SG_ 597 AVL_RPM_WHL_FRH "null";
BA_ "InvalidValue" SG_ 597 AVL_RPM_WHL_FRH "null";
BA_ "InvalidValue" SG_ 597 AVL_RPM_WHL_FRH "0";
BA_ "GenSigTimeoutTime_ALL" SG_ 597 QU_AVL_RPM_WHL_FLH 200;
BA_ "GenSigTimeoutTime_ALL" SG_ 597 QU_AVL_RPM_WHL_FLH 200;
BA_ "InvalidValue" SG_ 597 QU_AVL_RPM_WHL_FLH "Fh";
BA_ "GenSigTimeoutTime_ALL" SG_ 597 QU_AVL_RPM_WHL_FRH 200;
BA_ "GenSigTimeoutTime_ALL" SG_ 597 QU_AVL_RPM_WHL_FRH 200;
BA_ "InvalidValue" SG_ 597 QU_AVL_RPM_WHL_FRH "Fh";
BA_ "GenSigTimeoutTime_ALL" SG_ 641 NDoorRLOutsideHandleFailure 200;
BA_ "InvalidValue" SG_ 641 NDoorRLOutsideHandleFailure "null";
BA_ "GenSigTimeoutTime_ALL" SG_ 641 NDoorLatchRLFailure 200;
BA_ "InvalidValue" SG_ 641 NDoorLatchRLFailure "null";
BA_ "GenSigTimeoutTime_ALL" SG_ 649 CHKSM_IDB_ZF2 200;
BA_ "InvalidValue" SG_ 649 CHKSM_IDB_ZF2 "0";
BA_ "GenSigTimeoutTime_ALL" SG_ 649 ALIVE_IDB_ZF2 200;
BA_ "InvalidValue" SG_ 649 ALIVE_IDB_ZF2 "Fh";
BA_ "GenSigTimeoutTime_ALL" SG_ 649 AxOutStatus 200;
BA_ "InvalidValue" SG_ 649 AxOutStatus "1h";
BA_ "GenSigStartValue" SG_ 649 QU_VYAW_VEH 8;
BA_ "GenSigTimeoutTime_ALL" SG_ 649 QU_VYAW_VEH 200;
BA_ "InvalidValue" SG_ 649 QU_VYAW_VEH "Fh";
BA_ "GenSigTimeoutTime_ALL" SG_ 649 AyOutStatus 200;
BA_ "InvalidValue" SG_ 649 AyOutStatus "1h";
BA_ "GenSigStartValue" SG_ 649 AcceleratorY 795;
BA_ "GenSigTimeoutTime_ALL" SG_ 649 AcceleratorY 200;
BA_ "InvalidValue" SG_ 649 AcceleratorY "FFFh";
BA_ "GenSigTimeoutTime_ALL" SG_ 649 AcceleratorX 200;
BA_ "InvalidValue" SG_ 649 AcceleratorX "FFFh";
BA_ "GenSigStartValue" SG_ 649 VYAW_VEH 32768;
BA_ "GenSigTimeoutTime_ALL" SG_ 649 VYAW_VEH 200;
BA_ "InvalidValue" SG_ 649 VYAW_VEH "FFFFh";
BA_ "GenSigTimeoutTime_ALL" SG_ 654 CHKSM_APM_WINDOW_POS 500;
BA_ "InvalidValue" SG_ 654 CHKSM_APM_WINDOW_POS "null";
BA_ "GenSigTimeoutTime_ALL" SG_ 654 ALV_APM_WINDOW_POS 500;
BA_ "InvalidValue" SG_ 654 ALV_APM_WINDOW_POS "Fh";
BA_ "GenSigTimeoutTime_ALL" SG_ 654 Window_PosFL 500;
BA_ "InvalidValue" SG_ 654 Window_PosFL "7h";
BA_ "GenSigTimeoutTime_ALL" SG_ 654 Window_Warning 500;
BA_ "InvalidValue" SG_ 654 Window_Warning "3h";
BA_ "GenSigTimeoutTime_ALL" SG_ 654 Wndow_PosRL 500;
BA_ "InvalidValue" SG_ 654 Wndow_PosRL "7h";
BA_ "GenSigTimeoutTime_ALL" SG_ 654 Window_PosFR 500;
BA_ "InvalidValue" SG_ 654 Window_PosFR "7h";
BA_ "GenSigTimeoutTime_ALL" SG_ 654 Global_close 500;
BA_ "InvalidValue" SG_ 654 Global_close "3h";
BA_ "GenSigTimeoutTime_ALL" SG_ 654 Global_open 500;
BA_ "InvalidValue" SG_ 654 Global_open "3h";
BA_ "GenSigTimeoutTime_ALL" SG_ 654 Window_PosRR 500;
BA_ "InvalidValue" SG_ 654 Window_PosRR "7h";
BA_ "GenSigTimeoutTime_ALL" SG_ 676 ID2 5000;
BA_ "GenSigTimeoutTime_ALL" SG_ 676 ECU_ID_WUPREG 5000;
BA_ "InvalidValue" SG_ 676 ECU_ID_WUPREG "null";
BA_ "GenSigTimeoutTime_ALL" SG_ 676 ID_FN_INQY 5000;
BA_ "InvalidValue" SG_ 676 ID_FN_INQY "null";
BA_ "GenSigTimeoutTime_ALL" SG_ 676 ID_FN_RQ_BUS 5000;
BA_ "InvalidValue" SG_ 676 ID_FN_RQ_BUS "null";
BA_ "GenSigTimeoutTime_ALL" SG_ 676 NO_CC_MESS_EXT 5000;
BA_ "GenSigTimeoutTime_ALL" SG_ 676 NO_CC_MESS_STD 5000;
BA_ "InvalidValue" SG_ 676 NO_CC_MESS_STD "null";
BA_ "GenSigTimeoutTime_ALL" SG_ 676 WACA 5000;
BA_ "InvalidValue" SG_ 676 WACA "null";
BA_ "GenSigTimeoutTime_ALL" SG_ 676 ID_RQ_BUS 5000;
BA_ "GenSigTimeoutTime_ALL" SG_ 676 ST_CC_MESS_EXT 5000;
BA_ "GenSigTimeoutTime_ALL" SG_ 676 ST_CC_MESS_STD 5000;
BA_ "GenSigTimeoutTime_ALL" SG_ 676 TRANF_CC_MESS_EXT 5000;
BA_ "GenSigTimeoutTime_ALL" SG_ 676 TRANF_CC_MESS_STD 5000;
BA_ "GenSigTimeoutTime_ALL" SG_ 676 ST_IDC_CCLK_CC_MESS_EXT 5000;
BA_ "GenSigTimeoutTime_ALL" SG_ 676 ST_IDC_CCLK_CC_MESS_STD 5000;
BA_ "GenSigTimeoutTime_ALL" SG_ 676 NO_FRM_CC_MESS_EXT 5000;
BA_ "GenSigTimeoutTime_ALL" SG_ 676 ST_RQ_BUS 5000;
BA_ "GenSigTimeoutTime_ALL" SG_ 676 QUAN_FRM_CC_MESS_EXT 5000;
BA_ "GenSigTimeoutTime_ALL" SG_ 676 ST_LAW_RQ 5000;
BA_ "GenSigTimeoutTime_ALL" SG_ 676 DUR_FLLUPT 5000;
BA_ "GenSigTimeoutTime_ALL" SG_ 676 UTDT_CC_MESS 5000;
BA_ "GenSigTimeoutTime_ALL" SG_ 714 CHKSM_IC_SENSOR 500;
BA_ "InvalidValue" SG_ 714 CHKSM_IC_SENSOR "null";
BA_ "GenSigTimeoutTime_ALL" SG_ 714 ALV_IC_SENSOR 500;
BA_ "InvalidValue" SG_ 714 ALV_IC_SENSOR "Fh";
BA_ "GenSigStartValue" SG_ 714 MHU_STAT_AmbientTempRaw 80;
BA_ "GenSigTimeoutTime_ALL" SG_ 714 MHU_STAT_AmbientTempRaw 500;
BA_ "InvalidValue" SG_ 714 MHU_STAT_AmbientTempRaw "FFh";
BA_ "GenSigTimeoutTime_ALL" SG_ 714 MHU_STAT_FuelLevel 500;
BA_ "InvalidValue" SG_ 714 MHU_STAT_FuelLevel "FFh";
BA_ "GenSigStartValue" SG_ 714 MHU_STAT_AmbientTemp 80;
BA_ "GenSigTimeoutTime_ALL" SG_ 714 MHU_STAT_AmbientTemp 500;
BA_ "InvalidValue" SG_ 714 MHU_STAT_AmbientTemp "FFh";
BA_ "GenSigTimeoutTime_ALL" SG_ 714 MHU_STAT_CoolantLevelStatus 500;
BA_ "InvalidValue" SG_ 714 MHU_STAT_CoolantLevelStatus "3h";
BA_ "GenSigTimeoutTime_ALL" SG_ 753 MHU_STAT_AirbagWarnLamp 500;
BA_ "InvalidValue" SG_ 753 MHU_STAT_AirbagWarnLamp "3h";
BA_ "GenSigTimeoutTime_ALL" SG_ 760 DISP_HR 5000;
BA_ "InvalidValue" SG_ 760 DISP_HR "FFh";
BA_ "GenSigTimeoutTime_ALL" SG_ 760 DISP_MN 5000;
BA_ "InvalidValue" SG_ 760 DISP_MN "FFh";
BA_ "GenSigTimeoutTime_ALL" SG_ 760 DISP_SEC 5000;
BA_ "InvalidValue" SG_ 760 DISP_SEC "FFh";
BA_ "GenSigStartValue" SG_ 760 DISP_DATE_DAY 1;
BA_ "GenSigTimeoutTime_ALL" SG_ 760 DISP_DATE_DAY 5000;
BA_ "InvalidValue" SG_ 760 DISP_DATE_DAY "FFh";
BA_ "GenSigStartValue" SG_ 760 DISP_DATE_MON 1;
BA_ "GenSigTimeoutTime_ALL" SG_ 760 DISP_DATE_MON 5000;
BA_ "InvalidValue" SG_ 760 DISP_DATE_MON "Fh";
BA_ "GenSigTimeoutTime_ALL" SG_ 760 DISP_DATE_WDAY 5000;
BA_ "InvalidValue" SG_ 760 DISP_DATE_WDAY "Fh";
BA_ "GenSigStartValue" SG_ 760 DISP_DATE_YR 1;
BA_ "GenSigTimeoutTime_ALL" SG_ 760 DISP_DATE_YR 5000;
BA_ "InvalidValue" SG_ 760 DISP_DATE_YR "FFFFh";
BA_ "GenSigTimeoutTime_ALL" SG_ 760 ST_DISP_CTI_DATE 5000;
BA_ "InvalidValue" SG_ 760 ST_DISP_CTI_DATE "Fh";
BA_ "GenSigTimeoutTime_ALL" SG_ 761 DISP_HR_UTC 5000;
BA_ "GenSigTimeoutTime_ALL" SG_ 761 DISP_HR_UTC 5000;
BA_ "GenSigTimeoutTime_ALL" SG_ 761 DISP_HR_UTC 5000;
BA_ "InvalidValue" SG_ 761 DISP_HR_UTC "FFh";
BA_ "GenSigTimeoutTime_ALL" SG_ 761 DISP_MN_UTC 5000;
BA_ "GenSigTimeoutTime_ALL" SG_ 761 DISP_MN_UTC 5000;
BA_ "GenSigTimeoutTime_ALL" SG_ 761 DISP_MN_UTC 5000;
BA_ "InvalidValue" SG_ 761 DISP_MN_UTC "FFh";
BA_ "GenSigTimeoutTime_ALL" SG_ 761 DISP_SEC_UTC 5000;
BA_ "GenSigTimeoutTime_ALL" SG_ 761 DISP_SEC_UTC 5000;
BA_ "GenSigTimeoutTime_ALL" SG_ 761 DISP_SEC_UTC 5000;
BA_ "InvalidValue" SG_ 761 DISP_SEC_UTC "FFh";
BA_ "GenSigStartValue" SG_ 761 DISP_DATE_DAY_UTC 1;
BA_ "GenSigTimeoutTime_ALL" SG_ 761 DISP_DATE_DAY_UTC 5000;
BA_ "GenSigTimeoutTime_ALL" SG_ 761 DISP_DATE_DAY_UTC 5000;
BA_ "GenSigTimeoutTime_ALL" SG_ 761 DISP_DATE_DAY_UTC 5000;
BA_ "InvalidValue" SG_ 761 DISP_DATE_DAY_UTC "FFh";
BA_ "InvalidValue" SG_ 761 DISP_DATE_DAY_UTC "ffh";
BA_ "GenSigStartValue" SG_ 761 DISP_DATE_MON_UTC 1;
BA_ "GenSigTimeoutTime_ALL" SG_ 761 DISP_DATE_MON_UTC 5000;
BA_ "GenSigTimeoutTime_ALL" SG_ 761 DISP_DATE_MON_UTC 5000;
BA_ "GenSigTimeoutTime_ALL" SG_ 761 DISP_DATE_MON_UTC 5000;
BA_ "InvalidValue" SG_ 761 DISP_DATE_MON_UTC "Fh";
BA_ "GenSigStartValue" SG_ 761 DISP_DATE_YR_UTC 1;
BA_ "GenSigTimeoutTime_ALL" SG_ 761 DISP_DATE_YR_UTC 5000;
BA_ "GenSigTimeoutTime_ALL" SG_ 761 DISP_DATE_YR_UTC 5000;
BA_ "InvalidValue" SG_ 761 DISP_DATE_YR_UTC "FFFFh";
BA_ "GenSigSendType" SG_ 768 CCU_STAT_SyncClimateZone 4;
BA_ "InvalidValue" SG_ 768 CCU_STAT_SyncClimateZone "3h";
BA_ "GenSigSendType" SG_ 768 CCU_STAT_Auto 4;
BA_ "InvalidValue" SG_ 768 CCU_STAT_Auto "3h";
BA_ "GenSigSendType" SG_ 768 CCU_STAT_Aircondition 4;
BA_ "InvalidValue" SG_ 768 CCU_STAT_Aircondition "3h";
BA_ "GenSigSendType" SG_ 768 CCU_STAT_IonButton 4;
BA_ "InvalidValue" SG_ 768 CCU_STAT_IonButton "3h";
BA_ "GenSigSendType" SG_ 768 CCU_STAT_MaxAc 4;
BA_ "InvalidValue" SG_ 768 CCU_STAT_MaxAc "3h";
BA_ "GenSigSendType" SG_ 768 CCU_STAT_OnOff 4;
BA_ "GenSigStartValue" SG_ 768 CCU_STAT_OnOff 3;
BA_ "InvalidValue" SG_ 768 CCU_STAT_OnOff "3h";
BA_ "GenSigSendType" SG_ 768 CCU_STAT_FanSpeed 4;
BA_ "InvalidValue" SG_ 768 CCU_STAT_FanSpeed "Fh";
BA_ "GenSigSendType" SG_ 768 CCU_STAT_RecircFlap 4;
BA_ "GenSigStartValue" SG_ 768 CCU_STAT_RecircFlap 1;
BA_ "InvalidValue" SG_ 768 CCU_STAT_RecircFlap "3h";
BA_ "GenSigSendType" SG_ 768 CCU_STAT_FlapPos 4;
BA_ "InvalidValue" SG_ 768 CCU_STAT_FlapPos "Fh";
BA_ "InvalidValue" SG_ 768 CCU_STAT_FlapPos "7h";
BA_ "GenSigSendType" SG_ 768 CCU_STAT_Defrost 4;
BA_ "InvalidValue" SG_ 768 CCU_STAT_Defrost "3h";
BA_ "GenSigSendType" SG_ 768 CCU_STAT_PTC_Heater 4;
BA_ "InvalidValue" SG_ 768 CCU_STAT_PTC_Heater "7h";
BA_ "GenSigSendType" SG_ 768 CCU_STAT_TempDriver 4;
BA_ "GenSigStartValue" SG_ 768 CCU_STAT_TempDriver 40;
BA_ "InvalidValue" SG_ 768 CCU_STAT_TempDriver "FFh";
BA_ "GenSigSendType" SG_ 768 CCU_STAT_TempPassenger 4;
BA_ "GenSigStartValue" SG_ 768 CCU_STAT_TempPassenger 40;
BA_ "InvalidValue" SG_ 768 CCU_STAT_TempPassenger "FFh";
BA_ "GenSigTimeoutTime_ALL" SG_ 769 Checksum_RP 500;
BA_ "GenSigTimeoutTime_ALL" SG_ 769 Rolling_Counter_RP 500;
BA_ "InvalidValue" SG_ 769 Rolling_Counter_RP "Fh";
BA_ "GenSigTimeoutTime_ALL" SG_ 769 RP_ReqInfoDispTxt2 500;
BA_ "GenSigTimeoutTime_ALL" SG_ 769 RP_Status 500;
BA_ "GenSigTimeoutTime_ALL" SG_ 769 ADAS_TboxAuthStatus 500;
BA_ "InvalidValue" SG_ 769 ADAS_TboxAuthStatus "3h";
BA_ "GenSigTimeoutTime_ALL" SG_ 769 RP_ParkOutDircnDisReq 500;
BA_ "GenSigTimeoutTime_ALL" SG_ 769 RP_ParkOutModeDisReq 500;
BA_ "GenSigTimeoutTime_ALL" SG_ 769 RP_ReqInfoDispTxt1 500;
BA_ "GenSigTimeoutTime_ALL" SG_ 769 SM_Startfdbck 500;
BA_ "InvalidValue" SG_ 769 SM_Startfdbck "null";
BA_ "GenSigTimeoutTime_ALL" SG_ 769 SM_Quitfdbck 500;
BA_ "InvalidValue" SG_ 769 SM_Quitfdbck "null";
BA_ "GenSigTimeoutTime_ALL" SG_ 769 SM_Status 500;
BA_ "InvalidValue" SG_ 769 SM_Status "null";
BA_ "GenSigTimeoutTime_ALL" SG_ 770 CHKSM_CCU_TEMP_PRESSURE 5000;
BA_ "InvalidValue" SG_ 770 CHKSM_CCU_TEMP_PRESSURE "null";
BA_ "GenSigTimeoutTime_ALL" SG_ 770 ALV_CCU_TEMP_PRESSURE 5000;
BA_ "InvalidValue" SG_ 770 ALV_CCU_TEMP_PRESSURE "Fh";
BA_ "GenSigTimeoutTime_ALL" SG_ 770 CCU_Pressure_AC 5000;
BA_ "InvalidValue" SG_ 770 CCU_Pressure_AC "3Fh";
BA_ "GenSigStartValue" SG_ 770 CCU_InteriorTemp 80;
BA_ "GenSigTimeoutTime_ALL" SG_ 770 CCU_InteriorTemp 5000;
BA_ "InvalidValue" SG_ 770 CCU_InteriorTemp "FFh";
BA_ "GenSigStartValue" SG_ 770 CCU_TempEx_AC 80;
BA_ "GenSigTimeoutTime_ALL" SG_ 770 CCU_TempEx_AC 5000;
BA_ "InvalidValue" SG_ 770 CCU_TempEx_AC "FFh";
BA_ "GenSigStartValue" SG_ 770 CCU_EvaporatorTemp 80;
BA_ "GenSigTimeoutTime_ALL" SG_ 770 CCU_EvaporatorTemp 5000;
BA_ "InvalidValue" SG_ 770 CCU_EvaporatorTemp "FFh";
BA_ "GenSigTimeoutTime_ALL" SG_ 771 CHKSM_ADAS_DMS_STATUS 2500;
BA_ "GenSigTimeoutTime_ALL" SG_ 771 ALV_ADAS_DMS_STATUS 2500;
BA_ "InvalidValue" SG_ 771 ALV_ADAS_DMS_STATUS "Fh";
BA_ "GenSigTimeoutTime_ALL" SG_ 771 ADAS_DMS_Thief_image_sendrequest 2500;
BA_ "InvalidValue" SG_ 771 ADAS_DMS_Thief_image_sendrequest "3h";
BA_ "GenSigTimeoutTime_ALL" SG_ 771 ADAS_DMS_Status_feed 2500;
BA_ "InvalidValue" SG_ 771 ADAS_DMS_Status_feed "3h";
BA_ "GenSigTimeoutTime_ALL" SG_ 771 ADAS_DMS_Confidence_score 2500;
BA_ "InvalidValue" SG_ 771 ADAS_DMS_Confidence_score "3h";
BA_ "GenSigTimeoutTime_ALL" SG_ 771 ADAS_DMS_Driver_registration 2500;
BA_ "InvalidValue" SG_ 771 ADAS_DMS_Driver_registration "7h";
BA_ "GenSigTimeoutTime_ALL" SG_ 771 SECCAN_ADAS_DMS_STATUS 2500;
BA_ "GenSigTimeoutTime_ALL" SG_ 773 CHSKM_BMS_Insulation 50000;
BA_ "InvalidValue" SG_ 773 CHSKM_BMS_Insulation "null";
BA_ "GenSigTimeoutTime_ALL" SG_ 773 ALV_BMS_Insulation 50000;
BA_ "InvalidValue" SG_ 773 ALV_BMS_Insulation "Fh";
BA_ "GenSigTimeoutTime_ALL" SG_ 773 BMS_VCU_Insulation_Mon_Sts 50000;
BA_ "InvalidValue" SG_ 773 BMS_VCU_Insulation_Mon_Sts "null";
BA_ "GenSigStartValue" SG_ 773 BMS_PackInsuRes 5535;
BA_ "GenSigTimeoutTime_ALL" SG_ 773 BMS_PackInsuRes 50000;
BA_ "InvalidValue" SG_ 773 BMS_PackInsuRes "null";
BA_ "GenSigTimeoutTime_ALL" SG_ 775 CHKSM_CPD_Output_1 5000;
BA_ "InvalidValue" SG_ 775 CHKSM_CPD_Output_1 "null";
BA_ "GenSigTimeoutTime_ALL" SG_ 775 ALV_CPD_Output_1 5000;
BA_ "InvalidValue" SG_ 775 ALV_CPD_Output_1 "Fh";
BA_ "GenSigTimeoutTime_ALL" SG_ 775 OUT_Alert_TO_BCM 5000;
BA_ "InvalidValue" SG_ 775 OUT_Alert_TO_BCM "7h";
BA_ "GenSigTimeoutTime_ALL" SG_ 775 CPD_State_information 5000;
BA_ "InvalidValue" SG_ 775 CPD_State_information "null";
BA_ "GenSigTimeoutTime_ALL" SG_ 775 OUT_Alert_TO_MHU 5000;
BA_ "GenSigSendType" SG_ 776 MHU_CPD_Setting 2;
BA_ "GenSigSendType" SG_ 776 MHU_CPD_Confirmation_On_HMI 2;
BA_ "GenSigSendType" SG_ 777 ADAS_Immo_MHU_Byte_0 1;
BA_ "GenSigSendType" SG_ 777 ADAS_Immo_MHU_Byte_1 1;
BA_ "GenSigSendType" SG_ 777 ADAS_Immo_MHU_Byte_2 1;
BA_ "GenSigSendType" SG_ 777 ADAS_Immo_MHU_Byte_3 1;
BA_ "GenSigSendType" SG_ 777 ADAS_Immo_MHU_Byte_4 1;
BA_ "GenSigSendType" SG_ 777 ADAS_Immo_MHU_Byte_5 1;
BA_ "GenSigSendType" SG_ 777 ADAS_Immo_MHU_Byte_6 1;
BA_ "GenSigSendType" SG_ 777 ADAS_Immo_MHU_Byte_7 1;
BA_ "GenSigSendType" SG_ 784 CCUR_STAT_IonButton 4;
BA_ "InvalidValue" SG_ 784 CCUR_STAT_IonButton "3h";
BA_ "GenSigSendType" SG_ 784 CCUR_STAT_Defrost 4;
BA_ "InvalidValue" SG_ 784 CCUR_STAT_Defrost "3h";
BA_ "GenSigSendType" SG_ 784 CCUR_STAT_Auto 4;
BA_ "InvalidValue" SG_ 784 CCUR_STAT_Auto "3h";
BA_ "GenSigSendType" SG_ 784 CCUR_STAT_Aircondition 4;
BA_ "InvalidValue" SG_ 784 CCUR_STAT_Aircondition "3h";
BA_ "GenSigSendType" SG_ 784 CCUR_STAT_FlapPos 4;
BA_ "InvalidValue" SG_ 784 CCUR_STAT_FlapPos "7h";
BA_ "GenSigSendType" SG_ 784 CCUR_STAT_FanSpeed 4;
BA_ "InvalidValue" SG_ 784 CCUR_STAT_FanSpeed "Fh";
BA_ "GenSigSendType" SG_ 784 CCUR_STAT_PTC_Heater 4;
BA_ "InvalidValue" SG_ 784 CCUR_STAT_PTC_Heater "7h";
BA_ "GenSigSendType" SG_ 784 CCUR_STAT_OnOff 4;
BA_ "GenSigStartValue" SG_ 784 CCUR_STAT_OnOff 3;
BA_ "InvalidValue" SG_ 784 CCUR_STAT_OnOff "3h";
BA_ "GenSigSendType" SG_ 784 CCUR_STAT_MaxAc 4;
BA_ "InvalidValue" SG_ 784 CCUR_STAT_MaxAc "3h";
BA_ "GenSigSendType" SG_ 784 CCUR_STAT_SyncClimateZone 4;
BA_ "InvalidValue" SG_ 784 CCUR_STAT_SyncClimateZone "3h";
BA_ "GenSigSendType" SG_ 784 CCUR_STAT_RecircFlap 4;
BA_ "GenSigStartValue" SG_ 784 CCUR_STAT_RecircFlap 1;
BA_ "InvalidValue" SG_ 784 CCUR_STAT_RecircFlap "3h";
BA_ "GenSigSendType" SG_ 784 CCUR_STAT_TempRear 4;
BA_ "GenSigStartValue" SG_ 784 CCUR_STAT_TempRear 40;
BA_ "InvalidValue" SG_ 784 CCUR_STAT_TempRear "null";
BA_ "InvalidValue" SG_ 784 CCUR_STAT_TempRear "null";
BA_ "GenSigTimeoutTime_ALL" SG_ 787 CHSKM_POD_StatusCharger1 500;
BA_ "InvalidValue" SG_ 787 CHSKM_POD_StatusCharger1 "null";
BA_ "GenSigTimeoutTime_ALL" SG_ 787 ALV_POD_StatusCharger1 500;
BA_ "InvalidValue" SG_ 787 ALV_POD_StatusCharger1 "Fh";
BA_ "GenSigTimeoutTime_ALL" SG_ 787 POD_statusOBC 500;
BA_ "InvalidValue" SG_ 787 POD_statusOBC "null";
BA_ "GenSigTimeoutTime_ALL" SG_ 787 POD_OBC_Max_Current_Out 500;
BA_ "InvalidValue" SG_ 787 POD_OBC_Max_Current_Out "null";
BA_ "GenSigTimeoutTime_ALL" SG_ 787 POD_iDCOut 500;
BA_ "InvalidValue" SG_ 787 POD_iDCOut "FFh";
BA_ "GenSigTimeoutTime_ALL" SG_ 787 POD_vDCOut 500;
BA_ "InvalidValue" SG_ 787 POD_vDCOut "FFFFh";
BA_ "GenSigTimeoutTime_ALL" SG_ 803 CHSKM_POD_StatusCharger2 500;
BA_ "InvalidValue" SG_ 803 CHSKM_POD_StatusCharger2 "null";
BA_ "GenSigTimeoutTime_ALL" SG_ 803 ALV_POD_StatusCharger2 500;
BA_ "InvalidValue" SG_ 803 ALV_POD_StatusCharger2 "Fh";
BA_ "GenSigStartValue" SG_ 803 POD_phaseACInput 1;
BA_ "GenSigTimeoutTime_ALL" SG_ 803 POD_phaseACInput 500;
BA_ "InvalidValue" SG_ 803 POD_phaseACInput "0";
BA_ "GenSigTimeoutTime_ALL" SG_ 803 POD_iACInput 500;
BA_ "InvalidValue" SG_ 803 POD_iACInput "null";
BA_ "GenSigTimeoutTime_ALL" SG_ 803 POD_vACInput 500;
BA_ "InvalidValue" SG_ 803 POD_vACInput "null";
BA_ "GenSigTimeoutTime_ALL" SG_ 804 Steering_HeatingControl 500;
BA_ "InvalidValue" SG_ 804 Steering_HeatingControl "3h";
BA_ "GenSigTimeoutTime_ALL" SG_ 805 Steering_HeatingControlFdbk 500;
BA_ "InvalidValue" SG_ 805 Steering_HeatingControlFdbk "3h";
BA_ "GenSigTimeoutTime_ALL" SG_ 806 CHSKM_POD_StatusDCDC1 500;
BA_ "InvalidValue" SG_ 806 CHSKM_POD_StatusDCDC1 "null";
BA_ "GenSigTimeoutTime_ALL" SG_ 806 ALV_POD_StatusDCDC1 500;
BA_ "InvalidValue" SG_ 806 ALV_POD_StatusDCDC1 "Fh";
BA_ "GenSigTimeoutTime_ALL" SG_ 806 POD_statusDCDC 500;
BA_ "InvalidValue" SG_ 806 POD_statusDCDC "7h";
BA_ "GenSigTimeoutTime_ALL" SG_ 806 POD_DCDC_Max_Current_Out 500;
BA_ "InvalidValue" SG_ 806 POD_DCDC_Max_Current_Out "FFh";
BA_ "GenSigTimeoutTime_ALL" SG_ 807 CHKSM_POD_StatusFC 500;
BA_ "InvalidValue" SG_ 807 CHKSM_POD_StatusFC "";
BA_ "GenSigTimeoutTime_ALL" SG_ 807 ALV_POD_StatusFC 500;
BA_ "InvalidValue" SG_ 807 ALV_POD_StatusFC "Fh";
BA_ "GenSigTimeoutTime_ALL" SG_ 807 POD_vFC 500;
BA_ "InvalidValue" SG_ 807 POD_vFC "FFFFh";
BA_ "GenSigTimeoutTime_ALL" SG_ 807 POD_statusFCContactors 500;
BA_ "InvalidValue" SG_ 807 POD_statusFCContactors "7h";
BA_ "GenSigTimeoutTime_ALL" SG_ 808 T_SEC_COU_REL 5000;
BA_ "InvalidValue" SG_ 808 T_SEC_COU_REL "FFFFFFFFh";
BA_ "GenSigTimeoutTime_ALL" SG_ 808 T_DAY_COU_ABSL 5000;
BA_ "InvalidValue" SG_ 808 T_DAY_COU_ABSL "FFFFh";
BA_ "GenSigTimeoutTime_ALL" SG_ 809 CRC_BCM_ODO 5000;
BA_ "InvalidValue" SG_ 809 CRC_BCM_ODO "null";
BA_ "GenSigTimeoutTime_ALL" SG_ 809 ALIV_BCM_ODO 5000;
BA_ "InvalidValue" SG_ 809 ALIV_BCM_ODO "Fh";
BA_ "GenSigTimeoutTime_ALL" SG_ 809 Odometer_BCM 5000;
BA_ "InvalidValue" SG_ 809 Odometer_BCM "FFFFFh";
BA_ "GenSigTimeoutTime_ALL" SG_ 809 SECCAN_BCM_ODO 5000;
BA_ "GenSigTimeoutTime_ALL" SG_ 809 SECCAN_BCM_ODO 5000;
BA_ "InvalidValue" SG_ 809 SECCAN_BCM_ODO "null";
BA_ "GenSigTimeoutTime_ALL" SG_ 816 MILE_KM 500;
BA_ "InvalidValue" SG_ 816 MILE_KM "FFFFFFh";
BA_ "GenSigTimeoutTime_ALL" SG_ 816 FLLV_FUTA 500;
BA_ "InvalidValue" SG_ 816 FLLV_FUTA "FFh";
BA_ "GenSigTimeoutTime_ALL" SG_ 816 RNG 500;
BA_ "InvalidValue" SG_ 816 RNG "FFFh";
BA_ "GenSigTimeoutTime_ALL" SG_ 816 ST_FLLV_FUTA_SPAR 500;
BA_ "InvalidValue" SG_ 816 ST_FLLV_FUTA_SPAR "3h";
BA_ "GenSigTimeoutTime_ALL" SG_ 818 Checksum_0x332 500;
BA_ "InvalidValue" SG_ 818 Checksum_0x332 "null";
BA_ "GenSigTimeoutTime_ALL" SG_ 818 Rolling_Counter_0x332 500;
BA_ "InvalidValue" SG_ 818 Rolling_Counter_0x332 "Fh";
BA_ "GenSigTimeoutTime_ALL" SG_ 818 BMS_PackCNom 500;
BA_ "InvalidValue" SG_ 818 BMS_PackCNom "FFFFh";
BA_ "GenSigStartValue" SG_ 818 BMS_PackTemp_0x332 80;
BA_ "GenSigTimeoutTime_ALL" SG_ 818 BMS_PackTemp_0x332 500;
BA_ "InvalidValue" SG_ 818 BMS_PackTemp_0x332 "FFh";
BA_ "GenSigTimeoutTime_ALL" SG_ 827 CHKSM_CameraLane 500;
BA_ "GenSigTimeoutTime_ALL" SG_ 827 ALV_ADAS_Cameralane 500;
BA_ "InvalidValue" SG_ 827 ALV_ADAS_Cameralane "Fh";
BA_ "GenSigTimeoutTime_ALL" SG_ 827 Camera_R1_Line_Type 500;
BA_ "GenSigTimeoutTime_ALL" SG_ 827 Camera_L1_Line_Type 500;
BA_ "InvalidValue" SG_ 827 Camera_L1_Line_Type "3h";
BA_ "GenSigTimeoutTime_ALL" SG_ 827 R0_ExistProbability 500;
BA_ "InvalidValue" SG_ 827 R0_ExistProbability "Fh";
BA_ "GenSigTimeoutTime_ALL" SG_ 827 L0_ExistProbability 500;
BA_ "InvalidValue" SG_ 827 L0_ExistProbability "Fh";
BA_ "GenSigTimeoutTime_ALL" SG_ 827 L1_ExistProbability 500;
BA_ "InvalidValue" SG_ 827 L1_ExistProbability "Fh";
BA_ "GenSigTimeoutTime_ALL" SG_ 827 R1_ExistProbability 500;
BA_ "InvalidValue" SG_ 827 R1_ExistProbability "Fh";
BA_ "GenSigTimeoutTime_ALL" SG_ 827 SECCAN_CameraLane 500;
BA_ "GenSigTimeoutTime_ALL" SG_ 833 SECCAN_Cam_OBJ_1 500;
BA_ "GenSigTimeoutTime_ALL" SG_ 833 ADAS_OBJ01_Class 500;
BA_ "InvalidValue" SG_ 833 ADAS_OBJ01_Class "7";
BA_ "GenSigStartValue" SG_ 833 ADAS_OBJ01_LgtDis 400;
BA_ "GenSigTimeoutTime_ALL" SG_ 833 ADAS_OBJ01_LgtDis 500;
BA_ "InvalidValue" SG_ 833 ADAS_OBJ01_LgtDis "3FFF";
BA_ "GenSigTimeoutTime_ALL" SG_ 833 ADAS_OBJ01_ID 500;
BA_ "InvalidValue" SG_ 833 ADAS_OBJ01_ID "FF";
BA_ "GenSigTimeoutTime_ALL" SG_ 833 ADAS_OBJ01_LatDis 500;
BA_ "GenSigTimeoutTime_ALL" SG_ 833 ADAS_OBJ01_Lane 500;
BA_ "InvalidValue" SG_ 833 ADAS_OBJ01_Lane "7";
BA_ "GenSigTimeoutTime_ALL" SG_ 835 SECCAN_Cam_OBJ_2 500;
BA_ "GenSigTimeoutTime_ALL" SG_ 835 ADAS_OBJ02_Class 500;
BA_ "InvalidValue" SG_ 835 ADAS_OBJ02_Class "7";
BA_ "GenSigStartValue" SG_ 835 ADAS_OBJ02_LgtDis 400;
BA_ "GenSigTimeoutTime_ALL" SG_ 835 ADAS_OBJ02_LgtDis 500;
BA_ "InvalidValue" SG_ 835 ADAS_OBJ02_LgtDis "3FF";
BA_ "GenSigTimeoutTime_ALL" SG_ 835 ADAS_OBJ02_ID 500;
BA_ "InvalidValue" SG_ 835 ADAS_OBJ02_ID "FF";
BA_ "GenSigTimeoutTime_ALL" SG_ 835 ADAS_OBJ02_LatDis 500;
BA_ "InvalidValue" SG_ 835 ADAS_OBJ02_LatDis "3FF";
BA_ "GenSigTimeoutTime_ALL" SG_ 835 ADAS_OBJ02_Lane 500;
BA_ "InvalidValue" SG_ 835 ADAS_OBJ02_Lane "7";
BA_ "GenSigTimeoutTime_ALL" SG_ 838 CHSKM_POD_StatusDCDC2 500;
BA_ "InvalidValue" SG_ 838 CHSKM_POD_StatusDCDC2 "null";
BA_ "GenSigTimeoutTime_ALL" SG_ 838 ALV_POD_StatusDCDC2 500;
BA_ "InvalidValue" SG_ 838 ALV_POD_StatusDCDC2 "Fh";
BA_ "GenSigTimeoutTime_ALL" SG_ 838 POD_vDCInput 500;
BA_ "InvalidValue" SG_ 838 POD_vDCInput "FFFFh";
BA_ "GenSigTimeoutTime_ALL" SG_ 838 POD_iDCDCOutput 500;
BA_ "InvalidValue" SG_ 838 POD_iDCDCOutput "FFFFh";
BA_ "GenSigTimeoutTime_ALL" SG_ 838 POD_vDCDCOutput 500;
BA_ "InvalidValue" SG_ 838 POD_vDCDCOutput "FFFFh";
BA_ "GenSigTimeoutTime_ALL" SG_ 840 EDS_HVIL_STS_FWD 5000;
BA_ "InvalidValue" SG_ 840 EDS_HVIL_STS_FWD "";
BA_ "GenSigTimeoutTime_ALL" SG_ 841 EDS_HVIL_STS_RWD 5000;
BA_ "InvalidValue" SG_ 841 EDS_HVIL_STS_RWD "";
BA_ "GenSigTimeoutTime_ALL" SG_ 842 SECCAN_Cam_OBJ_3 500;
BA_ "GenSigTimeoutTime_ALL" SG_ 842 ADAS_OBJ03_Class 500;
BA_ "InvalidValue" SG_ 842 ADAS_OBJ03_Class "7";
BA_ "GenSigStartValue" SG_ 842 ADAS_OBJ03_LgtDis 400;
BA_ "GenSigTimeoutTime_ALL" SG_ 842 ADAS_OBJ03_LgtDis 500;
BA_ "InvalidValue" SG_ 842 ADAS_OBJ03_LgtDis "3FF";
BA_ "GenSigTimeoutTime_ALL" SG_ 842 ADAS_OBJ03_ID 500;
BA_ "InvalidValue" SG_ 842 ADAS_OBJ03_ID "FF";
BA_ "GenSigTimeoutTime_ALL" SG_ 842 ADAS_OBJ03_LatDis 500;
BA_ "InvalidValue" SG_ 842 ADAS_OBJ03_LatDis "3FF";
BA_ "GenSigTimeoutTime_ALL" SG_ 842 ADAS_OBJ03_Lane 500;
BA_ "InvalidValue" SG_ 842 ADAS_OBJ03_Lane "7";
BA_ "GenSigTimeoutTime_ALL" SG_ 844 SECCAN_Cam_OBJ_4 500;
BA_ "GenSigTimeoutTime_ALL" SG_ 844 ADAS_OBJ04_Class 500;
BA_ "InvalidValue" SG_ 844 ADAS_OBJ04_Class "7";
BA_ "GenSigStartValue" SG_ 844 ADAS_OBJ04_LgtDis 400;
BA_ "GenSigTimeoutTime_ALL" SG_ 844 ADAS_OBJ04_LgtDis 500;
BA_ "InvalidValue" SG_ 844 ADAS_OBJ04_LgtDis "3FFF";
BA_ "GenSigTimeoutTime_ALL" SG_ 844 ADAS_OBJ04_ID 500;
BA_ "InvalidValue" SG_ 844 ADAS_OBJ04_ID "FF";
BA_ "GenSigTimeoutTime_ALL" SG_ 844 ADAS_OBJ04_LatDis 500;
BA_ "GenSigTimeoutTime_ALL" SG_ 844 ADAS_OBJ04_Lane 500;
BA_ "InvalidValue" SG_ 844 ADAS_OBJ04_Lane "7";
BA_ "GenSigTimeoutTime_ALL" SG_ 845 SECCAN_Cam_OBJ_5 500;
BA_ "GenSigTimeoutTime_ALL" SG_ 845 ADAS_OBJ05_Class 500;
BA_ "InvalidValue" SG_ 845 ADAS_OBJ05_Class "7";
BA_ "GenSigStartValue" SG_ 845 ADAS_OBJ05_LgtDis 400;
BA_ "GenSigTimeoutTime_ALL" SG_ 845 ADAS_OBJ05_LgtDis 500;
BA_ "InvalidValue" SG_ 845 ADAS_OBJ05_LgtDis "3FFF";
BA_ "GenSigTimeoutTime_ALL" SG_ 845 ADAS_OBJ05_ID 500;
BA_ "InvalidValue" SG_ 845 ADAS_OBJ05_ID "FF";
BA_ "GenSigTimeoutTime_ALL" SG_ 845 ADAS_OBJ05_LatDis 500;
BA_ "GenSigTimeoutTime_ALL" SG_ 845 ADAS_OBJ05_Lane 500;
BA_ "InvalidValue" SG_ 845 ADAS_OBJ05_Lane "7";
BA_ "GenSigTimeoutTime_ALL" SG_ 846 SECCAN_Cam_OBJ_6 500;
BA_ "GenSigTimeoutTime_ALL" SG_ 846 ADAS_OBJ06_Class 500;
BA_ "InvalidValue" SG_ 846 ADAS_OBJ06_Class "7";
BA_ "GenSigStartValue" SG_ 846 ADAS_OBJ06_LgtDis 400;
BA_ "GenSigTimeoutTime_ALL" SG_ 846 ADAS_OBJ06_LgtDis 500;
BA_ "InvalidValue" SG_ 846 ADAS_OBJ06_LgtDis "3FFF";
BA_ "GenSigTimeoutTime_ALL" SG_ 846 ADAS_OBJ06_ID 500;
BA_ "InvalidValue" SG_ 846 ADAS_OBJ06_ID "FF";
BA_ "GenSigTimeoutTime_ALL" SG_ 846 ADAS_OBJ06_LatDis 500;
BA_ "GenSigTimeoutTime_ALL" SG_ 846 ADAS_OBJ06_Lane 500;
BA_ "InvalidValue" SG_ 846 ADAS_OBJ06_Lane "7";
BA_ "GenSigTimeoutTime_ALL" SG_ 849 CHKSM_ADAS_PA 500;
BA_ "GenSigTimeoutTime_ALL" SG_ 849 ALV_ADAS_PA 500;
BA_ "InvalidValue" SG_ 849 ALV_ADAS_PA "Fh";
BA_ "GenSigStartValue" SG_ 849 ADAS_PA_AutoOn_Feed 1;
BA_ "GenSigTimeoutTime_ALL" SG_ 849 ADAS_PA_AutoOn_Feed 500;
BA_ "GenSigTimeoutTime_ALL" SG_ 849 ADAS_PA_AlertFRI 500;
BA_ "GenSigTimeoutTime_ALL" SG_ 849 ADAS_PA_AlertFLI 500;
BA_ "GenSigTimeoutTime_ALL" SG_ 849 ADAS_PA_AlertFLO 500;
BA_ "GenSigTimeoutTime_ALL" SG_ 849 ADAS_PA_AlertRLO 500;
BA_ "GenSigTimeoutTime_ALL" SG_ 849 ADAS_PA_AlertRLI 500;
BA_ "GenSigTimeoutTime_ALL" SG_ 849 ADAS_PA_AlertFRO 500;
BA_ "GenSigTimeoutTime_ALL" SG_ 849 ADAS_PA_AlertRRO 500;
BA_ "GenSigTimeoutTime_ALL" SG_ 849 ADAS_PA_AlertRRI 500;
BA_ "GenSigTimeoutTime_ALL" SG_ 849 ADAS_PA_state 500;
BA_ "GenSigTimeoutTime_ALL" SG_ 850 CHKSM_ADAS_AHB_DOW 500;
BA_ "GenSigTimeoutTime_ALL" SG_ 850 ALV_ADAS_AHB_DOW 500;
BA_ "InvalidValue" SG_ 850 ALV_ADAS_AHB_DOW "Fh";
BA_ "GenSigTimeoutTime_ALL" SG_ 850 ADAS_AHB_sens_Feed 500;
BA_ "InvalidValue" SG_ 850 ADAS_AHB_sens_Feed "3h";
BA_ "GenSigTimeoutTime_ALL" SG_ 850 ADAS_AHB_Mode_Feed 500;
BA_ "GenSigTimeoutTime_ALL" SG_ 850 ADAS_AHB_check 500;
BA_ "InvalidValue" SG_ 850 ADAS_AHB_check "3h";
BA_ "GenSigTimeoutTime_ALL" SG_ 850 ADAS_AHB_state 500;
BA_ "InvalidValue" SG_ 850 ADAS_AHB_state "3h";
BA_ "GenSigTimeoutTime_ALL" SG_ 850 ADAS_DOW_WarnRight 500;
BA_ "InvalidValue" SG_ 850 ADAS_DOW_WarnRight "3h";
BA_ "GenSigTimeoutTime_ALL" SG_ 850 ADAS_DOW_SndWarn 500;
BA_ "InvalidValue" SG_ 850 ADAS_DOW_SndWarn "3h";
BA_ "GenSigTimeoutTime_ALL" SG_ 850 ADAS_DOW_state 500;
BA_ "InvalidValue" SG_ 850 ADAS_DOW_state "3h";
BA_ "GenSigTimeoutTime_ALL" SG_ 850 ADAS_DOW_check 500;
BA_ "InvalidValue" SG_ 850 ADAS_DOW_check "3h";
BA_ "GenSigTimeoutTime_ALL" SG_ 850 ADAS_DOW_WarnLeft 500;
BA_ "InvalidValue" SG_ 850 ADAS_DOW_WarnLeft "3h";
BA_ "GenSigStartValue" SG_ 850 ADAS_DOW_Mode_Feed 2;
BA_ "GenSigTimeoutTime_ALL" SG_ 850 ADAS_DOW_Mode_Feed 500;
BA_ "InvalidValue" SG_ 850 ADAS_DOW_Mode_Feed "3h";
BA_ "GenSigTimeoutTime_ALL" SG_ 850 ADAS_AHB_RBPos 500;
BA_ "InvalidValue" SG_ 850 ADAS_AHB_RBPos "7h";
BA_ "GenSigTimeoutTime_ALL" SG_ 850 ADAS_AHB_LBPos 500;
BA_ "InvalidValue" SG_ 850 ADAS_AHB_LBPos "7h";
BA_ "GenSigTimeoutTime_ALL" SG_ 851 CHKSM_ADAS_ACC 500;
BA_ "GenSigTimeoutTime_ALL" SG_ 851 ALV_ADAS_ACC 500;
BA_ "InvalidValue" SG_ 851 ALV_ADAS_ACC "Fh";
BA_ "GenSigTimeoutTime_ALL" SG_ 851 ADAS_ACC_ObjDetec 500;
BA_ "GenSigTimeoutTime_ALL" SG_ 851 ADAS_ISA_check 500;
BA_ "InvalidValue" SG_ 851 ADAS_ISA_check "3h";
BA_ "GenSigTimeoutTime_ALL" SG_ 851 ADAS_ISA_Mode_SW_Feed 500;
BA_ "GenSigTimeoutTime_ALL" SG_ 851 ADAS_TagSpeed_ICON_Feed 500;
BA_ "InvalidValue" SG_ 851 ADAS_TagSpeed_ICON_Feed "7h";
BA_ "GenSigTimeoutTime_ALL" SG_ 851 ADAS_ISA_PopUp_Feed 500;
BA_ "InvalidValue" SG_ 851 ADAS_ISA_PopUp_Feed "Fh";
BA_ "GenSigTimeoutTime_ALL" SG_ 851 ADAS_ISA_Btn_Feed 500;
BA_ "GenSigTimeoutTime_ALL" SG_ 851 ADAS_ACC_DistSet_upper_Feed 500;
BA_ "GenSigTimeoutTime_ALL" SG_ 851 ADAS_ACC_TimeGapSet 500;
BA_ "InvalidValue" SG_ 851 ADAS_ACC_TimeGapSet "7h";
BA_ "GenSigTimeoutTime_ALL" SG_ 851 ADAS_ACC_State 500;
BA_ "GenSigTimeoutTime_ALL" SG_ 851 ADAS_ACC_TagSpeed 500;
BA_ "InvalidValue" SG_ 851 ADAS_ACC_TagSpeed "FFh";
BA_ "GenSigTimeoutTime_ALL" SG_ 851 ADAS_ACC_PopUp_Feed 500;
BA_ "InvalidValue" SG_ 851 ADAS_ACC_PopUp_Feed "Fh";
BA_ "GenSigTimeoutTime_ALL" SG_ 851 ADAS_ACC_check 500;
BA_ "InvalidValue" SG_ 851 ADAS_ACC_check "3h";
BA_ "GenSigTimeoutTime_ALL" SG_ 851 ADAS_ISA_ICON_Feed 500;
BA_ "GenSigTimeoutTime_ALL" SG_ 851 ADAS_ACC_DistSet_lower_Feed 500;
BA_ "GenSigTimeoutTime_ALL" SG_ 851 ADAS_ACC_SpdSet_upper_Feed 500;
BA_ "GenSigTimeoutTime_ALL" SG_ 851 ADAS_ACC_SpdSet_lower_Feed 500;
BA_ "GenSigTimeoutTime_ALL" SG_ 851 ADAS_ACC_On_Feed 500;
BA_ "GenSigTimeoutTime_ALL" SG_ 851 ADAS_ACC_Set_Feed 500;
BA_ "GenSigTimeoutTime_ALL" SG_ 851 ADAS_ACC_CnlBtn_Feed 500;
BA_ "GenSigTimeoutTime_ALL" SG_ 851 ADAS_ACC_Res_Feed 500;
BA_ "GenSigTimeoutTime_ALL" SG_ 851 ADAS_ACC_ICON_Feed 500;
BA_ "InvalidValue" SG_ 851 ADAS_ACC_ICON_Feed "7h";
BA_ "GenSigTimeoutTime_ALL" SG_ 851 ADAS_ISA_Status 500;
BA_ "InvalidValue" SG_ 851 ADAS_ISA_Status "7h";
VAL_ 389 VCU_FS_C_1 0 "normal" 1 "error" ;
VAL_ 389 VCU_FS_C_2 0 "normal" 1 "error" ;
VAL_ 389 VCU_FS_C_3 0 "normal" 1 "error" ;
VAL_ 389 VCU_FS_C_4 0 "normal" 1 "error" ;
VAL_ 389 VCU_FS_C_5 0 "normal" 1 "error" ;
VAL_ 389 VCU_FS_C_6 0 "normal" 1 "error" ;
VAL_ 389 VCU_FS_C_7 0 "normal" 1 "error" ;
VAL_ 389 VCU_FS_C_8 0 "normal" 1 "error" ;
VAL_ 389 VCU_FS_C_9 0 "normal" 1 "error" ;
VAL_ 389 VCU_FS_C_10 0 "normal" 1 "error" ;
VAL_ 389 VCU_FS_C_11 0 "normal" 1 "error" ;
VAL_ 389 VCU_FS_C_12 0 "normal" 1 "error" ;
VAL_ 389 VCU_FS_C_13 0 "normal" 1 "error" ;
VAL_ 389 VCU_FS_C_14 0 "normal" 1 "error" ;
VAL_ 389 VCU_FS_C_15 0 "normal" 1 "error" ;
VAL_ 389 VCU_FS_C_16 0 "normal" 1 "error" ;
VAL_ 389 VCU_FS_C_17 0 "normal" 1 "error" ;
VAL_ 389 VCU_FS_C_18 0 "normal" 1 "error" ;
VAL_ 389 VCU_FS_C_19 0 "normal" 1 "error" ;
VAL_ 389 VCU_FS_C_20 0 "normal" 1 "error" ;
VAL_ 389 VCU_FS_C_21 0 "normal" 1 "error" ;
VAL_ 389 VCU_FS_C_22 0 "normal" 1 "error" ;
VAL_ 389 VCU_FS_C_23 0 "normal" 1 "error" ;
VAL_ 389 VCU_FS_C_24 0 "normal" 1 "error" ;
VAL_ 389 VCU_FS_C_25 0 "normal" 1 "error" ;
VAL_ 389 VCU_FS_C_26 0 "normal" 1 "error" ;
VAL_ 389 VCU_FS_C_27 0 "normal" 1 "error" ;
VAL_ 389 VCU_FS_C_28 0 "normal" 1 "error" ;
VAL_ 389 VCU_FS_C_29 0 "normal" 1 "error" ;
VAL_ 389 VCU_FS_C_30 0 "normal" 1 "error" ;
VAL_ 389 VCU_FS_C_31 0 "normal" 1 "error" ;
VAL_ 389 VCU_FS_C_32 0 "normal" 1 "error" ;
VAL_ 389 VCU_FS_C_33 0 "normal" 1 "error" ;
VAL_ 389 VCU_FS_C_34 0 "normal" 1 "error" ;
VAL_ 389 VCU_FS_C_35 0 "normal" 1 "error" ;
VAL_ 389 VCU_FS_C_36 0 "normal" 1 "error" ;
VAL_ 389 VCU_FS_C_37 0 "normal" 1 "error" ;
VAL_ 389 VCU_FS_C_38 0 "normal" 1 "error" ;
VAL_ 389 VCU_FS_C_39 0 "normal" 1 "error" ;
VAL_ 389 VCU_FS_C_40 0 "normal" 1 "error" ;
VAL_ 389 VCU_FS_C_41 0 "normal" 1 "error" ;
VAL_ 389 VCU_FS_C_42 0 "normal" 1 "error" ;
VAL_ 389 VCU_FS_C_43 0 "normal" 1 "error" ;
VAL_ 389 VCU_FS_C_44 0 "normal" 1 "error" ;
VAL_ 389 VCU_FS_C_45 0 "normal" 1 "error" ;
VAL_ 389 VCU_FS_C_46 0 "normal" 1 "error" ;
VAL_ 389 VCU_FS_C_47 0 "normal" 1 "error" ;
VAL_ 389 VCU_FS_C_48 0 "normal" 1 "error" ;
VAL_ 389 VCU_FS_C_49 0 "normal" 1 "error" ;
VAL_ 389 VCU_FS_C_50 0 "normal" 1 "error" ;
VAL_ 389 VCU_FS_C_51 0 "normal" 1 "error" ;
VAL_ 389 VCU_FS_C_52 0 "normal" 1 "error" ;
VAL_ 389 VCU_FS_C_53 0 "normal" 1 "error" ;
VAL_ 389 VCU_FS_C_54 0 "normal" 1 "error" ;
VAL_ 389 VCU_FS_C_55 0 "normal" 1 "error" ;
VAL_ 389 VCU_FS_C_56 0 "normal" 1 "error" ;
VAL_ 389 VCU_FS_C_57 0 "normal" 1 "error" ;
VAL_ 389 VCU_FS_C_58 0 "normal" 1 "error" ;
VAL_ 389 VCU_FS_C_59 0 "normal" 1 "error" ;
VAL_ 389 VCU_FS_C_60 0 "normal" 1 "error" ;
VAL_ 389 VCU_FS_C_61 0 "normal" 1 "error" ;
VAL_ 389 VCU_FS_C_62 0 "normal" 1 "error" ;
VAL_ 389 VCU_FS_C_63 0 "normal" 1 "error" ;
VAL_ 389 VCU_FS_C_64 0 "normal" 1 "error" ;
VAL_ 409 VCU_BMS_HVOnOff_REQ 0 "forbid" 1 "allow";
VAL_ 417 DVCO_VEH 0 "Vehicle is stationary" 1 "Vehicle is moving forward" 2 "Vehicle is reversing" 3 "Vehicle is moving " 4 "Vehicle is stationary rear axle rol" 5 "Vehicle is stationary all axle roll" 6 "Vehicle is stationary Front axle roll" 7 "Signal invalid";
VAL_ 417 QU_V_VEH_COG 1 "Signal value is valid and secured and plausible" 2 "Reserved" 3 "Reserved" 4 "Reserved" 6 "Reserved" 7 "Reserved" 8 "Init" 9 "Reserved" 10 "Signal value is valid" 11 "Signal quality or monitoring limited" 12 "Reserved" 14 "Signal value is invalid" 15 "Signal invalid";
VAL_ 504 EDS_Work_STS_FR 0 "default" 1 "init" 2 "standby" 3 "precharge" 4 "normal" 5 "HVReady" 6 "6SO" 11 "shut down" 12 "after run" 13 "Failure" 14 "power off" 15 "invaild";
VAL_ 504 EDS_output_trqValid_FR 0 "invalid" 1 "valid";
VAL_ 504 EDS_MotorDriveSts_FR 0 "Zero control" 1 "Drive control" 2 "regen control" 3 "Invaild";
VAL_ 504 EDS_powoff_req_FR 0 "(No request)" 1 "(Request high voltage power down)";
VAL_ 504 EDS_SpdValid_FR 0 "invalid" 1 "valid";
VAL_ 504 EDS_VCU_6SO_flag_FWD 0 "OFF" 1 "ON";
VAL_ 505 EDS_Work_STS_RR 0 "default" 1 "init" 2 "standby" 3 "precharge" 4 "normal" 5 "HVReady" 6 "6SO" 11 "shut down" 12 "after run" 13 "Failure" 14 "power off" 15 "invaild";
VAL_ 505 EDS_output_trqValid_RR 0 "invalid" 1 "valid";
VAL_ 505 EDS_MotorDriveSts_RR 0 "Zero control" 1 "Drive control" 2 "regen control" 3 "Invaild";
VAL_ 505 EDS_powoff_req_RR 0 "(No request)" 1 "(Request high voltage power down)";
VAL_ 505 EDS_SpdValid_RR 0 "invalid" 1 "valid";
VAL_ 505 EDS_VCU_6SO_flag_RWD 0 "OFF" 1 "ON";
VAL_ 506 MHU_TouchEvtTyp 0 "One finger single click" 1 "One finger double click" 2 "One finger long press" 3 "One finger moving" 4 "Rotate";
VAL_ 515 R1_LINE_TYPE 0 "No display" 1 "Solid Line" 2 "Dashed Line" 3 "Roadside";
VAL_ 515 R0_LINE_TYPE 0 "No display" 1 "solid line" 2 "dashed line" 3 "Roadside";
VAL_ 516 L1_LINE_TYPE 0 "NoDisplay" 1 "Solid Line" 2 "Dashed Line" 3 "Roadside";
VAL_ 516 L0_LINE_TYPE 0 "No display" 1 "solid line" 2 "dashed line" 3 "Roadside";
VAL_ 518 ADAS_HWA_Fautlstate 0 "no_error" 1 "HWA" 2 "fault" 3 "Reserved";
VAL_ 518 ADAS_ELK_check 0 "Available" 1 "Fault" 2 "Automatic deactivation" 3 "OFF-Manual Deactivation";
VAL_ 518 ADAS_handsoff_Warning_Mode_2 0 "No Warning!" 1 "Level 1" 2 "Level 2" 3 "Level 3" 4 "reserved" 5 "reserved" 6 "reserved" 7 "reserved";
VAL_ 518 ADAS_AHB_ICON_Feed 0 "Off" 1 "Gray ICON" 2 "Green ICON" 3 "White ICON" 4 "Yellow ICON" 5 "Red ICON";
VAL_ 518 ADAS_HWA_txtpopup 0 "-" 1 "None (Feature On)" 2 "None (Feature Off)" 3 "Please take over steering VinPilot error" 4 "VinPilot is unavailable Conditions not met" 5 "VinPilot is unavailable See Fault Details for more info" 6 "Take over driving now! VinPilot is Off";
VAL_ 518 ADAS_AHB_PopUp_Feed 0 "Off" 1 "Pop Up 1" 2 "Pop Up 2" 3 "Pop Up 3" 4 "Pop Up 4" 5 "Pop Up 5" 6 "Pop Up 6" 7 "Pop Up 7" 8 "Pop Up 8" 9 "Pop Up 9" 10 "Pop Up 10" 11 "Reserved" 12 "Reserved" 13 "Reserved" 14 "Reserved" 15 "Invalid";
VAL_ 518 ADAS_HWA_state 0 "Off" 1 "Stand_by" 2 "Active" 3 "Override" 4 "Passive" 5 "Active_suspend" 6 "Fault";
VAL_ 518 ADAS_ALC_Mode_feed 0 "OFF" 1 "ON" 2 "Reserved" 3 "Reserved";
VAL_ 518 ADAS_handsoff_txtpopup 0 "Please Hold the Steering Wheel!" 1 "Please Hold the Steering Wheel Immediately!" 2 "Reserved" 3 "Reserved";
VAL_ 518 ADAS_ALC_txtpopup 0 "-" 1 "Initiating Lane Changeâ?¦" 2 "Lane Change in progressâ?¦" 3 "Lane Change Timeout Target lane unavailable" 4 "Lane Change Cancelled" 5 "Lane Change Cancelled Returning to lane center" 6 "Lane Change is unavailable Use steering wheel to change lanes" 7 "Take over driving now! Lane Change System Error";
VAL_ 518 ADAS_ALC_state 0 "Off" 1 "Stand_by" 2 "Active" 3 "Override" 4 "Passive" 5 "Active_suspend" 6 "Fault";
VAL_ 518 ADAS_LA_Display 0 "left none,right none" 1 "left white,right none" 2 "left none,right white" 3 "left white,right white" 4 "left Blue,right none" 5 "left none,right blue" 6 "left blue,right blue" 7 "left none, right red" 8 "left red,right none" 9 "left white,right red" 10 "left red,right white" 11 "left blue,right red" 12 "left red,right blue" 13 "left gray,right none" 14 "left none,right gray" 15 "left gray,right gray";
VAL_ 519 SR_Undervoltage_Fault_Sts 0 "Normal" 1 "Fault";
VAL_ 519 SR_Overvoltage_Fault_Sts 0 "Normal" 1 "Fault";
VAL_ 519 SR_SLEEP_RQ 0 "Sleep Not Ready" 1 "Ready to Sleep";
VAL_ 519 SR_Position 0 "Unknown -Default" 1 "All Closed" 2 "All Closed To Tilt" 3 "Tilt" 4 "Tilt to Half Open" 5 "Half Open" 6 "Half Open to Open" 7 "ALL Open";
VAL_ 519 SR_Motor_Running_Sts 0 "Stop" 1 "Open Direction" 2 "Close Direction" 3 "Not Used";
VAL_ 519 SR_MotorReverse_Fault_Sts 0 "Normal" 1 "Fault";
VAL_ 519 SR_Hall_Fault_Sts 0 "Normal" 1 "Fault";
VAL_ 519 SR_Normalisation_Sts 0 "Normalised" 1 "Not normalised";
VAL_ 519 SR_Relay_Fault 0 "Normal" 1 "Fault";
VAL_ 519 SR_Commu_Fault_Sts 0 "Normal" 1 "Fault";
VAL_ 519 SR_Initialisation_Status 0 "Initialised" 1 "Not initialised";
VAL_ 519 SR_Ctrl_Result 0 "No Response" 1 "Running" 2 "Succeed" 3 "Failed";
VAL_ 519 SR_ThermalProtection_Fault_Sts 0 "Normal" 1 "Fault";
VAL_ 519 SR_Posit_Percentage 127 "Invalid";
VAL_ 519 SR_Operation_Stat 0 "Idle/Not pressed" 1 "Manual Slide Open" 2 "Manual Slide Closed" 3 "ManualTilt Open" 4 "Manual Tilt Closed" 5 "Auto Slide Open" 6 "Auto Slide Closed" 7 "Auto Tilt Open" 8 "Auto Tilt Closed";
VAL_ 519 SR_Error_RSP 0 "No Error" 1 "Error";
VAL_ 519 BCM_AutoSunroof_Sts 0 "OFF" 1 "Glass Only" 2 "Glass & Shade" 3 "Signal invalid";
VAL_ 520 SS_MotorReverse_Fault_Status 0 "Normal" 1 "Fault";
VAL_ 520 SS_Motor_Running_Status 0 "Stop" 1 "Open direction" 2 "Close direction" 3 "Not Used";
VAL_ 520 SS_Position 0 "Unknown-Default" 1 "All Closed" 2 "All Closed to Ajar" 3 "Ajar" 4 "Ajar to Half Open" 5 "Half Open" 6 "Half Open to Open" 7 "All Open";
VAL_ 520 SS_SLEEP_RQ 0 "Sleep Not Ready" 1 "Ready to Sleep";
VAL_ 520 SS_Undervoltage_Fault_Status 0 "Normal" 1 "Fault";
VAL_ 520 SS_Ctrl_Result 0 "No Response" 1 "Running" 2 "Succeed" 3 "Failed";
VAL_ 520 SS_Overvoltage_Fault_Status 0 "Normal" 1 "Fault";
VAL_ 520 SS_Relay_Fault 0 "Normal" 1 "Fault";
VAL_ 520 SS_Normalisation_Status 0 "Normalised" 1 "Not normalised";
VAL_ 520 SS_Hall_Fault_Status 0 "Normal" 1 "Fault";
VAL_ 520 SS_Commu_Fault_Status 0 "Normal" 1 "Fault";
VAL_ 520 SS_Initialisation_Status 0 "Normal" 1 "Fault";
VAL_ 520 SS_Posit_Percentage 127 "Invalid";
VAL_ 520 SS_ThermalProtection_Flt_Sts 0 "Normal" 1 "Fault";
VAL_ 520 SS_Operation_State 0 "Idle/Not pressed" 1 "Stop" 2 "Tilt Man" 3 "Tilt Auto" 4 "Close Man" 5 "Close Auto" 6 "Open Man" 7 "Open Auto";
VAL_ 520 SS_Error_RSP 0 "No Error" 1 "Error";
VAL_ 522 ETG_Lift_Gate_Status 0 "Fully closed" 1 "Fully opened" 2 "Stoped halfway" 3 "Ready to open" 4 "Opening" 5 "Ready to close" 6 "Closing" 7 "SNA (Signal not available)";
VAL_ 522 ETG_Power_Latch_Status 0 "uninitialized" 1 "Stoped" 2 "Cinching" 3 "Cinching reset" 4 "Releasing" 5 "Releasing reset" 7 "SNA";
VAL_ 522 ETG_Latch_Segment 0 "Full latch" 1 "Half latch" 2 "Open latch" 3 "SNA";
VAL_ 522 ETG_DSW_Status 0 "Not active" 1 "Active";
VAL_ 522 ETG_GSW_Status 0 "Not active" 1 "Active";
VAL_ 522 ETG_LTS_Status 0 "Not active" 1 "Active";
VAL_ 522 ETG_RTS_Status 0 "Not active" 1 "Active";
VAL_ 522 ETG_HAL_Status 0 "Low level" 1 "High level";
VAL_ 522 ETG_FUL_Status 0 "Low level" 1 "High level";
VAL_ 522 ETG_AJR_Status 0 "Low level" 1 "High level";
VAL_ 522 ETG_NTL_Status 0 "Low level" 1 "High level";
VAL_ 522 ETG_ERR_Voltage 0 "Normal" 1 "Under voltage" 2 "Over voltage";
VAL_ 522 ETG_ERR_Left_Motor 0 "Normal" 1 "Open circuit" 2 "short circuit";
VAL_ 522 ETG_ERR_Right_Motor 0 "Normal" 1 "Open circuit" 2 "short circuit";
VAL_ 522 ETG_ERR_Latch 0 "Normal" 1 "Open circuit" 2 "short circuit";
VAL_ 522 ETG_ERR_Hall 0 "Normal" 1 "Hall power short circuit" 2 "Hall position out of range" 3 "Hall signal out of sync";
VAL_ 522 ETG_Lift_Motor_Stall 0 "Not active" 1 "Active";
VAL_ 522 ETG_Lift_Motor_AntiPinch 0 "Not active" 1 "Active";
VAL_ 522 ETG_Lift_Motor_Thermal 0 "Not active" 1 "Active";
VAL_ 522 ETG_Power_Latch_Thermal 0 "Not active" 1 "Active";
VAL_ 522 ETG_Abuse_Protection 0 "Not active" 1 "Active";
VAL_ 523 FKS_RespError 0 "Ok" 1 "Error active";
VAL_ 523 FKS_OpenReq 0 "Idle" 1 "Operation Request" 2 "Invalid" 3 "Invalid";
VAL_ 523 FKS_HWError 0 "No Error" 1 "Error";
VAL_ 523 FKS_AntennaError 0 "No Error" 1 "Bottom or Top Sensor not connected" 2 "Bottom sensor short to Power or GND" 3 "Top sensor short to Power or GND";
VAL_ 523 FKS_OverVolDected 0 "No Error" 1 "Error";
VAL_ 523 FKS_UnderVolDected 0 "No Error" 1 "Error";
VAL_ 523 FKS_activate_deactivate 0 "Deactivated" 1 "Activated" 2 "Reserved" 3 "Signal invalid";
VAL_ 525 ESPTransRequestType 0 "No action" 1 "Inhibit upshift" 2 "Inhibit downshift" 3 "Hold gear";
VAL_ 525 ABSFault 0 "No fault" 1 "Fault";
VAL_ 525 ABSActive 0 "Inactive" 1 "Active";
VAL_ 525 ESC_VehicleStandstill 0 "NO_VEHICLE_STANDSTILL" 1 "VEHICLE_STANDSTILL";
VAL_ 525 MCPressureSts 0 "Valid" 1 "Invalid";
VAL_ 525 VehicleSpdSts 0 "Valid" 1 "Invalid";
VAL_ 525 ESC_Braking_effort 0 "No brake force generated" 1 "Brake force generated";
VAL_ 525 BRAKE_LightonRequestEPBi 0 "Brake light OFF" 1 "Brake light ON" 2 "Reserved" 3 "Signal not available";
VAL_ 525 VDCActive 0 "Inactive" 1 "Active";
VAL_ 525 TCSActive 0 "Inactive" 1 "Active";
VAL_ 525 TCSAvailable 0 "Avialable" 1 "Unavailable";
VAL_ 525 IDBActive 0 "Inactive" 1 "Active";
VAL_ 525 IDBFault 0 "No fault" 1 "Fault";
VAL_ 525 ESC_VehicleHoldStat 0 "No vehicle hold" 1 "vehicle hold" 2 "reserved" 3 "reserved";
VAL_ 525 IDB_Power_Stage 0 "Motor Max Power 150Kw" 1 "Motor Max Power 300Kw" 2 "Reserved" 3 "Reserved" 15 "Invalid";
VAL_ 525 ESC_BrakeReleasedFailsafe 0 "No need to release brakes because of failsafe situation" 1 "ESC is releasing the brakes because of failsafe";
VAL_ 531 VCU_enableDCDC 0 "Request OFF" 1 "Request ON";
VAL_ 533 BMS_BatBalance_ERR 0 "Error" 1 "normal";
VAL_ 533 BMS_Balance_STS 0 "Inactive" 1 "active";
VAL_ 533 BMS_IGN_Sts 0 "OFF" 1 "ON";
VAL_ 533 BMS_HWCrash_Sts 0 "No Crash" 1 "Crash";
VAL_ 533 BMS_HVIL_STS 0 "Closed" 1 "Open & short to battery" 2 "short to ground" 3 "Signal invalid";
VAL_ 533 BMS_HVOnOff_STS 0 "HV Off" 1 "Precharge" 2 "HV On" 3 "Fail to HV on";
VAL_ 533 BMS_ERR_LEV 0 "No error" 1 "Warning" 2 "Limp Home" 3 "Power down without FTTI" 4 "Delay power down with FTTI" 5 "Emergency off condition" 6 "Fault, needs to shutdown and wakeup" 7 "Battery locked - reserved";
VAL_ 533 BMS_Sys_STS 0 "Initialization of power on, self-checking" 1 "Self-check passes, can be high-voltage" 2 "Successful High Voltage Power Up" 3 "Successful Power Down of HV" 4 "Power Down process" 5 "Successful Power Down" 6 "BCU Sleep mode" 7 "Failure, unable to operate" 8 "Invalid";
VAL_ 533 BMS_ISU_Status 0 "Normal (> 250 kOhms)" 1 "Level1 (<250 kOhms ~ >100 kOhms)" 3 "Level3 (<100 kOhms)";
VAL_ 533 BMS_HV_Sts 0 "HV Off" 1 "Pre Charge" 2 "HV On" 3 "Super_Fast_Charge" 4 "AC Charge" 5 "Undefined" 6 "Undefined" 7 "Undefined" 8 "Undefined" 9 "Undefined";
VAL_ 544 MHU_SET_CCUR_AirCondition 0 "Not pressed" 1 "Pressed" 2 "Reserved" 3 "Signal invalid";
VAL_ 544 MHU_SET_CCUR_AutoAC 0 "Not pressed" 1 "Pressed" 2 "Reserved" 3 "Signal invalid";
VAL_ 544 MHU_SET_CCUR_RearLock 0 "Not pressed" 1 "Pressed" 2 "Reserved" 3 "Signal invalid";
VAL_ 544 MHU_SET_CCUR_MaxAc 0 "Not pressed" 1 "Pressed" 2 "Reserved" 3 "Signal invalid";
VAL_ 544 MHU_SET_CCUR_FanSpeed 0 "OFF" 1 "Level1" 2 "Level2" 3 "Level3" 4 "Level4" 5 "Level5" 6 "Level6" 7 "Signal invalid";
VAL_ 544 MHU_SET_CCUR_Recirculation 0 "Inside" 1 "Outside" 2 "Auto" 3 "Signal invalid";
VAL_ 544 MHU_SET_CCUR_Ion 0 "Not pressed" 1 "Pressed" 2 "Reserved" 3 "Signal invalid";
VAL_ 544 MHU_SET_CCUR_FlapPosition 0 "OFF" 1 "Face" 2 "Face and Feet" 3 "Feet" 4 "Feet and Defrost" 5 "Defrost" 6 "Default" 7 "Signal Invalid";
VAL_ 544 MHU_SET_CCUR_SyncClimateZone 0 "Not pressed" 1 "Pressed" 2 "Reserved" 3 "Signal invalid";
VAL_ 544 MHU_SET_CCUR_TempRear 32 "16" 33 "16.5" 34 "17" 35 "17.5" 36 "18" 37 "18.5" 38 "19" 39 "19.5" 40 "20" 41 "20.5" 42 "21" 43 "21.5" 44 "22" 45 "22.5" 46 "23" 47 "23.5" 48 "24" 49 "24.5" 50 "25" 51 "25.5" 52 "26" 53 "26.5" 54 "27" 55 "27.5" 56 "28" 57 "28.5" 58 "29" 59 "29.5" 60 "30" 61 "30.5" 62 "31" 63 "31.5" 64 "32" 255 "Invalid Value" ;
VAL_ 544 MHU_SET_CCUR_FrontDefrost 0 "Not pressed" 1 "Pressed" 2 "Reserved" 3 "Signal invalid";
VAL_ 545 DrvSeatMsgStrLvl 0 "OFF" 1 "Initial value" 2 "Level 1(Weak)" 3 "Level 2(General)" 4 "Level 3(Strong)" 5 "Not used" 6 "Not used" 7 "Not used";
VAL_ 545 PassSeatMsgStrLvl 0 "OFF" 1 "Intial value" 2 "Level 1 (Weak)" 3 "Level 2 (General)" 4 "Level 3 (Strong)" 5 "Not used" 6 "Not used" 7 "Not used";
VAL_ 545 RearDrvSeatMsgStrLvl 0 "Invalid" 1 "Initial value" 2 "Level 1 (Weak)" 3 "Level 2 (General)" 4 "Level 3 (Strong)" 5 "Not used" 6 "Not used" 7 "Not used";
VAL_ 545 RearPassSeatMsgStrLvl 0 "OFF" 1 "Initial value" 2 "Level 1(Weak)" 3 "Level 2(General)" 4 "Level 3(Strong)" 5 "Not used" 6 "Not used" 7 "Not used";
VAL_ 545 DrvSeatMsgMode 0 "OFF" 1 "Wave Mode" 2 "Cat Paw Mode" 3 "Cross Mode" 4 "Relieve Mode" 5 "Jump Mode" 6 "Invalid" 7 "Not used";
VAL_ 545 PassSeatMsgMode 0 "OFF" 1 "Wave Mode" 2 "Cat Paw Mode" 3 "Cross Mode" 4 "Relieve Mode" 5 "Jump Mode" 6 "Invalid" 7 "Not used";
VAL_ 545 RearDrvSeatMsgMode 0 "OFF" 1 "Wave Mode" 2 "Cat Paw Mode" 3 "Cross Mode" 4 "Relieve Mode" 5 "Jump Mode" 6 "Invalid" 7 "Not used";
VAL_ 545 RearPassSeatMsgMode 0 "OFF" 1 "Wave mode" 2 "Cat Paw Mode" 3 "Cross Mode" 4 "Relieve Mode" 5 "Jump Mode" 6 "invalid" 7 "Not used";
VAL_ 546 DrvSeatMsgModeStat 0 "OFF" 1 "Wave Mode" 2 "Cat Paw Mode" 3 "Cross Mode" 4 "Relieve Mode" 5 "Jump Mode" 6 "Invalid" 7 "Not used";
VAL_ 546 PassSeatMsgModeStat 0 "OFF" 1 "Wave Mode" 2 "Cat Paw Mode" 3 "Cross Mode" 4 "Relieve Mode" 5 "Jump Mode" 6 "Invalid" 7 "Not used";
VAL_ 546 RearDrvSeatMsgModeStat 0 "OFF" 1 "Wave mode" 2 "Cat Paw Mode" 3 "Cross Mode" 4 "Relieve Mode" 5 "Jump Mode" 6 "invalid" 7 "Not used";
VAL_ 546 RearPassSeatMsgModeStat 0 "OFF" 1 "Wave mode" 2 "Cat Paw Mode" 3 "Cross Mode" 4 "Relieve Mode" 5 "Jump Mode" 6 "invalid" 7 "Not used";
VAL_ 546 LSSM_ALINResErr 0 "No Error" 1 "Error";
VAL_ 546 LSSM_APumpFail 0 "Invalid" 1 "No Error" 2 "Error" 3 "Reserved";
VAL_ 546 DrvSeatMsgStrLvlStat 0 "OFF" 1 "Initial value" 2 "Level 1(Weak)" 3 "Level 2(General)" 4 "Level 3(Strong)" 5 "Not used" 6 "Not used" 7 "Not used";
VAL_ 546 LSSM_BLINResErr 0 "No Error" 1 "Error";
VAL_ 546 LSSM_BPumpFail 0 "Invalid" 1 "No Error" 2 "Error" 3 "Reserved";
VAL_ 546 PassSeatMsgStrLvlStat 0 "Invalid" 1 "Initial value" 2 "Level 1 (Weak)" 3 "Level 2 (General)" 4 "Level 3 (Strong)" 5 "Not used" 6 "Not used" 7 "Not used";
VAL_ 546 LSSM_CLINResErr 0 "No Error" 1 "Error";
VAL_ 546 LSSM_CPumpFail 0 "Invalid" 1 "No Error" 2 "Error" 3 "Reserved";
VAL_ 546 RearDrvSeatMsgStrLvlStat 0 "Invalid" 1 "Initial value" 2 "Level 1 (Weak)" 3 "Level 2 (General)" 4 "Level 3 (Strong)" 5 "Not used" 6 "Not used" 7 "Not used";
VAL_ 546 LSSM_DLINResErr 0 "No Error" 1 "Error";
VAL_ 546 LSSM_DPumpFail 0 "Invalid" 1 "No Error" 2 "Error" 3 "Reserved";
VAL_ 546 RearPassSeatMsgStrLvlStat 0 "OFF" 1 "Initial value" 2 "Level 1(Weak)" 3 "Level 2(General)" 4 "Level 3(Strong)" 5 "Not used" 6 "Not used" 7 "Not used";
VAL_ 549 CDM_bAcvCanComStblMon 0 "No error" 1 "Error";
VAL_ 549 FRMo_bErrHvbatStReqExtMon 0 "No error" 1 "Error";
VAL_ 549 FRMo_bErrChrgnAllwdExtMon 0 "No error" 1 "Error";
VAL_ 549 FRMo_bErrVehCrashStExtMon 0 "No error" 1 "Error";
VAL_ 549 CDM_bErrComctnLossCanMon 0 "No error" 1 "Error";
VAL_ 549 CTCMon_bErrCtctrSopcMon 0 "No error" 1 "Error";
VAL_ 549 CTCMon_bInvldCtctrHisdIFbMon 0 "No error" 1 "Error";
VAL_ 549 CTCMon_bInvldCtctrLosdUFbMon 0 "No error" 1 "Error";
VAL_ 549 CTM_bErrCellTDifMaxMon 0 "No error" 1 "Error";
VAL_ 549 CTM_bErrCellTMaxMon 0 "No error" 1 "Error";
VAL_ 549 CTM_bErrCellTMinMon 0 "No error" 1 "Error";
VAL_ 549 CTM_bErrThrwyPredMon 0 "No error" 1 "Error";
VAL_ 549 CUM_bErrCellUDifMaxMon 0 "No error" 1 "Error";
VAL_ 549 CUM_bErrCellUMaxMon 0 "No error" 1 "Error";
VAL_ 549 CUM_bErrCellUMinMon 0 "No error" 1 "Error";
VAL_ 549 CUM_bErrCellUProtnMaxNvMon 0 "No error" 1 "Error";
VAL_ 549 CUM_bErrCellUProtnMinNvMon 0 "No error" 1 "Error";
VAL_ 549 CUM_bErrPackUImplyMon 0 "No error" 1 "Error";
VAL_ 549 EHPMon_bRdyHvilMon 0 "No error" 1 "Error";
VAL_ 549 EHPMon_bErrWlddNegNvMon 0 "No error" 1 "Error";
VAL_ 549 EHPMon_bErrWlddPosNvMon 0 "No error" 1 "Error";
VAL_ 549 EHPMon_bErrWlddPrechNvMon 0 "No error" 1 "Error";
VAL_ 549 EHPMon_bErrHvilMon 0 "No error" 1 "Error";
VAL_ 549 EHPMon_bErrHvilShoMon 0 "No error" 1 "Error";
VAL_ 549 EHPMon_bErrPackIslnRNvMon 0 "No error" 1 "Error";
VAL_ 549 EHPMon_bErrVehCrashNvMon 0 "No error" 1 "Error";
VAL_ 549 EHPMon_bErrVehIslnRNvMon 0 "No error" 1 "Error";
VAL_ 549 FRMo_bErrMemStorgNvMon 0 "No error" 1 "Error";
VAL_ 549 L1IM_bErrClmp30MaxMonInp 0 "No error" 1 "Error";
VAL_ 549 L1IM_bErrClmp30MinMonInp 0 "No error" 1 "Error";
VAL_ 549 L1IM_bErrCtctrDtrtMonInp 0 "No error" 1 "Error";
VAL_ 549 L1IM_bErrUActImplyMonInp 0 "No error" 1 "Error";
VAL_ 549 MCCM_bAcvMdulCtlrStsMon 0 "No error" 1 "Error";
VAL_ 549 MCCM_bErrLntecSngFltMon 0 "No error" 1 "Error";
VAL_ 549 MCCM_bErrLntecLtntFltMon 0 "No error" 1 "Error";
VAL_ 549 MCCM_bErrMdulCellSnsrCfgMon 0 "No error" 1 "Error";
VAL_ 549 MCCM_bErrMdulCtlrComMon 0 "No error" 1 "Error";
VAL_ 549 MCCM_bErrSnsrTEltlMon 0 "No error" 1 "Error";
VAL_ 549 MCCM_bWarnSnsrTEltlMon 0 "No error" 1 "Error";
VAL_ 549 PCM_bRdySnsrIMon 0 "No error" 1 "Error";
VAL_ 549 PCM_bErrPackEFlowMaxLimMon 0 "No error" 1 "Error";
VAL_ 549 PCM_bErrPackIChDchaMaxLimMon 0 "No error" 1 "Error";
VAL_ 549 PCM_bErrSnsrIImplyMon 0 "No error" 1 "Error";
VAL_ 549 FRMo_bErrSnsrI1ExtMon 0 "No error" 1 "Error";
VAL_ 549 PCM_bInvldSnsrI1Mon 0 "No error" 1 "Error";
VAL_ 549 PCM_bInvldSnsrI2Mon 0 "No error" 1 "Error";
VAL_ 549 FRMo_bErrSopcLvl3Mon 0 "No error" 1 "Error";
VAL_ 549 BMS_FRMo_Reserved_1 0 "No error" 1 "Error";
VAL_ 549 BMS_FRMo_Reserved_2 0 "No error" 1 "Error";
VAL_ 549 BMS_FRMo_Reserved_3 0 "No error" 1 "Error";
VAL_ 549 BMS_FRMo_Reserved_4 0 "No error" 1 "Error";
VAL_ 549 BMS_FRMo_Reserved_5 0 "No error" 1 "Error";
VAL_ 561 NDoorFLOutsideHandleFailure 0 "Default (No Failure)" 1 "EEPROM, ROM and DSP self-test" 2 "Magnetic field is too low" 3 "Magnetic field is too high" 4 "Overvoltage" 5 "Undervoltage" 6 "A/D converter clipping" 7 "Reserved";
VAL_ 561 NDoorLatchFLFailure 0 "no fault" 1 "fault code" 2 "fault code" 3 "fault code" 4 "fault code" 5 "fault code" 6 "fault code" 63 "fault code";
VAL_ 565 TowingDetected 0 "Towing not detected" 1 "Towing detected" 3 "Invalid";
VAL_ 565 TrailerDetected 0 "Trailer not detected" 1 "Trailer detected" 3 "Invalid";
VAL_ 569 NDoorRROutsideHandleFailure 0 "Default (No Failure)" 1 "EEPROM, ROM and DSP self-test" 2 "Magnetic field is too low" 3 "Magnetic field is too high" 4 "Overvoltage" 5 "Undervoltage" 6 "A/D converter clipping" 7 "Reserved";
VAL_ 569 NDoorLatchRRFailure 0 "No Fault" 1 "Fault Code" 2 "Fault Code" 3 "Fault Code" 4 "Fault Code" 5 "Fault Code" 6 "Fault Code" 7 "Fault Code" 8 "Fault Code" 9 "Fault Code" 10 "Fault Code" 11 "Fault Code" 12 "Fault Code" 13 "Fault Code" 14 "Fault Code" 127 "Fault Code";
VAL_ 581 BMS_ProbeNumMaxCellTemp 0 "Invalid" 62 "Error" 63 "Invalid";
VAL_ 581 BMS_ProbeNumMinCellTemp 0 "Invalid" 62 "Error" 63 "Invalid";
VAL_ 584 NDoorFROutsideHandleFailure 0 "Default (No Failure)" 1 "EEPROM, ROM and DSP self-test" 2 "Magnetic field is too low" 3 "Magnetic field is too high" 4 "Overvoltage" 5 "Undervoltage" 6 "A/D converter clipping" 7 "Reserved";
VAL_ 584 NDoorLatchFRFailure 0 "No Fault" 1 "Fault Code" 2 "Fault Code" 3 "Fault Code" 4 "Fault Code" 5 "Fault Code" 6 "Fault Code" 7 "Fault Code" 8 "Fault Code" 9 "Fault Code" 10 "Fault Code" 11 "Fault Code" 12 "Fault Code" 13 "Fault Code" 14 "Fault Code" 127 "Fault Code";
VAL_ 588 BMS_VCU_PTCOnOff_Req 0 "OFF" 1 "ON";
VAL_ 588 BMS_VCU_ValveOnOff_Req 0 "close" 1 "open";
VAL_ 588 BMS_PreHeatCoolReq 0 "Precondition OFF" 1 "Precondition Heating ON" 2 "Precondition Cooling ON" 3 "Invalid value";
VAL_ 596 QU_AVL_RPM_WHL_RLH 1 "Signal value is valid and secured and checked for plausibility" 2 "Reserved" 3 "Reserved" 4 "Substitute value is set in the useful signal" 6 "Signal value is invalid (Electrical fault, can be repaired)" 7 "Reserved" 8 "initialization" 9 "Reserved" 10 "Reserved" 11 "Signal quality or monitoring restricted, state / status temporary" 12 "Substitute value is set in the useful signal State / status temporary" 14 "Signal value is invalid (Electrical fault, can not repaired)" 15 "Signal invalid";
VAL_ 596 QU_AVL_RPM_WHL_RRH 1 "Signal value is valid and secured and checked for plausibility" 2 "Reserved" 3 "Reserved" 4 "Substitute value is set in the useful signal" 6 "Signal value is invalid (Electrical fault, can be repaired)" 7 "Reserved" 8 "initialization" 9 "Reserved" 10 "Reserved" 11 "Signal quality or monitoring restricted, state / status temporary" 12 "Substitute value is set in the useful signal State / status temporary" 14 "Signal value is invalid (Electrical fault, can not repaired)" 15 "Signal invalid";
VAL_ 597 QU_AVL_RPM_WHL_FLH 1 "Signal value is valid and secured and checked for plausibility" 2 "Reserved" 3 "Reserved" 4 "Substitute value is set in the useful signal" 6 "Signal value is invalid (Electrical fault, can be repaired)" 7 "Reserved" 8 "initialization" 9 "Reserved" 10 "Reserved" 11 "Signal quality or monitoring restricted, state / status temporary" 12 "Substitute value is set in the useful signal State / status temporary" 14 "Signal value is invalid (Electrical fault, can not repaired)" 15 "Signal invalid";
VAL_ 597 QU_AVL_RPM_WHL_FRH 1 "Signal value is valid and secured and checked for plausibility" 2 "Reserved" 3 "Reserved" 4 "Substitute value is set in the useful signal" 6 "Signal value is invalid (Electrical fault, can be repaired)" 7 "Reserved" 8 "initialization" 9 "Reserved" 10 "Reserved" 11 "Signal quality or monitoring restricted, state / status temporary" 12 "Substitute value is set in the useful signal State / status temporary" 14 "Signal value is invalid (Electrical fault, can not repaired)" 15 "Signal invalid";
VAL_ 641 NDoorRLOutsideHandleFailure 0 "Default (No Failure)" 1 "EEPROM, ROM and DSP self-test" 2 "Magnetic field is too low" 3 "Magnetic field is too high" 4 "Overvoltage" 5 "Undervoltage" 6 "A/D converter clipping" 7 "Reserved";
VAL_ 641 NDoorLatchRLFailure 0 "no fault" 1 "fault code" 2 "fault code" 3 "fault code" 4 "fault code" 5 "fault code" 6 "fault code" 63 "fault code";
VAL_ 649 AxOutStatus 0 "Valid" 1 "Invalid";
VAL_ 649 QU_VYAW_VEH 0 "Description for the value '0x0'" 1 "Description for the value '0x1'";
VAL_ 649 AyOutStatus 0 "Valid" 1 "Invalid";
VAL_ 649 AcceleratorY 16533 "Invalid";
VAL_ 649 AcceleratorX 16533 "Invalid";
VAL_ 654 Window_PosFL 0 "Closed (top)" 1 "Open (bottom)" 2 "Between 80% to closed" 3 "Between open to 80%" 4 "Reserved" 5 "Reserved" 6 "Reserved" 7 "Signal Invalid";
VAL_ 654 Window_Warning 0 "Not active" 1 "Active" 2 "Reserved" 3 "Signal Invalid";
VAL_ 654 Wndow_PosRL 0 "Closed (top)" 1 "Open (bottom)" 2 "Between 80% to closed" 3 "Between open to 80%" 4 "Reserved" 5 "Reserved" 6 "Reserved" 7 "Signal Invalid";
VAL_ 654 Window_PosFR 0 "Closed (top)" 1 "Open (bottom)" 2 "Between 80% to closed" 3 "Between open to 80%" 4 "Reserved" 5 "Reserved" 6 "Reserved" 7 "Signal Invalid";
VAL_ 654 Global_close 0 "Deactivated" 1 "Activated" 2 "Reserved" 3 "Signal Invalid";
VAL_ 654 Global_open 0 "Deactivated" 1 "Activated" 2 "Reserved" 3 "Signal Invalid";
VAL_ 654 Window_PosRR 0 "Closed (top)" 1 "Open (bottom)" 2 "Between 80% to closed" 3 "Between open to 80%" 4 "Reserved" 5 "Reserved" 6 "Reserved" 7 "Signal Invalid";
VAL_ 676 ECU_ID_WUPREG 255 "Signal invalid";
VAL_ 676 ID_FN_INQY 161 "Operation button Entertainment" 246 "Control exterior mirror" 426 "Effect ErgoCommander" 482 "Safe VIN" 525 "Position steering column" 550 "Rain sensor wiper speed" 570 "Status key" 594 "Wiper status" 615 "Operation pushbutton operating menu" 638 "Status soft top convertible" 742 "Status Climate Air distribution drivere" 746 "Status Climate Air distribution passenger" 748 "Status Climate " 750 "Status climate additional programs" 752 "Status Climate Stand functions" 759 "Unit" 760 "Time date" 768 "Status RSE" 783 "Status Service Call TeleX" 787 "Status Service Call Teleservice" 806 "Wirkungsgrad Information Data" 818 "Consumption information" 822 "Display checkcontrol message" 826 "Status Monitor Front" 828 "Status Monitor Rear 1" 830 "Status Monitor Rear 2" 833 "Status card data" 841 "Raw value fuel tank" 860 "Status Bordcomputer" 864 "Daten Bordcomputer 1" 896 "VIN" 897 "Electronic engine oil stick" 904 "vehicle type" 917 "Coding Powermanagement" 921 "Status M-Drive" 937 "Status ECM CKM" 939 "Status Shiftlights CKM" 950 "Position window regulator driver" 951 "Position window regulator driver rear" 952 "Position window regulator passenger" 953 "Position window regulator passenger rear" 954 "Position sliding roof" 956 "Position window lift sec" 959 "Position window lift tailgate" 960 "Configuration FAS" 961 "Configuration BFS" 962 "Configuration FASH" 963 "Configuration BFSH" 964 "Status EDCK CKM" 976 "Status lane departure warning system" 981 "Status cental lock" 983 "Status DWA CKM" 985 "Status RLS CKM" 987 "Status Memoryposition CKM" 989 "Status Light CKM" 991 "Status Climate CKM" 993 "Status ALC CKM" 995 "Status tailgateCKM" 1003 "Limits swing left" 1004 "Limits swing right" 1009 "Status light Extended  CKM" 1013 "Status of cargo compartment cover CKM" 1050 "Status Configuration IC 4" 1060 "Status Configuration IC" 1063 "Configuration DSC" 1070 "Status M-Drive 2" 1076 "Configuration EPS" 1077 "Measure engine oil" 1087 "Identification number Sensorcluster" 65535 "Signal invalid";
VAL_ 676 ID_FN_RQ_BUS 1 "Entertainment function" 2 "Remote Services" 3 "Residual heat function / burnout" 4 "Auxiliary heating/parking ventilation" 5 "Extension N-Holding Phase" 6 "Operation parking brake" 7 "Follow-up / connection RSE" 8 "Remote horn" 25 "Switch on / extension clamp" 43 "Alarm" 44 "EMF-button" 45 "roll monitoring" 46 "Requirement outside lighting" 47 "transhipment function" 51 "KL15Wup-Signal" 53 "Coolant temperature" 54 "IC display" 257 "switch on preventer" 258 "Wacke up " 259 "Switch OFF KL30F Stand time" 260 "Switch OFF KL30F CarSharing" 272 "OBD-Diagnostic" 273 "Exstension time water pump" 275 "Exstension time E-fan" 276 "Exstension time water pump additional Waterpumpe" 277 "Exstension time water pump hyb" 278 "Standl ventilation" 280 "Third-party charge detection hybrid / charging" 281 "Battery monitor  TSR" 288 "Leveling" 289 "Exstension time ventilation cooling" 304 "Trailer connection AAG" 305 "Req IK" 306 "Req IK OSFG" 513 "Domainmaster  ICE" 514 "Domainmaster elec motor" 515 "Domainmaster entertainment" 516 "Domainmaster body" 517 "Domainmaster Chasis" 769 "BDC Internal 30B Request inlight" 770 "BDC Internal 30B Request outlight" 771 "BDC Internal 30B Request FA-CAN " 772 "BDC Internal 30B Request Telesta" 773 "BDC Internal 30B Request Battery" 774 "CO2 Sensor" 65535 "Signal invalid";
VAL_ 676 NO_CC_MESS_STD 0 "No Error" 1 "Error(CurveBehavrestricted)" 2 "Error (Limited driving comfort)";
VAL_ 676 WACA 0 "ECU reset" 1 "Car alarm" 2 "Residual heat" 3 "CO2-recognition" 4 "CD/DVD Eject/CD/DVD insert" 5 "OFF switch light" 6 "Mirror" 7 "Remote Services" 8 "Emergency Call" 9 "CAS-Bus, button tailgate" 10 "CID-flap button" 11 "Smart Opener" 12 "Start charging" 14 "Switch for hitch" 16 "Door contact front driver" 17 "Door contact front passenger" 18 "Door contact front driver rear" 19 "Door contact front driver rear" 20 "Button driver door CA" 21 "Button passenger door CA" 22 "Button opener tailgate inner" 23 "Button opener tailgate" 24 "Button opener tailgate window" 25 "Tailgate contact" 26 "Input tailgate window" 27 "Bonnet" 28 "Unlock door lock / comfort opening" 29 "Lock door lock / comfort lock" 30 "Short circuit terminal 30 B" 32 "Start Stop button A" 33 "Start Stop button B" 34 "Hallsensor Eject" 35 "Center lock unlock" 36 "Park Automatic" 37 "Light swich ON" 38 "Hazard switch" 39 "Steering column switch to flash" 40 "Lenkstocktaster towards" 41 "Lenkstocktaster towards light" 42 "interior switch" 43 "Gear switch" 44 "EMF- Button" 45 "Entertainmen" 46 "Steering colunm adjustment switch" 47 "Regulation air spring" 48 "RKE" 49 "Wakeup-Signal TCU" 50 "Hotel switch" 51 "IBS" 52 "Parking heater / ventilate / climate" 53 "Coolant query by IC" 54 "Klemme 15 Wakeu line" 55 "Button Driver's door rear release" 56 "Button passenger door rear release" 57 "Button Driver's door" 58 "Button passenger door release" 59 "Button Driver's door rear release" 60 "Button passenger door rear release" 61 "Brake light switch" 62 "Clutch switch" 63 "Invalid wake-up reason, wake-up reason" 64 "Fog light" 65 "Rear fog light" 66 "Sarah- button" 67 "FES-button" 68 "PDC-button" 69 "Side-View-button" 70 "Rear spoiler-Taster" 71 "VDP-" 72 "MSA-button" 73 "Button audio volume steering wheel" 74 "Button special function" 75 "Button knurled steering wheel" 76 "Push-button telephone steering wheel" 77 "Push-button PTT steering wheel" 78 "Push-button seat heating driver" 79 "Push-button seat heating passenger" 80 "Push-button seat heating driver rear" 81 "Push-button seat heating passenger rear" 82 "Seat memory driver" 83 "Switch block door China long" 84 "Steering switch light" 85 "Door control unit" 88 "Car Sharing Modul" 89 "seat switch" 90 "AC control" 91 "PWF state change" 93 "Park light switch" 96 "Seat memory driver rear" 97 "Seat memory passenger" 98 "Seat memory pasenger rear" 99 "Nox-Diagnosis" 102 "Closing aid" 112 "Wake up" 255 "Signal invalid";
VAL_ 676 ST_CC_MESS_STD 0 "No Error" 1 "Error";
VAL_ 676 TRANF_CC_MESS_STD 0 "No Error" 1 "Error";
VAL_ 676 ST_IDC_CCLK_CC_MESS_STD 0 "No Error" 1 "Error";
VAL_ 714 MHU_STAT_CoolantLevelStatus 0 "Normal condition" 1 "Low level condition" 2 "Reserved" 3 "Signal Invalid";
VAL_ 753 MHU_STAT_AirbagWarnLamp 0 "Lamp off" 1 "Lamp on" 2 "Lamp failure" 3 "Signal invalid";
VAL_ 760 DISP_DATE_WDAY 1 "Monday" 2 "Tuesday" 3 "Wednesday" 4 "Thursday" 5 "Friday" 6 "Saturday" 7 "Sunday" 15 "Signal invalid";
VAL_ 760 ST_DISP_CTI_DATE 0 "data not valid" 1 "data valid" 3 "UTC" 5 "winter time" 6 "Manually set time" 7 "summer time" 15 "signal invalid";
VAL_ 768 CCU_STAT_SyncClimateZone 0 "OFF" 1 "ON" 2 "Reserved" 3 "Signal invalid";
VAL_ 768 CCU_STAT_Auto 0 "OFF" 1 "ON" 2 "Reserved" 3 "Signal invalid";
VAL_ 768 CCU_STAT_Aircondition 0 "OFF" 1 "ON" 2 "Reserved" 3 "Signal invalid";
VAL_ 768 CCU_STAT_IonButton 0 "OFF" 1 "ON" 2 "Reserved" 3 "Signal invalid";
VAL_ 768 CCU_STAT_MaxAc 0 "OFF" 1 "ON" 2 "Reserved" 3 "Signal invalid";
VAL_ 768 CCU_STAT_OnOff 0 "OFF" 1 "ON" 2 "Reserved" 3 "Signal invalid";
VAL_ 768 CCU_STAT_FanSpeed 0 "OFF" 1 "Level 1" 2 "Level 2" 3 "Level 3" 4 "Level 4" 5 "Level 5" 6 "Level 6" 7 "Reserved" 8 "Reserved" 9 "Reserved" 10 "Reserved" 11 "Reserved" 12 "Reserved" 13 "Reserved" 14 "Reserved" 15 "Signal invalid";
VAL_ 768 CCU_STAT_RecircFlap 0 "Inside" 1 "Outside" 2 "Auto" 3 "Signal invalid";
VAL_ 768 CCU_STAT_FlapPos 0 "OFF" 1 "Vent" 2 "Vent/Foot" 3 "Foot" 4 "Foot/Defrost" 5 "Defrost" 6 "Default" 7 "Signal invalid";
VAL_ 768 CCU_STAT_Defrost 0 "OFF" 1 "ON" 2 "Reserved" 3 "Signal invalid";
VAL_ 768 CCU_STAT_PTC_Heater 0 "OFF" 1 "Stage 1" 2 "Stage 2" 3 "Stage 3" 4 "Reserved" 5 "Reserved" 6 "Reserved" 7 "Signal invalid";
VAL_ 769 RP_ReqInfoDispTxt2 0 "No request" 1 "The door is open, please close the door" 2 "The front hatch door is open, please close the door" 3 "The tailgate is open, please close the door" 4 "RP parking assist system failure, parking exit" 5 "RP related actuator failure, parking exit" 6 "Control distance exceeds the limit, parking exit" 7 "The gear is not in the P gear, the RP cannot be opened, and the system exits" 8 "The gear is not in the P gear, please put the gear into P" 9 "The slope is too large to activate the parking function" 10 "The tire pressure is low and does not meet the parking requirements" 11 "SM related actuator failure, parking exit" 12 "SM parking assist system failure, parking exit";
VAL_ 769 RP_Status 0 "Off" 1 "Standby" 2 "Enable" 3 "Active" 4 "Finished" 5 "Suspend" 6 "Abort" 7 "Failed";
VAL_ 769 ADAS_TboxAuthStatus 0 "Have not learn. Not allow action" 1 "PASSED" 2 "FALIED: Authentication fail" 3 "Invalid";
VAL_ 769 RP_ParkOutDircnDisReq 0 "No request" 1 "request";
VAL_ 769 RP_ParkOutModeDisReq 0 "No request" 1 "request";
VAL_ 769 RP_ReqInfoDispTxt1 0 "No request" 1 "Timeout" 2 "gear intervention" 3 "throttle intervention" 4 "steering wheel intervention" 5 "Electronic handbrake invnt" 6 "Door is opened" 7 "parking times exceeds the limit" 8 "The road slope is too big" 9 "resumable interrupt exceeds li" 10 "Associated ECU failure" 11 "Parking speed exceeds limit" 12 "Parking system failure" 13 "gear can't be switched normal" 14 "driver takes initiative to ex" 15 "vehicle cannot move" 16 "When an obstacle is detected" 17 "driver's seat belt is loosened" 18 "Contrl dist about to excd limit" 19 "parking space is limited" 20 "tailgate is opened" 21 "Reserved" 22 "Reserved" 23 "front hatch door is opened" 24 "Parking is completed" 25 "Parking failed" 26 "Remote connection is interrupted" 27 "pull up the EPB get off" 28 "Remote parking has started" 29 "slope large to contin park func" 30 "SM has started" 31 "collision happens";
VAL_ 769 SM_Startfdbck 0 "No Request" 1 "SM on";
VAL_ 769 SM_Quitfdbck 0 "No Request" 1 "SM off";
VAL_ 769 SM_Status 0 "OFF" 1 "Standby" 2 "Enable" 3 "Active" 4 "Finished" 5 "Suspend" 6 "Abort" 7 "Failed";
VAL_ 771 ADAS_DMS_Thief_image_sendrequest 0 "Init" 1 "Sending request" 2 "Sending processing" 3 "Stop sending";
VAL_ 771 ADAS_DMS_Status_feed 0 "Init" 1 "DMS on" 2 "DMS off" 3 "wearing mask" 4 "wearing ir-blocking glasses" 5 "no face detected" 6 "reserved" 7 "Reserved";
VAL_ 771 ADAS_DMS_Confidence_score 0 "Init" 1 ">95%" 2 "<95%" 3 "receive";
VAL_ 771 ADAS_DMS_Driver_registration 0 "Init" 1 "ID request" 2 "ID already exists" 3 "Iditification Success" 4 "Delete success" 5 "error by mask detection" 6 "error by sun glass detection" 7 "error by head position";
VAL_ 773 BMS_VCU_Insulation_Mon_Sts 0 "ON" 1 "OFF";
VAL_ 775 OUT_Alert_TO_BCM 0 "Init" 1 "Warning level 1" 2 "Warning level 2" 3 "Warning level 3" 4 "Deactivate Warning" 5 "Invalid Value";
VAL_ 775 CPD_State_information 0 "Enable" 1 "Disable" 2 "Child Mode" 3 "Pet Mode" 4 "Reserved" 5 "Reserved" 6 "Reserved" 7 "Reserved";
VAL_ 775 OUT_Alert_TO_MHU 0 "Init" 1 "Default Warning" 2 "Warning on MHU" 3 "Warning Outside (Send SMS)" 4 "Deactivate Warning";
VAL_ 776 MHU_CPD_Setting 0 "Enable" 1 "Disable" 2 "Child Mode" 3 "Delay CPD" 4 " Reserved" 5 " Reserved" 6 " Reserved" 7 " Reserved";
VAL_ 776 MHU_CPD_Confirmation_On_HMI 0 "No confirmation" 1 "User confirmation" 2 "Reserved" 3 "Reserved" 4 " Reserved" 5 " Reserved" 6 " Reserved" 7 " Reserved";
VAL_ 784 CCUR_STAT_IonButton 0 "OFF" 1 "ON" 2 "Reserved" 3 "Signal invalid";
VAL_ 784 CCUR_STAT_Defrost 0 "OFF" 1 "ON" 2 "Reserved" 3 "Signal invalid";
VAL_ 784 CCUR_STAT_Auto 0 "OFF" 1 "ON" 2 "Reserved" 3 "Signal invalid";
VAL_ 784 CCUR_STAT_Aircondition 0 "OFF" 1 "ON" 2 "Reserved" 3 "Signal invalid";
VAL_ 784 CCUR_STAT_FlapPos 0 "OFF" 1 "Vent" 2 "Vent/Foot" 3 "Foot" 4 "Foot/Defrost" 5 "Defrost" 6 "Default" 7 "Signal invalid";
VAL_ 784 CCUR_STAT_FanSpeed 0 "OFF" 1 "Level 1" 2 "Level 2" 3 "Level 3" 4 "Level 4" 5 "Level 5" 6 "Level 6" 7 "Reserved" 8 "Reserved" 9 "Reserved" 10 "Reserved" 11 "Reserved" 12 "Reserved" 13 "Reserved" 14 "Reserved" 15 "Signal invalid";
VAL_ 784 CCUR_STAT_PTC_Heater 0 "OFF" 1 "Stage 1" 2 "Stage 2" 3 "Stage 3" 4 "Reserved" 5 "Reserved" 6 "Reserved" 7 "Signal invalid";
VAL_ 784 CCUR_STAT_OnOff 0 "OFF" 1 "ON" 2 "Reserved" 3 "Signal invalid";
VAL_ 784 CCUR_STAT_MaxAc 0 "OFF" 1 "ON" 2 "Reserved" 3 "Signal invalid";
VAL_ 784 CCUR_STAT_SyncClimateZone 0 "OFF" 1 "ON" 2 "Reserved" 3 "Signal invalid";
VAL_ 784 CCUR_STAT_RecircFlap 0 "Inside" 1 "Outside" 2 "Auto" 3 "Signal invalid";
VAL_ 787 POD_statusOBC 0 "OBC_OFF" 1 "OBC_STANDBY" 2 "OBC_ON_NORMAL" 3 "OBC_ON_VOLTAGE" 4 "OBC_DEGRADED" 5 "OBC_FAULT_SHUTDOWN" 6 "OBC_EMERGENCY_SHUTDOWN" 7 "OBC_STS_SNA";
VAL_ 803 POD_phaseACInput 0 "Not Used" 1 "AC 1 phase input" 2 "Not used" 3 "AC 3 phase input";
VAL_ 804 Steering_HeatingControl 0 "Disable" 1 "Enable";
VAL_ 805 Steering_HeatingControlFdbk 0 "Disable" 1 "Enable" 2 "Error";
VAL_ 806 POD_statusDCDC 0 "DCDC_OFF" 1 "DCDC_STANDBY" 2 "DCDC_ON" 3 "DCDC_RESERVED" 4 "DCDC_DEGRADED" 5 "DCDC_FAULT_SHUTDOWN" 6 "DCDC_EMERGENCY_SHUTDOWN" 7 "DCDC_STS_SNA";
VAL_ 807 POD_statusFCContactors 0 "FC_CONTACTORS_OPEN" 1 "FC_CONTACTORS_CLOSING" 2 "FC_CONTACTRORS_CLOSED" 3 "FC_CONTACTORS_OPENING" 4 "FC_CONTACTORS_WELDED" 5 "FC_CONTACTORS_FAULT" 7 "FC_CONTACTORS_SNA";
VAL_ 816 ST_FLLV_FUTA_SPAR 0 "No active" 1 "Active" 2 "Reserved" 3 "Signal invalid";
VAL_ 827 Camera_R1_Line_Type 0 "No display" 1 "solid line" 2 "dashed line" 3 "Roadside";
VAL_ 827 Camera_L1_Line_Type 0 "off" 1 "Gray ICON" 2 "Green ICON" 3 "reserved";
VAL_ 833 ADAS_OBJ01_Class 0 "Unknown" 1 "Car" 2 "Truck" 3 "Motorbike" 4 "bicycle" 5 "Pedestrian" 6 "truck or car" 7 "reserved";
VAL_ 833 ADAS_OBJ01_Lane 0 "Undefined" 1 "Left lane" 2 "Host lane" 3 "Right lane";
VAL_ 835 ADAS_OBJ02_Class 0 "Unknown" 1 "Car" 2 "Truck" 3 "Motorbike" 4 "bicycle" 5 "Pedestrian" 6 "truck or car" 7 "reserved";
VAL_ 835 ADAS_OBJ02_Lane 0 "Undefined" 1 "Left lane" 2 "Host lane" 3 "Right lane";
VAL_ 840 EDS_HVIL_STS_FWD 0 "Closed" 1 "Open" 2 "short to battery" 3 "short to ground";
VAL_ 841 EDS_HVIL_STS_RWD 0 "Closed" 1 "Open" 2 "short to battery" 3 "short to ground";
VAL_ 842 ADAS_OBJ03_Class 0 "Unknown" 1 "Car" 2 "Truck" 3 "Motorbike" 4 "bicycle" 5 "Pedestrian" 6 "truck or car" 7 "reserved";
VAL_ 842 ADAS_OBJ03_Lane 0 "Undefined" 1 "Left lane" 2 "Host lane" 3 "Right lane";
VAL_ 844 ADAS_OBJ04_Class 0 "Unknown" 1 "Car" 2 "Truck" 3 "Motorbike" 4 "bicycle" 5 "Pedestrian" 6 "truck or car" 7 "reserved";
VAL_ 844 ADAS_OBJ04_Lane 0 "Undefined" 1 "Left lane" 2 "Host lane" 3 "Right lane";
VAL_ 845 ADAS_OBJ05_Class 0 "Unknown" 1 "Car" 2 "Truck" 3 "Motorbike" 4 "bicycle" 5 "Pedestrian" 6 "truck or car" 7 "reserved";
VAL_ 845 ADAS_OBJ05_Lane 0 "Undefined" 1 "Left lane" 2 "Host lane" 3 "Right lane";
VAL_ 846 ADAS_OBJ06_Class 0 "Unknown" 1 "Car" 2 "Truck" 3 "Motorbike" 4 "bicycle" 5 "Pedestrian" 6 "truck or car" 7 "reserved";
VAL_ 846 ADAS_OBJ06_Lane 0 "Undefined" 1 "Left lane" 2 "Host lane" 3 "Right lane";
VAL_ 849 ADAS_PA_AutoOn_Feed 0 "Off" 1 "On";
VAL_ 849 ADAS_PA_AlertFRI 0 "Off" 1 "1st warning" 2 "2nd warning" 3 "3rd warning" 4 "4th warning" 5 "5th warning" 6 "Reserved" 7 "Error";
VAL_ 849 ADAS_PA_AlertFLI 0 "Off" 1 "1st warning" 2 "2nd warning" 3 "3rd warning" 4 "4th warning" 5 "5th warning" 6 "Reserved" 7 "Error";
VAL_ 849 ADAS_PA_AlertFLO 0 "Off" 1 "1st warning" 2 "2nd warning" 3 "3rd warning" 4 "4th warning" 5 "5th warning" 6 "Reserved" 7 "Error";
VAL_ 849 ADAS_PA_AlertRLO 0 "Off" 1 "1st warning" 2 "2nd warning" 3 "3rd warning" 4 "4th warning" 5 "5th warning" 6 "Reserved" 7 "Error";
VAL_ 849 ADAS_PA_AlertRLI 0 "Off" 1 "1st warning" 2 "2nd warning" 3 "3rd warning" 4 "4th warning" 5 "5th warning" 6 "Reserved" 7 "Error";
VAL_ 849 ADAS_PA_AlertFRO 0 "Off" 1 "1st warning" 2 "2nd warning" 3 "3rd warning" 4 "4th warning" 5 "5th warning" 6 "Reserved" 7 "Error";
VAL_ 849 ADAS_PA_AlertRRO 0 "Off" 1 "1st warning" 2 "2nd warning" 3 "3rd warning" 4 "4th warning" 5 "5th warning" 6 "Reserved" 7 "Error";
VAL_ 849 ADAS_PA_AlertRRI 0 "Off" 1 "1st warning" 2 "2nd warning" 3 "3rd warning" 4 "4th warning" 5 "5th warning" 6 "Reserved" 7 "Error";
VAL_ 849 ADAS_PA_state 0 "OFF State" 1 "Stand by state" 2 "Active state" 3 "Failed state";
VAL_ 850 ADAS_AHB_sens_Feed 0 "Early" 1 "Normal" 2 "Late" 3 "reserved";
VAL_ 850 ADAS_AHB_Mode_Feed 0 "Off" 1 "On";
VAL_ 850 ADAS_AHB_check 0 "Available" 1 "Temporarily not available" 2 "Permanently not available";
VAL_ 850 ADAS_AHB_state 0 "OFF State" 1 "HighBeam Passive or Inactive" 2 "HighBeam Active" 3 "Fault";
VAL_ 850 ADAS_DOW_WarnRight 0 "No warning" 1 "Warning Level 1" 2 "Warning Level 2" 3 "Reserved";
VAL_ 850 ADAS_DOW_SndWarn 0 "Sound Warning disable" 1 "Left Sound Warning enable" 2 "Right Sound Warning enable" 3 "Left and Right Sound Warning enable";
VAL_ 850 ADAS_DOW_state 0 "OFF State" 1 "Stand by state" 2 "Armed state" 3 "Warning stage" 4 "Malfunction stage";
VAL_ 850 ADAS_DOW_check 0 "Available" 1 "Temporarily not available" 2 "Permanently not available";
VAL_ 850 ADAS_DOW_WarnLeft 0 "No warning" 1 "Warning Level 1" 2 "Warning Level 2" 3 "Reserved";
VAL_ 850 ADAS_DOW_Mode_Feed 0 "Off" 1 "Warning Only" 2 "Warning/Door Lock both" 3 "Reserved";
VAL_ 850 ADAS_AHB_RBPos 0 "Off or low beam" 1 "high beam" 2 "Reserved" 3 "Reserved" 4 "Reserved" 5 "Reserved" 6 "Reserved" 7 "Reserved";
VAL_ 850 ADAS_AHB_LBPos 0 "Off or low beam" 1 "high beam" 2 "Reserved" 3 "Reserved" 4 "Reserved" 5 "Reserved" 6 "Reserved" 7 "Reserved";
VAL_ 851 ADAS_ACC_ObjDetec 0 "Lead Object Not detected" 1 "Lead Object detected";
VAL_ 851 ADAS_ISA_check 0 "Available" 1 "Temporarily not available" 2 "Permanently not available";
VAL_ 851 ADAS_ISA_Mode_SW_Feed 0 "Off" 1 "On";
VAL_ 851 ADAS_TagSpeed_ICON_Feed 0 "Off" 1 "Gray ICON" 2 "Green ICON" 3 "White ICON" 4 "Yellow ICON" 5 "Red ICON";
VAL_ 851 ADAS_ISA_PopUp_Feed 0 "-" 1 "Accelerating to match speed limit" 2 "Decelerating to match speed limit" 3 "Press steering wheel button to match speed limit" 4 "Intelligent Speed Assist Unavailable" 5 "Reserved" 6 "Reserved" 7 "Reserved" 8 "Reserved" 9 "Reserved" 10 "Reserved" 11 "Reserved" 12 "Reserved" 13 "Reserved" 14 "Reserved" 15 "Invalid";
VAL_ 851 ADAS_ISA_Btn_Feed 0 "Off" 1 "On";
VAL_ 851 ADAS_ACC_DistSet_upper_Feed 0 "-" 1 "Up_Feed";
VAL_ 851 ADAS_ACC_TimeGapSet 0 "No time gap" 1 "1st level distance" 2 "2nd level distance" 3 "3rd level distance" 4 "4th level distance" 5 "Reserved" 6 "Reserved";
VAL_ 851 ADAS_ACC_State 0 "OFF State or Passive" 1 "Stand by state" 2 "Active" 3 "Override" 4 "Brake Only" 5 "Standstill Active" 6 "Standstill Wait" 7 "Fault";
VAL_ 851 ADAS_ACC_PopUp_Feed 0 "-" 1 "None (Feature On)" 2 "None (Feature Off)" 3 "Press gas pedal to re-engage the function" 4 "Speed Assist is unavailable Conditions not met" 5 "Resume not available Please activate Speed Assist button" 6 "Speed Assist is unavailable See Fault Details for more ingo" 7 "Speed Assist will off below 20kph. Issue with vehicle sensors" 8 "Take over driving now!" 9 "Take over driving now!Speed Assist Off";
VAL_ 851 ADAS_ACC_check 0 "Available" 1 "Temporarily not available" 2 "Permanently not available";
VAL_ 851 ADAS_ISA_ICON_Feed 0 "Off" 1 "Gray ICON" 2 "Green ICON" 3 "White ICON" 4 "Yellow ICON" 5 "Red ICON";
VAL_ 851 ADAS_ACC_DistSet_lower_Feed 0 "-" 1 "Down_Feed";
VAL_ 851 ADAS_ACC_SpdSet_upper_Feed 0 "-" 1 "Up_Feed";
VAL_ 851 ADAS_ACC_SpdSet_lower_Feed 0 "-" 1 "Down_Feed";
VAL_ 851 ADAS_ACC_On_Feed 0 "Off" 1 "On";
VAL_ 851 ADAS_ACC_Set_Feed 0 "-" 1 "Set_Feed";
VAL_ 851 ADAS_ACC_CnlBtn_Feed 0 "-" 1 "Cancel_Feed";
VAL_ 851 ADAS_ACC_Res_Feed 0 "-" 1 "Res_Feed";
VAL_ 851 ADAS_ACC_ICON_Feed 0 "Off" 1 "Gray ICON" 2 "Green ICON" 3 "White ICON" 4 "Yellow ICON" 5 "Red ICON";
VAL_ 851 ADAS_ISA_Status 0 "OFF State" 1 "Stand by state" 2 "Active(Auto) state" 3 "Reserved" 4 "Reserved";

SIG_GROUP_  532 SG_BMS_2_MHU 1 : BMS_Display_SOC Checksum_0x214 Rolling_Counter_0x214;
